VERSION ""

NS_ :

BS_:

BU_: HIB SaGE CBC DASM DIAGNOST EBCM ECM EPSB ESC ESL HALF HCP IC OCM ORC PTS RF_HUB SCCM

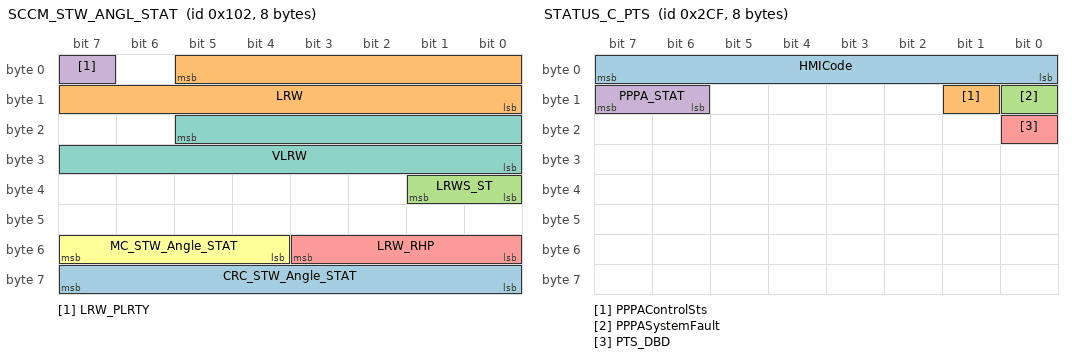
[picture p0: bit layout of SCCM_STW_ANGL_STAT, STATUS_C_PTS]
BO_ 258 SCCM_STW_ANGL_STAT: 8 SCCM
 SG_ CRC_STW_Angle_STAT : 56|8@1+ (1,0) [0|0] ""  DASM,ECM,ESC,ORC,PTS
 SG_ LRW : 5|14@0+ (0.5,-2048) [-2048|2047] "Degrees"  CBC,DASM,ECM,EPSB,ESC,HALF,ORC,PTS
 SG_ LRWS_ST : 32|2@1+ (1,0) [0|0] ""  CBC,DASM,ESC,HALF,ORC,PTS
 SG_ LRW_PLRTY : 7|1@1+ (1,0) [0|0] ""  DASM,ESC,HALF,ORC,PTS
 SG_ LRW_RHP : 48|4@1+ (0.1,-0.4) [-0.4|0.4] "Degrees"  EPSB,HALF,PTS
 SG_ MC_STW_Angle_STAT : 52|4@1+ (1,0) [0|15] ""  DASM,ECM,ESC,ORC,PTS
 SG_ VLRW : 21|14@0+ (0.5,-2048) [-2048|2047] "°/s"  DASM,ECM,EPSB,HALF

BO_ 1555 SD_RS_DASM: 8 DASM
 SG_ SD_RS_DASM : 7|64@0+ (1,0) [0|0] "" Vector__XXX

BO_ 1562 SD_RS_EPS: 8 EPSB
 SG_ SD_RS_EPS : 7|64@0+ (1,0) [0|0] "" Vector__XXX

BO_ 1572 SD_RS_HaLF: 8 HALF
 SG_ SD_RS_HaLF : 7|64@0+ (1,0) [0|0] "" Vector__XXX

BO_ 1570 SD_RS_PTS: 8 PTS
 SG_ SD_RS_PTS : 7|64@0+ (1,0) [0|0] "" Vector__XXX

BO_ 719 STATUS_C_PTS: 8 PTS
 SG_ HMICode : 0|8@1+ (1,0) [0|0] ""  IC
 SG_ PPPAControlSts : 9|1@1+ (1,0) [0|0] ""  ECM,IC
 SG_ PPPASystemFault : 8|1@1+ (1,0) [0|0] ""  IC
 SG_ PPPA_STAT : 14|2@1+ (1,0) [0|0] ""  CBC
 SG_ PTS_DBD : 16|1@1+ (1,0) [0|0] ""  IC

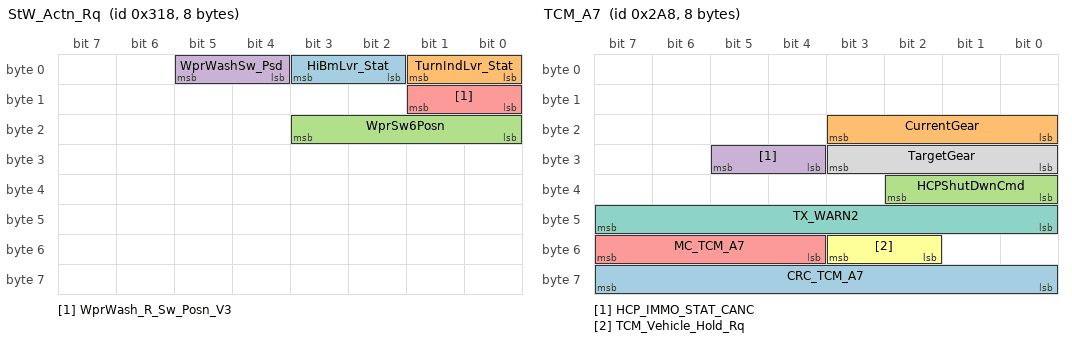
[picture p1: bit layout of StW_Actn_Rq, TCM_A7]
BO_ 792 StW_Actn_Rq: 8 SCCM
 SG_ HiBmLvr_Stat : 2|2@1+ (1,0) [0|0] ""  CBC
 SG_ TurnIndLvr_Stat : 0|2@1+ (1,0) [0|0] ""  CBC,DASM,HALF,PTS
 SG_ WprSw6Posn : 16|4@1+ (1,0) [0|0] ""  CBC,DASM
 SG_ WprWashSw_Psd : 4|2@1+ (1,0) [0|0] ""  CBC
 SG_ WprWash_R_Sw_Posn_V3 : 8|2@1+ (1,0) [0|0] ""  CBC

BO_ 680 TCM_A7: 8 HCP
 SG_ CRC_TCM_A7 : 56|8@1+ (1,0) [0|0] ""  DASM,ECM,ESC
 SG_ CurrentGear : 16|4@1+ (1,0) [0|0] "" Vector__XXX
 SG_ HCPShutDwnCmd : 32|3@1+ (1,0) [0|0] ""  CBC
 SG_ HCP_IMMO_STAT_CANC : 28|2@1+ (1,0) [0|0] ""  CBC,ECM
 SG_ MC_TCM_A7 : 52|4@1+ (1,0) [0|15] ""  DASM,ECM,ESC
 SG_ TCM_Vehicle_Hold_Rq : 50|2@1+ (1,0) [0|0] ""  ESC
 SG_ TX_WARN2 : 40|8@1+ (1,0) [0|0] ""  IC
 SG_ TargetGear : 24|4@1+ (1,0) [0|0] "" Vector__XXX

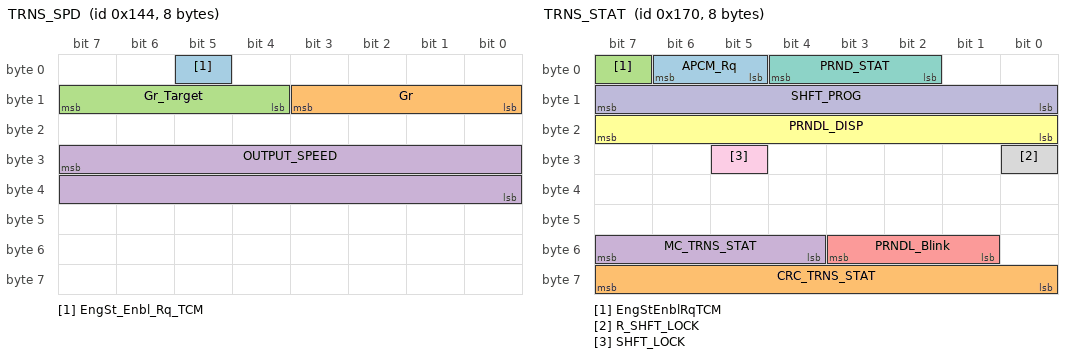
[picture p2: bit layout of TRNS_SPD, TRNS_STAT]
BO_ 324 TRNS_SPD: 8 HCP
 SG_ EngSt_Enbl_Rq_TCM : 5|1@1+ (1,0) [0|0] ""  ECM,RF_HUB
 SG_ Gr : 8|4@1+ (1,0) [0|0] ""  CBC,ECM,EPSB,ESC,HALF,IC,ORC,RF_HUB
 SG_ Gr_Target : 12|4@1+ (1,0) [0|0] ""  CBC,ECM,ESC
 SG_ OUTPUT_SPEED : 31|16@0+ (1,0) [0|65534] "rpm"  ECM

BO_ 368 TRNS_STAT: 8 HCP
 SG_ APCM_Rq : 5|2@1+ (1,0) [0|0] "" Vector__XXX
 SG_ CRC_TRNS_STAT : 56|8@1+ (1,0) [0|0] ""  DASM,ECM,ESC,PTS
 SG_ EngStEnblRqTCM : 7|1@1+ (1,0) [0|0] "" Vector__XXX
 SG_ MC_TRNS_STAT : 52|4@1+ (1,0) [0|15] ""  DASM,ECM,ESC,PTS
 SG_ PRNDL_Blink : 49|3@1+ (1,0) [0|0] ""  IC
 SG_ PRNDL_DISP : 16|8@1+ (1,0) [0|0] ""  CBC,ECM,ESC,IC,ORC
 SG_ PRND_STAT : 2|3@1+ (1,0) [0|0] ""  CBC,DASM,ECM,EPSB,ESC,IC,ORC,PTS
 SG_ R_SHFT_LOCK : 24|1@1+ (1,0) [0|0] "" Vector__XXX
 SG_ SHFT_LOCK : 29|1@1+ (1,0) [0|0] "" Vector__XXX
 SG_ SHFT_PROG : 8|8@1+ (1,0) [0|0] ""  ECM,ESC

BO_ 992 VIN: 8 ECM
 SG_ VIN_DATA : 15|56@0+ (1,0) [0|0] ""  CBC,DASM,EBCM,EPSB,ESC,ESL,HALF,HCP,IC,OCM,ORC,PTS,RF_HUB,SCCM
 SG_ VIN_MSG : 0|2@1+ (1,0) [0|0] ""  CBC,DASM,EBCM,EPSB,ESC,ESL,HALF,HCP,IC,OCM,ORC,PTS,RF_HUB,SCCM

BO_ 1000 VehCfg1: 8 CBC
 SG_ VC_AUTO_HB : 27|1@1+ (1,0) [0|0] ""  HALF,RF_HUB
 SG_ VC_BODY_STYLE : 28|4@1+ (1,0) [0|0] ""  DASM,EBCM,ECM,EPSB,ESC,ESL,HALF,HCP,IC,OCM,ORC,PTS,RF_HUB,SCCM
 SG_ VC_CHMCM_Prsnt : 61|1@1+ (1,0) [0|0] ""  RF_HUB
 SG_ VC_COUNTRY : 16|5@1+ (1,0) [0|0] ""  DASM,EBCM,ECM,EPSB,ESC,ESL,HALF,HCP,IC,OCM,ORC,PTS,RF_HUB,SCCM
 SG_ VC_EmodePrsnt : 26|1@1+ (1,0) [0|0] ""  RF_HUB
 SG_ VC_HDC_Prsnt : 62|1@1+ (1,0) [0|0] ""  RF_HUB
 SG_ VC_HdRstPrsnt : 56|1@1+ (1,0) [0|0] ""  RF_HUB
 SG_ VC_LHD_RHD : 21|2@1+ (1,0) [0|0] ""  ESC,HALF,IC,PTS,RF_HUB
 SG_ VC_MAX_VEH_SPD : 32|8@1+ (2,0) [0|506] "kph"  RF_HUB
 SG_ VC_MODEL_YEAR : 2|6@1+ (1,2000) [2000|2062] "model-year"  DASM,EBCM,ECM,EPSB,ESC,ESL,HALF,HCP,IC,OCM,ORC,PTS,RF_HUB,SCCM
 SG_ VC_PP_Prsnt : 47|1@1+ (1,0) [0|0] ""  RF_HUB
 SG_ VC_PTS_Config : 58|2@1+ (1,0) [0|0] ""  IC,RF_HUB
 SG_ VC_PTS_DispTyp : 44|3@1+ (1,0) [0|0] ""  RF_HUB
 SG_ VC_RVCM_Prsnt : 60|1@1+ (1,0) [0|0] ""  RF_HUB
 SG_ VC_RemStPrsnt : 23|1@1+ (1,0) [0|0] ""  HCP,IC,RF_HUB
 SG_ VC_SCR_Prsnt : 57|1@1+ (1,0) [0|0] ""  RF_HUB
 SG_ VC_SSC_Prsnt : 63|1@1+ (1,0) [0|0] ""  RF_HUB
 SG_ VC_ShftrTyp : 40|4@1+ (1,0) [0|0] ""  HCP,IC,RF_HUB
 SG_ VC_SpecialPKG : 48|8@1+ (1,0) [1|254] ""  RF_HUB
 SG_ VC_VEH_LINE : 8|8@1+ (1,0) [0|0] ""  DASM,EBCM,ECM,EPSB,ESC,ESL,HALF,HCP,IC,OCM,ORC,PTS,RF_HUB,SCCM
 SG_ VC_VehCfg1_Stat : 0|2@1+ (1,0) [0|0] ""  DASM,EBCM,ECM,EPSB,ESC,ESL,HALF,HCP,IC,OCM,ORC,PTS,RF_HUB,SCCM
 SG_ VC_XWD : 24|2@1+ (1,0) [0|0] ""  DASM,ESC,HALF,ORC,RF_HUB

BO_ 1001 VehCfg2: 8 CBC
 SG_ VC_AC_Prsnt : 11|1@1+ (1,0) [0|0] ""  RF_HUB
 SG_ VC_CRUISE_PRSNT : 12|1@1+ (1,0) [0|0] ""  DASM,HCP,ORC,RF_HUB,SCCM
 SG_ VC_DRVMD_Prsnt : 25|1@1+ (1,0) [0|0] ""  RF_HUB
 SG_ VC_ECO_Indicator : 24|1@1+ (1,0) [0|0] ""  RF_HUB
 SG_ VC_ESCDrvMd_Prsnt : 27|1@1+ (1,0) [0|0] ""  RF_HUB
 SG_ VC_EngPowerDrvMd_Prsnt : 28|1@1+ (1,0) [0|0] ""  RF_HUB
 SG_ VC_FG_PRSNT : 13|1@1+ (1,0) [0|0] ""  RF_HUB
 SG_ VC_FULL_SPARE : 14|1@1+ (1,0) [0|0] ""  RF_HUB
 SG_ VC_LgtLdPressFtTr : 56|8@1+ (1,0) [0|126] "psi"  RF_HUB
 SG_ VC_LgtLdPressRrTr : 48|8@1+ (1,0) [0|126] "psi"  RF_HUB
 SG_ VC_MaseratiMd : 6|2@1+ (1,0) [0|0] ""  RF_HUB
 SG_ VC_MaxLdPressFtTr : 40|8@1+ (1,0) [0|126] "psi"  IC,RF_HUB
 SG_ VC_MaxLdPressRrTr : 32|8@1+ (1,0) [0|126] "psi"  IC,RF_HUB
 SG_ VC_MemoryDRVMD_Prsnt : 26|1@1+ (1,0) [0|0] ""  RF_HUB
 SG_ VC_OffRoad : 15|1@1+ (1,0) [0|0] ""  RF_HUB
 SG_ VC_PADS_Prsnt : 8|1@1+ (1,0) [0|0] ""  ORC,RF_HUB
 SG_ VC_PwrIvtrTyp : 2|2@1+ (1,0) [0|0] ""  RF_HUB
 SG_ VC_RainSnsPrsnt : 9|1@1+ (1,0) [0|0] ""  RF_HUB
 SG_ VC_RunFlatTirePrsnt : 5|1@1+ (1,0) [0|0] ""  RF_HUB
 SG_ VC_SKIM_PRSNT : 10|1@1+ (1,0) [0|0] ""  RF_HUB
 SG_ VC_SecPrkPrsnt : 29|1@1+ (1,0) [0|0] ""  RF_HUB
 SG_ VC_ShftInd_Prsnt : 30|2@1+ (1,0) [0|0] ""  RF_HUB
 SG_ VC_SpecialPKG_IC : 16|8@1+ (1,0) [0|0] ""  ORC,RF_HUB
 SG_ VC_ThatchamPrsnt : 4|1@1+ (1,0) [0|0] ""  RF_HUB
 SG_ VC_VehCfg2_Stat : 0|2@1+ (1,0) [0|0] ""  DASM,ECM,EPSB,ESC,HCP,IC,ORC,RF_HUB,SCCM

BO_ 1002 VehCfg3: 8 CBC
 SG_ VC_ADJ_PDL_PRSNT : 26|1@1+ (1,0) [0|0] ""  RF_HUB
 SG_ VC_AUTO_HL : 27|1@1+ (1,0) [0|0] ""  RF_HUB
 SG_ VC_AutoParkPrsnt : 61|1@1+ (1,0) [0|0] ""  RF_HUB
 SG_ VC_Base_TPM : 57|1@1+ (1,0) [0|0] ""  IC,ORC,RF_HUB
 SG_ VC_CMP_DISP : 48|1@1+ (1,0) [0|0] ""  IC,RF_HUB
 SG_ VC_CMS : 55|1@1+ (1,0) [0|0] ""  DASM,ESC,HALF,ORC,RF_HUB
 SG_ VC_ChassisType : 32|7@1+ (1,0) [0|126] ""  ESC,HALF,RF_HUB
 SG_ VC_DSBL_CLK_DISP : 31|1@1+ (1,0) [0|0] ""  RF_HUB
 SG_ VC_DrAlrPrsnt : 28|1@1+ (1,0) [0|0] ""  RF_HUB
 SG_ VC_DualFuelSens : 29|1@1+ (1,0) [0|0] ""  IC,RF_HUB
 SG_ VC_ELV_Prsnt : 15|1@1+ (1,0) [0|0] ""  RF_HUB
 SG_ VC_ESCL_PRSNT : 50|1@1+ (1,0) [0|0] ""  RF_HUB
 SG_ VC_FCW : 56|1@1+ (1,0) [0|0] ""  DASM,ESC,HALF,ORC,RF_HUB
 SG_ VC_FOBIKsafeENBL : 14|1@1+ (1,0) [0|0] ""  RF_HUB
 SG_ VC_FUEL_CAP : 16|8@1+ (1,36) [36|290] "liters"  IC,RF_HUB
 SG_ VC_HID_HL : 51|1@1+ (1,0) [0|0] ""  RF_HUB
 SG_ VC_HVAC_Config : 40|4@1+ (1,0) [0|0] ""  RF_HUB
 SG_ VC_IntEC_MIRR : 49|1@1+ (1,0) [0|0] ""  RF_HUB
 SG_ VC_KG_Prsnt : 63|1@1+ (1,0) [0|0] ""  IC,RF_HUB
 SG_ VC_Liftgate_Trunk : 53|2@1+ (1,0) [0|0] ""  IC,RF_HUB
 SG_ VC_PDDL_PRSNT : 59|1@1+ (1,0) [0|0] ""  RF_HUB
 SG_ VC_PE_Prsnt : 62|1@1+ (1,0) [0|0] ""  RF_HUB
 SG_ VC_POLICE : 2|1@1+ (1,0) [0|0] ""  ORC,RF_HUB
 SG_ VC_PWR_LFT_GT : 3|1@1+ (1,0) [0|0] ""  RF_HUB
 SG_ VC_PWR_LT_SLDR : 5|1@1+ (1,0) [0|0] ""  RF_HUB
 SG_ VC_PWR_RT_SLDR : 4|1@1+ (1,0) [0|0] ""  RF_HUB
 SG_ VC_Prem_TPM : 58|1@1+ (1,0) [0|0] ""  IC,ORC,RF_HUB
 SG_ VC_RKE_PRSNT : 6|1@1+ (1,0) [0|0] ""  RF_HUB
 SG_ VC_SPORT_PRSNT : 60|1@1+ (1,0) [0|0] ""  RF_HUB
 SG_ VC_SRT_PRSNT : 30|1@1+ (1,0) [0|0] ""  ORC,RF_HUB
 SG_ VC_SecLkPrsnt : 52|1@1+ (1,0) [0|0] ""  RF_HUB
 SG_ VC_SunShade_Present : 7|1@1+ (1,0) [0|0] ""  RF_HUB
 SG_ VC_TEMP_DISP : 39|1@1+ (1,0) [0|0] ""  IC,RF_HUB
 SG_ VC_TcaseTyp : 8|4@1+ (1,0) [0|0] ""  ESC,RF_HUB
 SG_ VC_VEH_BRAND : 44|4@1+ (1,0) [0|0] ""  HALF,PTS,RF_HUB
 SG_ VC_VehCfg3_Stat : 0|2@1+ (1,0) [0|0] ""  DASM,ECM,EPSB,ESC,HALF,HCP,IC,ORC,PTS,RF_HUB,SCCM
 SG_ VC_WHL_BASE : 12|2@1+ (1,0) [0|0] ""  IC,RF_HUB
 SG_ VC_WIN_EXPR_FEAT : 24|2@1+ (1,0) [0|0] ""  RF_HUB

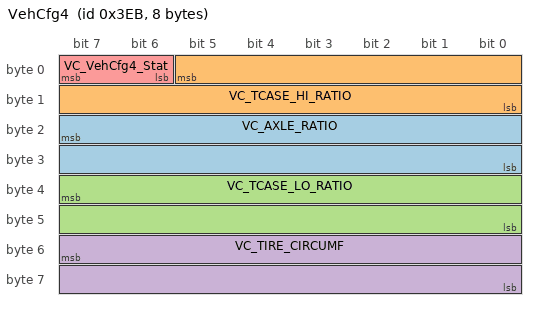
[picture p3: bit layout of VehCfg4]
BO_ 1003 VehCfg4: 8 CBC
 SG_ VC_AXLE_RATIO : 23|16@0+ (0.001,0) [0|65.534] ""  DASM,ESC,RF_HUB
 SG_ VC_TCASE_HI_RATIO : 5|14@0+ (0.001,0) [0|16.382] ""  ESC,RF_HUB
 SG_ VC_TCASE_LO_RATIO : 39|16@0+ (0.001,0) [0|65.534] ""  ESC,RF_HUB
 SG_ VC_TIRE_CIRCUMF : 55|16@0+ (1,0) [0|65534] "mm"  EPSB,ESC,HALF,ORC,PTS,RF_HUB
 SG_ VC_VehCfg4_Stat : 6|2@1+ (1,0) [0|0] ""  DASM,ECM,EPSB,ESC,HALF,HCP,ORC,PTS,RF_HUB

BO_ 1098 VehCfg5: 8 CBC
 SG_ VC_AmbLtgPrsnt : 61|1@1+ (1,0) [0|0] ""  RF_HUB
 SG_ VC_AmbTempLct : 6|2@1+ (1,0) [0|0] ""  RF_HUB
 SG_ VC_ChildDisp_Prsnt : 59|1@1+ (1,0) [0|0] ""  RF_HUB
 SG_ VC_LUCI_PRSNT : 2|1@1+ (1,0) [0|0] ""  RF_HUB
 SG_ VC_NonReg_TPIS : 4|1@1+ (1,0) [0|0] ""  RF_HUB
 SG_ VC_OffRoadPg : 60|1@1+ (1,0) [0|0] ""  RF_HUB
 SG_ VC_PPPA_Prsnt : 62|1@1+ (1,0) [0|0] ""  EPSB,IC,PTS,RF_HUB
 SG_ VC_ParkStopPrsnt : 63|1@1+ (1,0) [0|0] ""  ESC,IC,RF_HUB
 SG_ VC_RR_DuallyPrsnt : 3|1@1+ (1,0) [0|0] ""  RF_HUB
 SG_ VC_RearDoorLocks2DCM : 56|1@1+ (1,0) [0|0] ""  RF_HUB
 SG_ VC_SBR_Prsnt : 58|1@1+ (1,0) [0|0] ""  RF_HUB
 SG_ VC_SpdLmt_PRSNT : 57|1@1+ (1,0) [0|0] ""  DASM,RF_HUB,SCCM
 SG_ VC_Strng_Rt_0 : 8|8@1+ (0.1,0) [0|25.4] ""  ESC,RF_HUB
 SG_ VC_Strng_Rt_pls1 : 16|8@1+ (0.1,0) [0|25.4] ""  ESC,RF_HUB
 SG_ VC_Strng_Rt_pls2 : 24|8@1+ (0.1,0) [0|25.4] ""  ESC,RF_HUB
 SG_ VC_Strng_Rt_pls3 : 32|8@1+ (0.1,0) [0|25.4] ""  ESC,RF_HUB
 SG_ VC_Strng_Rt_pls4 : 40|8@1+ (0.1,0) [0|25.4] ""  ESC,RF_HUB
 SG_ VC_Strng_Rt_pls5 : 48|8@1+ (0.1,0) [0|25.4] ""  ESC,RF_HUB
 SG_ VC_VehCfg5_Stat : 0|2@1+ (1,0) [0|0] ""  DASM,ECM,EPSB,ESC,IC,ORC,PTS,RF_HUB,SCCM
 SG_ VC_WTS_Prsnt : 5|1@1+ (1,0) [0|0] ""  RF_HUB

BO_ 897 VehCfg7: 8 CBC
 SG_ VC_ABSM : 25|1@1+ (1,0) [0|0] ""  RF_HUB
 SG_ VC_ACC_Type : 19|2@1+ (1,0) [0|0] ""  DASM,ECM,ESC,HALF,IC,ORC,PTS,RF_HUB
 SG_ VC_AS_ERS : 14|2@1+ (1,0) [0|0] ""  RF_HUB
 SG_ VC_AxleLockerPrsnt : 26|2@1+ (1,0) [0|0] ""  RF_HUB
 SG_ VC_DST_Present : 5|1@1+ (1,0) [0|0] ""  RF_HUB
 SG_ VC_DampingPrsnt : 22|1@1+ (1,0) [0|0] ""  RF_HUB
 SG_ VC_FullSpeedRange_FCW : 18|1@1+ (1,0) [0|0] ""  DASM,ESC,HALF,RF_HUB
 SG_ VC_HybridType : 36|3@1+ (1,0) [0|0] ""  DASM,ECM,EPSB,ESC,HALF,IC,ORC,PTS,RF_HUB
 SG_ VC_LDW : 2|1@1+ (1,0) [0|0] ""  HALF,IC,ORC,RF_HUB
 SG_ VC_PBTyp : 29|3@1+ (1,0) [0|0] ""  ESC,ORC,PTS,RF_HUB
 SG_ VC_PdlsMdPrsnt : 4|1@1+ (1,0) [0|0] ""  RF_HUB
 SG_ VC_RedKey : 24|1@1+ (1,0) [0|0] ""  RF_HUB
 SG_ VC_STP_PRSNT : 6|1@1+ (1,0) [0|0] ""  RF_HUB
 SG_ VC_SUNR_Prsnt : 47|1@1+ (1,0) [0|0] ""  RF_HUB
 SG_ VC_SVC_Prsnt : 17|1@1+ (1,0) [0|0] ""  RF_HUB
 SG_ VC_SuspPrsnt : 21|1@1+ (1,0) [0|0] ""  RF_HUB
 SG_ VC_TPMS_Configuration : 32|3@1+ (1,0) [0|0] ""  IC,RF_HUB
 SG_ VC_TSBM_Prsnt : 39|1@1+ (1,0) [0|0] ""  RF_HUB
 SG_ VC_TeenKey : 16|1@1+ (1,0) [0|0] ""  DASM,ECM,IC,PTS,RF_HUB
 SG_ VC_Temp_Display_Resolution : 42|1@1+ (1,0) [0|0] ""  RF_HUB
 SG_ VC_TransType : 8|6@1+ (1,0) [0|0] ""  ESC,IC,RF_HUB
 SG_ VC_Trans_Equipped : 28|1@1+ (1,0) [0|0] ""  EPSB,ESC,HALF,IC,ORC,PTS,RF_HUB
 SG_ VC_Trans_N_Hold_Prsnt : 23|1@1+ (1,0) [0|0] ""  RF_HUB
 SG_ VC_TrnsDrvMdPrsnt : 3|1@1+ (1,0) [0|0] ""  RF_HUB
 SG_ VC_VehCfg7_Stat : 0|2@1+ (1,0) [0|0] ""  DASM,ECM,EPSB,HALF,IC,ORC,PTS,RF_HUB
 SG_ VC_eShifter_Prsnt : 7|1@1+ (1,0) [0|0] ""  ESC,RF_HUB

CM_ SG_ 258 CRC_STW_Angle_STAT "CRC-checksum byte 1 to 7 according to SAE J1850";
CM_ SG_ 258 LRW "Steering wheel angle";
CM_ SG_ 258 LRWS_ST "Steering wheel angle sensor status";
CM_ SG_ 258 LRW_PLRTY "Steering angle polarity (0=ISO 8855 Polarity and CCW = Positive)";
CM_ SG_ 258 LRW_RHP "Steering wheel angle remainder high precision";
CM_ SG_ 258 MC_STW_Angle_STAT "Message counter";
CM_ SG_ 258 VLRW "Delta steering wheel angle";
CM_ SG_ 1555 SD_RS_DASM "Response on Event - light";
CM_ SG_ 1562 SD_RS_EPS "Response on Event - light";
CM_ SG_ 1572 SD_RS_HaLF "Response on Event - light";
CM_ SG_ 1570 SD_RS_PTS "Response on Event - light";
CM_ SG_ 719 HMICode "HMI codes to be displayed";
CM_ SG_ 719 PPPAControlSts "Indicates the active state of PPPA; active = [1]";
CM_ SG_ 719 PPPASystemFault "Indicates the fail status of PPPA; true = [1]";
CM_ SG_ 719 PPPA_STAT "Parallel & perpendicular park assist switch status";
CM_ SG_ 719 PTS_DBD "Park assist system disabled; System_Disabled = [1]";
CM_ SG_ 792 HiBmLvr_Stat "High beam lever state";
CM_ SG_ 792 TurnIndLvr_Stat "Turn indicator lever state";
CM_ SG_ 792 WprSw6Posn "Wiper switch (6 stages) position";
CM_ SG_ 792 WprWashSw_Psd "Front wiper switch pressed";
CM_ SG_ 792 WprWash_R_Sw_Posn_V3 "Backlite wiper/washer switch position";
CM_ SG_ 680 CRC_TCM_A7 "CRC-checksum byte 1 to 7 according to SAE J1850";
CM_ SG_ 680 CurrentGear "Current Gear";
CM_ SG_ 680 HCPShutDwnCmd "HCP System Shutdown Command";
CM_ SG_ 680 HCP_IMMO_STAT_CANC "Communicates immobilizer handshake status to BCM";
CM_ SG_ 680 MC_TCM_A7 "Message counter";
CM_ SG_ 680 TCM_Vehicle_Hold_Rq "Transmission request to hold the vehicle/apply the park brake";
CM_ SG_ 680 TX_WARN2 "Transmission warning #2";
CM_ SG_ 680 TargetGear "Target Gear - protected";
CM_ SG_ 324 EngSt_Enbl_Rq_TCM "Enable engine start request";
CM_ SG_ 324 Gr "Current Gear";
CM_ SG_ 324 Gr_Target "Target Gear";
CM_ SG_ 324 OUTPUT_SPEED "Output Shaft Speed";
CM_ SG_ 368 APCM_Rq "Auto position correction mode request";
CM_ SG_ 368 CRC_TRNS_STAT "CRC-checksum byte 1 to 7 according to SAE J1850";
CM_ SG_ 368 EngStEnblRqTCM "Engine start enable request from the transmission";
CM_ SG_ 368 MC_TRNS_STAT "Message counter";
CM_ SG_ 368 PRNDL_Blink "Request gear shift display indicator blink";
CM_ SG_ 368 PRNDL_DISP "PRNDL display request";
CM_ SG_ 368 PRND_STAT "PRND Status";
CM_ SG_ 368 R_SHFT_LOCK "Shiftlock for reverse; locked = [1]";
CM_ SG_ 368 SHFT_LOCK "Shiftlock state locked; false = [1]";
CM_ SG_ 368 SHFT_PROG "Driving program display code";
CM_ SG_ 992 VIN_DATA "VIN Digits (8 bit ascii encoded) - see Signal Description Doc for details";
CM_ SG_ 992 VIN_MSG "VIN Message Information";
CM_ SG_ 1000 VC_AUTO_HB "Auto Highbeam feature present; present = [1]";
CM_ SG_ 1000 VC_BODY_STYLE "Body style";
CM_ SG_ 1000 VC_CHMCM_Prsnt "CHMSL camera (1=present)";
CM_ SG_ 1000 VC_COUNTRY "Country Code";
CM_ SG_ 1000 VC_EmodePrsnt "E-Mode feature present; True = [1]";
CM_ SG_ 1000 VC_HDC_Prsnt "Hill descent feature is present; present = [1]";
CM_ SG_ 1000 VC_HdRstPrsnt "Headrest present; present = [1]";
CM_ SG_ 1000 VC_LHD_RHD "Left/right hand drive";
CM_ SG_ 1000 VC_MAX_VEH_SPD "Maximum vehicle speed";
CM_ SG_ 1000 VC_MODEL_YEAR "Model year";
CM_ SG_ 1000 VC_PP_Prsnt "Performance Pages Present (1=present)";
CM_ SG_ 1000 VC_PTS_Config "Parktronics system configuration";
CM_ SG_ 1000 VC_PTS_DispTyp "PTS display type and location";
CM_ SG_ 1000 VC_RVCM_Prsnt "Rear view camera (1=present)";
CM_ SG_ 1000 VC_RemStPrsnt "Remote start present; present = [1]";
CM_ SG_ 1000 VC_SCR_Prsnt "Urea/SCR system present; present = [1]";
CM_ SG_ 1000 VC_SSC_Prsnt "Select speed control feature is present; present = [1]";
CM_ SG_ 1000 VC_ShftrTyp "Shifter type";
CM_ SG_ 1000 VC_SpecialPKG "Special sales code package";
CM_ SG_ 1000 VC_VEH_LINE "Vehicle line";
CM_ SG_ 1000 VC_VehCfg1_Stat "Configuration messages status 1";
CM_ SG_ 1000 VC_XWD "Drive configuration";
CM_ SG_ 1001 VC_AC_Prsnt "Vehicle is equipped with air conditioning; present = [1]";
CM_ SG_ 1001 VC_CRUISE_PRSNT "Cruise feature is present; present = [1]";
CM_ SG_ 1001 VC_DRVMD_Prsnt "Drive mode feature configuration (1 = Present)";
CM_ SG_ 1001 VC_ECO_Indicator "ECO Indicator present on vehicle; True = [1]";
CM_ SG_ 1001 VC_ESCDrvMd_Prsnt "ESC drive mode sub-feature configuration (1 = Present)";
CM_ SG_ 1001 VC_EngPowerDrvMd_Prsnt "ECM drive mode sub-feature configuration (1 = Present)";
CM_ SG_ 1001 VC_FG_PRSNT "Flipper glass present; present = [1]";
CM_ SG_ 1001 VC_FULL_SPARE "Full size spare; present = [1]";
CM_ SG_ 1001 VC_LgtLdPressFtTr "Light Load Inflation Pressure Front Tire";
CM_ SG_ 1001 VC_LgtLdPressRrTr "Light Load Inflation Pressure Rear Tire";
CM_ SG_ 1001 VC_MaseratiMd "Maserati vehicle mode";
CM_ SG_ 1001 VC_MaxLdPressFtTr "Max Load Inflation Pressure Front Tire";
CM_ SG_ 1001 VC_MaxLdPressRrTr "Max Load Inflation Pressure Rear Tire";
CM_ SG_ 1001 VC_MemoryDRVMD_Prsnt "Memory drive mode sub-feature configuration (1 = Present)";
CM_ SG_ 1001 VC_OffRoad "Off road capable; present = [1]";
CM_ SG_ 1001 VC_PADS_Prsnt "Pass. airbag disable switch present; present = [1]";
CM_ SG_ 1001 VC_PwrIvtrTyp "Power inverter type";
CM_ SG_ 1001 VC_RainSnsPrsnt "Rain sensor present; present = [1]";
CM_ SG_ 1001 VC_RunFlatTirePrsnt "Run flat tires present; present = [1]";
CM_ SG_ 1001 VC_SKIM_PRSNT "SKIM system present; present = [1]";
CM_ SG_ 1001 VC_SecPrkPrsnt "Secure park feature present; present = [1]";
CM_ SG_ 1001 VC_ShftInd_Prsnt "Configuration for performance & gear shift indication";
CM_ SG_ 1001 VC_SpecialPKG_IC "Special sales code package";
CM_ SG_ 1001 VC_ThatchamPrsnt "Thatcham present; present = [1]";
CM_ SG_ 1001 VC_VehCfg2_Stat "Configuration messages status 2";
CM_ SG_ 1002 VC_ADJ_PDL_PRSNT "Adjustable pedal system present (non-memory); present = [1]";
CM_ SG_ 1002 VC_AUTO_HL "Auto headlamp feature present; present = [1]";
CM_ SG_ 1002 VC_AutoParkPrsnt "Automatic transmission parking feature is present; present = [1]";
CM_ SG_ 1002 VC_Base_TPM "Base TPM system present; present = [1]";
CM_ SG_ 1002 VC_CMP_DISP "Display compass heading present; present = [1]";
CM_ SG_ 1002 VC_CMS "Collision Mitigation System present; present = [1]";
CM_ SG_ 1002 VC_ChassisType "Chassis type (including suspension, brakes, and tires)";
CM_ SG_ 1002 VC_DSBL_CLK_DISP "Disable display of radio clock; 1 = clock display disabled";
CM_ SG_ 1002 VC_DrAlrPrsnt "Door alert feature present; present = [1]";
CM_ SG_ 1002 VC_DualFuelSens "Vehicle equipped with two fuel sending units; present = [1]";
CM_ SG_ 1002 VC_ELV_Prsnt "ELV system present; enabled=[1], disabled=[0]";
CM_ SG_ 1002 VC_ESCL_PRSNT "ESCL system present; enabled=[1], disabled=[0]";
CM_ SG_ 1002 VC_FCW "Forward Collision Warning present; present = [1]";
CM_ SG_ 1002 VC_FOBIKsafeENBL "Feature FOBIK safe is enabled; present = [1]";
CM_ SG_ 1002 VC_FUEL_CAP "Fuel capacity";
CM_ SG_ 1002 VC_HID_HL "High intensity discharge head lamps; present = [1]";
CM_ SG_ 1002 VC_HVAC_Config "HVAC Configuration";
CM_ SG_ 1002 VC_IntEC_MIRR "Vehicle is equipped with an interior EC mirror; present = [1]";
CM_ SG_ 1002 VC_KG_Prsnt "Feature keyless go is present; present = [1]";
CM_ SG_ 1002 VC_Liftgate_Trunk "Liftgate or trunk";
CM_ SG_ 1002 VC_PDDL_PRSNT "Paddle shift feature is present; present = [1]";
CM_ SG_ 1002 VC_PE_Prsnt "Feature passive entry is present; present = [1]";
CM_ SG_ 1002 VC_POLICE "Police lighting feature; present = [1]";
CM_ SG_ 1002 VC_PWR_LFT_GT "Power lift gate present; present = [1]";
CM_ SG_ 1002 VC_PWR_LT_SLDR "Power left sliding door present; present = [1]";
CM_ SG_ 1002 VC_PWR_RT_SLDR "Power right sliding door present; present = [1]";
CM_ SG_ 1002 VC_Prem_TPM "Premium TPM system present; present = [1]";
CM_ SG_ 1002 VC_RKE_PRSNT "RKE system present; present = [1]";
CM_ SG_ 1002 VC_SPORT_PRSNT "Sport mode is present; present = [1]";
CM_ SG_ 1002 VC_SRT_PRSNT "Vehicle is an SRT; present = [1]";
CM_ SG_ 1002 VC_SecLkPrsnt "Secondary Lock Present; [1] = True";
CM_ SG_ 1002 VC_SunShade_Present "Vehicle equipped w/SunShade (1=present)";
CM_ SG_ 1002 VC_TEMP_DISP "Display outside temperature present; present = [1]";
CM_ SG_ 1002 VC_TcaseTyp "Tcase type";
CM_ SG_ 1002 VC_VEH_BRAND "Vehicle brand type";
CM_ SG_ 1002 VC_VehCfg3_Stat "Configuration messages status 3";
CM_ SG_ 1002 VC_WHL_BASE "Wheel base";
CM_ SG_ 1002 VC_WIN_EXPR_FEAT "Window express feature configuration";
CM_ SG_ 1003 VC_AXLE_RATIO "Axle ratio";
CM_ SG_ 1003 VC_TCASE_HI_RATIO "Transfer case high ratio";
CM_ SG_ 1003 VC_TCASE_LO_RATIO "Transfer case low range reduction ratio";
CM_ SG_ 1003 VC_TIRE_CIRCUMF "Dynamic tire circumference (all or rear)";
CM_ SG_ 1003 VC_VehCfg4_Stat "Configuration messages status 4";
CM_ SG_ 1098 VC_AmbLtgPrsnt "Ambient lighting feature is present; True = [1]";
CM_ SG_ 1098 VC_AmbTempLct "Ambient temperature sensor location";
CM_ SG_ 1098 VC_ChildDisp_Prsnt "Child display feature is present; True = 1";
CM_ SG_ 1098 VC_LUCI_PRSNT "Luci feature present; present = [1]";
CM_ SG_ 1098 VC_NonReg_TPIS "Non-regulated tire pressure indicator system; True = 1";
CM_ SG_ 1098 VC_OffRoadPg "Off road pages present; True = [1]";
CM_ SG_ 1098 VC_PPPA_Prsnt "Semi automatic parking system present; present = [1]";
CM_ SG_ 1098 VC_ParkStopPrsnt "Park with stop is present; True = 1";
CM_ SG_ 1098 VC_RR_DuallyPrsnt "Vehicle is equipped with rear duals; present = [1]";
CM_ SG_ 1098 VC_RearDoorLocks2DCM "Rear door lock switch present; present = [1]";
CM_ SG_ 1098 VC_SBR_Prsnt "Seat belt reminder module is present; True = 1";
CM_ SG_ 1098 VC_SpdLmt_PRSNT "Speed limiter is present; present = [1]";
CM_ SG_ 1098 VC_Strng_Rt_0 "Steering Ratio at zero";
CM_ SG_ 1098 VC_Strng_Rt_pls1 "Steering Ratio at positve angle 1";
CM_ SG_ 1098 VC_Strng_Rt_pls2 "Steering Ratio at positve angle 2";
CM_ SG_ 1098 VC_Strng_Rt_pls3 "Steering Ratio at positve angle 3";
CM_ SG_ 1098 VC_Strng_Rt_pls4 "Steering Ratio at positve angle 4";
CM_ SG_ 1098 VC_Strng_Rt_pls5 "Steering Ratio at positve angle 5";
CM_ SG_ 1098 VC_VehCfg5_Stat "Configuration messages status 5";
CM_ SG_ 1098 VC_WTS_Prsnt "Wait to start feature is present; present = [1]";
CM_ SG_ 897 VC_ABSM "Active Blind Spot present; present = [1]";
CM_ SG_ 897 VC_ACC_Type "Type of adaptive cruise control (ACC) system present";
CM_ SG_ 897 VC_AS_ERS "Shift feature autostick / electronic range select status";
CM_ SG_ 897 VC_AxleLockerPrsnt "Axle locker configuration";
CM_ SG_ 897 VC_DST_Present "Dynamic steering torque present; True = [1]";
CM_ SG_ 897 VC_DampingPrsnt "NetCfg_ASCM contains active damping; present = [1]";
CM_ SG_ 897 VC_FullSpeedRange_FCW "Full speed range forward collision warning plus system present; Present = 1";
CM_ SG_ 897 VC_HybridType "Identify the kind of hybrid vehicle";
CM_ SG_ 897 VC_LDW "Lane Departure Warning present; present = [1]";
CM_ SG_ 897 VC_PBTyp "Park brake type";
CM_ SG_ 897 VC_PdlsMdPrsnt "Paddles lock-out feature; present = [1]";
CM_ SG_ 897 VC_RedKey "RedKey feature is present; Present = [1]";
CM_ SG_ 897 VC_STP_PRSNT "Super trac pack present; True = [1]";
CM_ SG_ 897 VC_SUNR_Prsnt "Sunroof is present; True = 1";
CM_ SG_ 897 VC_SVC_Prsnt "Surround view camera; present = [1]";
CM_ SG_ 897 VC_SuspPrsnt "NetCfg_ASCM contains suspension; present = [1]";
CM_ SG_ 897 VC_TPMS_Configuration "TPMS configuration";
CM_ SG_ 897 VC_TSBM_Prsnt "TSBM LIN slave is present; True = [1]";
CM_ SG_ 897 VC_TeenKey "TeenKey feature is present; Present = [1]";
CM_ SG_ 897 VC_Temp_Display_Resolution "Toggle between 0.5degC and 1degC temperature display";
CM_ SG_ 897 VC_TransType "Automatic transmission type";
CM_ SG_ 897 VC_Trans_Equipped "Transmission equipped: 0 = Automatic & 1 = Manual";
CM_ SG_ 897 VC_Trans_N_Hold_Prsnt "Transmission neutral hold feature; present = [1]";
CM_ SG_ 897 VC_TrnsDrvMdPrsnt "Transmission drive mode feature; present = [1]";
CM_ SG_ 897 VC_VehCfg7_Stat "Configuration messages status 7";
CM_ SG_ 897 VC_eShifter_Prsnt "e-shifter present; present = [1]";
BA_DEF_ BO_  "App-Botschaft" ENUM  "nein","ja";
BA_DEF_ BO_  "CanMsgMinLen" INT 0 8;
BA_DEF_ BO_  "DiagRequest" ENUM  "nein","ja";
BA_DEF_ BO_  "DiagResponse" ENUM  "nein","ja";
BA_DEF_ BO_  "DiagState" ENUM  "nein","ja";
BA_DEF_ BO_  "GenMsgCycleTime" INT 0 65535;
BA_DEF_ BO_  "GenMsgCycleTimeActive" INT 0 65535;
BA_DEF_ BO_  "GenMsgDelayTime" INT 0 65535;
BA_DEF_ BO_  "GenMsgNrOfRepetitions" INT 0 65535;
BA_DEF_ BO_  "GenMsgSendType" ENUM  "cyclicX","spontanX","cyclicIfActiveX","spontanWithDelay","cyclicAndSpontanX","cyclicAndSpontanWithDelay","spontanWithRepitition","cyclicIfActiveAndSpontanWD","cyclicIfActiveFast","cyclicWithRepeatOnDemand","none";
BA_DEF_ BO_  "GenMsgStartDelayTime" INT 0 65535;
BA_DEF_ BO_  "GenMsgStartValue" STRING ;
BA_DEF_ BO_  "NWM-Botschaft" ENUM  "nein","ja";
BA_DEF_ BO_  "TpTxIndex" INT 0 99;
BA_DEF_ SG_  "FlexKomComment" STRING ;
BA_DEF_ SG_  "FlexKomIsMotorola" ENUM  "nein","ja";
BA_DEF_ SG_  "FlexKomSID" INT 0 2147483647;
BA_DEF_ SG_  "FlexKomSigLaenge" INT 0 64;
BA_DEF_ SG_  "FlexKomSigName" STRING ;
BA_DEF_ SG_  "FlexKomSigStartPos" INT 0 63;
BA_DEF_ SG_  "FlexKomSigStartValue" STRING ;
BA_DEF_ SG_  "GenSigCycleTime" INT 0 65535;
BA_DEF_ SG_  "GenSigCycleTimeActive" INT 0 65535;
BA_DEF_ SG_  "GenSigSendType" ENUM  "cyclicX","spontanX","cyclicIfActiveX","spontanWithDelay","cyclicAndSpontanX","cyclicAndSpontanWithDelay","spontanWithRepitition","cyclicIfActiveAndSpontanWD","cyclicIfActiveFast","cyclicWithRepeatOnDemand","none";
BA_DEF_ SG_  "GenSigSNA" STRING ;
BA_DEF_ SG_  "GenSigStartValue" HEX 0 2147483648;
BA_DEF_ SG_  "GenSigTimeout_CBC" INT 0 65535;
BA_DEF_ SG_  "GenSigTimeout_EPS" INT 0 65535;
BA_DEF_ SG_  "GenSigTimeout_ESC" INT 0 65535;
BA_DEF_ SG_  "GenSigTimeout_ESL" INT 0 65535;
BA_DEF_ SG_  "GenSigTimeout_RHSC2" INT 0 65535;
BA_DEF_ SG_  "GenSigTimeout_ETM" INT 0 65535;
BA_DEF_ SG_  "GenSigTimeout_HaLF" INT 0 65535;
BA_DEF_ SG_  "GenSigTimeout_IC" INT 0 65535;
BA_DEF_ SG_  "GenSigTimeout_OCM" INT 0 65535;
BA_DEF_ SG_  "GenSigTimeout_ORC" INT 0 65535;
BA_DEF_ SG_  "GenSigTimeout_PTS" INT 0 65535;
BA_DEF_ SG_  "GenSigTimeout_RF_HUB" INT 0 65535;
BA_DEF_ SG_  "GenSigTimeout_SCCM" INT 0 65535;
BA_DEF_ SG_  "RID" STRING ;
BA_DEF_DEF_  "App-Botschaft" "nein";
BA_DEF_DEF_  "CanMsgMinLen" 0;
BA_DEF_DEF_  "DiagRequest" "nein";
BA_DEF_DEF_  "DiagResponse" "nein";
BA_DEF_DEF_  "DiagState" "nein";
BA_DEF_DEF_  "GenMsgCycleTime" 0;
BA_DEF_DEF_  "GenMsgCycleTimeActive" 0;
BA_DEF_DEF_  "GenMsgDelayTime" 0;
BA_DEF_DEF_  "GenMsgNrOfRepetitions" 0;
BA_DEF_DEF_  "GenMsgSendType" "cyclicX";
BA_DEF_DEF_  "GenMsgStartDelayTime" 0;
BA_DEF_DEF_  "GenMsgStartValue" "";
BA_DEF_DEF_  "NWM-Botschaft" "nein";
BA_DEF_DEF_  "TpTxIndex" 0;
BA_DEF_DEF_  "FlexKomComment" "";
BA_DEF_DEF_  "FlexKomIsMotorola" "nein";
BA_DEF_DEF_  "FlexKomSID" 0;
BA_DEF_DEF_  "FlexKomSigLaenge" 0;
BA_DEF_DEF_  "FlexKomSigName" "";
BA_DEF_DEF_  "FlexKomSigStartPos" 0;
BA_DEF_DEF_  "FlexKomSigStartValue" "";
BA_DEF_DEF_  "GenSigCycleTime" 0;
BA_DEF_DEF_  "GenSigCycleTimeActive" 0;
BA_DEF_DEF_  "GenSigSendType" "cyclicX";
BA_DEF_DEF_  "GenSigSNA" "";
BA_DEF_DEF_  "GenSigStartValue" 0;
BA_DEF_DEF_  "GenSigTimeout_CBC" 0;
BA_DEF_DEF_  "GenSigTimeout_EPS" 0;
BA_DEF_DEF_  "GenSigTimeout_ESC" 0;
BA_DEF_DEF_  "GenSigTimeout_ESL" 0;
BA_DEF_DEF_  "GenSigTimeout_RHSC2" 0;
BA_DEF_DEF_  "GenSigTimeout_ETM" 0;
BA_DEF_DEF_  "GenSigTimeout_HaLF" 0;
BA_DEF_DEF_  "GenSigTimeout_IC" 0;
BA_DEF_DEF_  "GenSigTimeout_OCM" 0;
BA_DEF_DEF_  "GenSigTimeout_ORC" 0;
BA_DEF_DEF_  "GenSigTimeout_PTS" 0;
BA_DEF_DEF_  "GenSigTimeout_RF_HUB" 0;
BA_DEF_DEF_  "GenSigTimeout_SCCM" 0;
BA_DEF_DEF_  "RID" "";
BA_ "GenMsgCycleTime" BO_ 258 10;
BA_ "GenMsgDelayTime" BO_ 258 20;
BA_ "GenMsgNrOfRepetitions" BO_ 258 2;
BA_ "GenMsgStartValue" BO_ 258 "3FFF3FFF030000FFh";
BA_ "GenMsgCycleTime" BO_ 1555 200;
BA_ "GenMsgDelayTime" BO_ 1555 200;
BA_ "GenMsgSendType" BO_ 1555 9;
BA_ "GenMsgStartDelayTime" BO_ 1555 800;
BA_ "GenMsgStartValue" BO_ 1555 "0000000000000000h";
BA_ "GenMsgCycleTime" BO_ 1562 200;
BA_ "GenMsgDelayTime" BO_ 1562 200;
BA_ "GenMsgSendType" BO_ 1562 9;
BA_ "GenMsgStartDelayTime" BO_ 1562 860;
BA_ "GenMsgStartValue" BO_ 1562 "0000000000000000h";
BA_ "GenMsgCycleTime" BO_ 1572 200;
BA_ "GenMsgDelayTime" BO_ 1572 200;
BA_ "GenMsgSendType" BO_ 1572 9;
BA_ "GenMsgStartDelayTime" BO_ 1572 800;
BA_ "GenMsgStartValue" BO_ 1572 "0000000000000000h";
BA_ "GenMsgCycleTime" BO_ 1570 200;
BA_ "GenMsgDelayTime" BO_ 1570 200;
BA_ "GenMsgSendType" BO_ 1570 9;
BA_ "GenMsgStartDelayTime" BO_ 1570 800;
BA_ "GenMsgStartValue" BO_ 1570 "0000000000000000h";
BA_ "GenMsgCycleTime" BO_ 719 500;
BA_ "GenMsgDelayTime" BO_ 719 20;
BA_ "GenMsgNrOfRepetitions" BO_ 719 2;
BA_ "GenMsgSendType" BO_ 719 5;
BA_ "GenMsgStartValue" BO_ 719 "0000000000000000h";
BA_ "GenMsgCycleTime" BO_ 792 100;
BA_ "GenMsgDelayTime" BO_ 792 20;
BA_ "GenMsgNrOfRepetitions" BO_ 792 2;
BA_ "GenMsgSendType" BO_ 792 5;
BA_ "GenMsgStartValue" BO_ 792 "000000000000FF00h";
BA_ "GenMsgCycleTime" BO_ 680 20;
BA_ "GenMsgDelayTime" BO_ 680 20;
BA_ "GenMsgNrOfRepetitions" BO_ 680 2;
BA_ "GenMsgStartValue" BO_ 680 "0FFF0F0F000000FFh";
BA_ "GenMsgCycleTime" BO_ 324 20;
BA_ "GenMsgDelayTime" BO_ 324 20;
BA_ "GenMsgNrOfRepetitions" BO_ 324 2;
BA_ "GenMsgStartValue" BO_ 324 "00FF00FFFFFFFF00h";
BA_ "GenMsgCycleTime" BO_ 368 20;
BA_ "GenMsgDelayTime" BO_ 368 20;
BA_ "GenMsgNrOfRepetitions" BO_ 368 2;
BA_ "GenMsgStartValue" BO_ 368 "1CFFFF00000000FFh";
BA_ "GenMsgCycleTime" BO_ 992 100;
BA_ "GenMsgDelayTime" BO_ 992 20;
BA_ "GenMsgNrOfRepetitions" BO_ 992 2;
BA_ "GenMsgStartValue" BO_ 992 "0300000000000000h";
BA_ "GenMsgCycleTime" BO_ 1000 500;
BA_ "GenMsgDelayTime" BO_ 1000 20;
BA_ "GenMsgNrOfRepetitions" BO_ 1000 2;
BA_ "GenMsgSendType" BO_ 1000 5;
BA_ "GenMsgStartDelayTime" BO_ 1000 50;
BA_ "GenMsgStartValue" BO_ 1000 "FFFF7FF0FF0FFF00h";
BA_ "GenMsgCycleTime" BO_ 1001 2000;
BA_ "GenMsgDelayTime" BO_ 1001 20;
BA_ "GenMsgNrOfRepetitions" BO_ 1001 2;
BA_ "GenMsgSendType" BO_ 1001 5;
BA_ "GenMsgStartDelayTime" BO_ 1001 40;
BA_ "GenMsgStartValue" BO_ 1001 "0300FF00FFFFFFFFh";
BA_ "GenMsgCycleTime" BO_ 1002 2000;
BA_ "GenMsgDelayTime" BO_ 1002 20;
BA_ "GenMsgNrOfRepetitions" BO_ 1002 2;
BA_ "GenMsgSendType" BO_ 1002 5;
BA_ "GenMsgStartDelayTime" BO_ 1002 50;
BA_ "GenMsgStartValue" BO_ 1002 "0370FF037FFF0000h";
BA_ "GenMsgCycleTime" BO_ 1003 1000;
BA_ "GenMsgDelayTime" BO_ 1003 20;
BA_ "GenMsgNrOfRepetitions" BO_ 1003 2;
BA_ "GenMsgSendType" BO_ 1003 5;
BA_ "GenMsgStartDelayTime" BO_ 1003 120;
BA_ "GenMsgStartValue" BO_ 1003 "FFFFFFFFFFFFFFFFh";
BA_ "GenMsgCycleTime" BO_ 1098 2000;
BA_ "GenMsgDelayTime" BO_ 1098 20;
BA_ "GenMsgNrOfRepetitions" BO_ 1098 2;
BA_ "GenMsgSendType" BO_ 1098 5;
BA_ "GenMsgStartDelayTime" BO_ 1098 60;
BA_ "GenMsgStartValue" BO_ 1098 "C3FFFFFFFFFFFF00h";
BA_ "GenMsgCycleTime" BO_ 897 2000;
BA_ "GenMsgDelayTime" BO_ 897 20;
BA_ "GenMsgNrOfRepetitions" BO_ 897 2;
BA_ "GenMsgSendType" BO_ 897 5;
BA_ "GenMsgStartValue" BO_ 897 "033F000000000000h";
BA_ "FlexKomComment" SG_ 258 CRC_STW_Angle_STAT "Steering wheel angle state";
BA_ "FlexKomIsMotorola" SG_ 258 CRC_STW_Angle_STAT 1;
BA_ "FlexKomSID" SG_ 258 CRC_STW_Angle_STAT 418;
BA_ "FlexKomSigLaenge" SG_ 258 CRC_STW_Angle_STAT 64;
BA_ "FlexKomSigName" SG_ 258 CRC_STW_Angle_STAT "LRW_ST";
BA_ "FlexKomSigStartPos" SG_ 258 CRC_STW_Angle_STAT 7;
BA_ "FlexKomSigStartValue" SG_ 258 CRC_STW_Angle_STAT "3FFF3FFF030000FFh";
BA_ "GenSigCycleTime" SG_ 258 CRC_STW_Angle_STAT 10;
BA_ "GenSigSNA" SG_ 258 CRC_STW_Angle_STAT "FFh";
BA_ "GenSigStartValue" SG_ 258 CRC_STW_Angle_STAT 255;
BA_ "GenSigTimeout_ETM" SG_ 258 CRC_STW_Angle_STAT 105;
BA_ "GenSigTimeout_ORC" SG_ 258 CRC_STW_Angle_STAT 35;
BA_ "FlexKomComment" SG_ 258 LRW "Steering wheel angle state";
BA_ "FlexKomIsMotorola" SG_ 258 LRW 1;
BA_ "FlexKomSID" SG_ 258 LRW 418;
BA_ "FlexKomSigLaenge" SG_ 258 LRW 64;
BA_ "FlexKomSigName" SG_ 258 LRW "LRW_ST";
BA_ "FlexKomSigStartPos" SG_ 258 LRW 7;
BA_ "FlexKomSigStartValue" SG_ 258 LRW "3FFF3FFF030000FFh";
BA_ "GenSigCycleTime" SG_ 258 LRW 10;
BA_ "GenSigSNA" SG_ 258 LRW "3FFFh";
BA_ "GenSigStartValue" SG_ 258 LRW 16383;
BA_ "GenSigTimeout_CBC" SG_ 258 LRW 105;
BA_ "GenSigTimeout_EPS" SG_ 258 LRW 105;
BA_ "GenSigTimeout_IC" SG_ 258 LRW 105;
BA_ "GenSigTimeout_ORC" SG_ 258 LRW 35;
BA_ "RID" SG_ 258 LRW "1020 1197";
BA_ "FlexKomComment" SG_ 258 LRWS_ST "Steering wheel angle state";
BA_ "FlexKomIsMotorola" SG_ 258 LRWS_ST 1;
BA_ "FlexKomSID" SG_ 258 LRWS_ST 418;
BA_ "FlexKomSigLaenge" SG_ 258 LRWS_ST 64;
BA_ "FlexKomSigName" SG_ 258 LRWS_ST "LRW_ST";
BA_ "FlexKomSigStartPos" SG_ 258 LRWS_ST 7;
BA_ "FlexKomSigStartValue" SG_ 258 LRWS_ST "3FFF3FFF030000FFh";
BA_ "GenSigCycleTime" SG_ 258 LRWS_ST 10;
BA_ "GenSigSNA" SG_ 258 LRWS_ST "3h";
BA_ "GenSigStartValue" SG_ 258 LRWS_ST 3;
BA_ "GenSigTimeout_ETM" SG_ 258 LRWS_ST 105;
BA_ "GenSigTimeout_ORC" SG_ 258 LRWS_ST 35;
BA_ "RID" SG_ 258 LRWS_ST "1206";
BA_ "FlexKomComment" SG_ 258 LRW_PLRTY "Steering wheel angle state";
BA_ "FlexKomIsMotorola" SG_ 258 LRW_PLRTY 1;
BA_ "FlexKomSID" SG_ 258 LRW_PLRTY 418;
BA_ "FlexKomSigLaenge" SG_ 258 LRW_PLRTY 64;
BA_ "FlexKomSigName" SG_ 258 LRW_PLRTY "LRW_ST";
BA_ "FlexKomSigStartPos" SG_ 258 LRW_PLRTY 7;
BA_ "FlexKomSigStartValue" SG_ 258 LRW_PLRTY "3FFF3FFF030000FFh";
BA_ "GenSigCycleTime" SG_ 258 LRW_PLRTY 10;
BA_ "GenSigSNA" SG_ 258 LRW_PLRTY "0h";
BA_ "GenSigTimeout_ETM" SG_ 258 LRW_PLRTY 105;
BA_ "GenSigTimeout_ORC" SG_ 258 LRW_PLRTY 35;
BA_ "RID" SG_ 258 LRW_PLRTY "5030";
BA_ "FlexKomComment" SG_ 258 LRW_RHP "Steering wheel angle state";
BA_ "FlexKomIsMotorola" SG_ 258 LRW_RHP 1;
BA_ "FlexKomSID" SG_ 258 LRW_RHP 418;
BA_ "FlexKomSigLaenge" SG_ 258 LRW_RHP 64;
BA_ "FlexKomSigName" SG_ 258 LRW_RHP "LRW_ST";
BA_ "FlexKomSigStartPos" SG_ 258 LRW_RHP 7;
BA_ "FlexKomSigStartValue" SG_ 258 LRW_RHP "3FFF3FFF030000FFh";
BA_ "GenSigCycleTime" SG_ 258 LRW_RHP 10;
BA_ "GenSigSNA" SG_ 258 LRW_RHP "0h";
BA_ "GenSigTimeout_EPS" SG_ 258 LRW_RHP 105;
BA_ "GenSigTimeout_ETM" SG_ 258 LRW_RHP 105;
BA_ "RID" SG_ 258 LRW_RHP "9787";
BA_ "FlexKomComment" SG_ 258 MC_STW_Angle_STAT "Steering wheel angle state";
BA_ "FlexKomIsMotorola" SG_ 258 MC_STW_Angle_STAT 1;
BA_ "FlexKomSID" SG_ 258 MC_STW_Angle_STAT 418;
BA_ "FlexKomSigLaenge" SG_ 258 MC_STW_Angle_STAT 64;
BA_ "FlexKomSigName" SG_ 258 MC_STW_Angle_STAT "LRW_ST";
BA_ "FlexKomSigStartPos" SG_ 258 MC_STW_Angle_STAT 7;
BA_ "FlexKomSigStartValue" SG_ 258 MC_STW_Angle_STAT "3FFF3FFF030000FFh";
BA_ "GenSigCycleTime" SG_ 258 MC_STW_Angle_STAT 10;
BA_ "GenSigSNA" SG_ 258 MC_STW_Angle_STAT "0h";
BA_ "GenSigTimeout_ETM" SG_ 258 MC_STW_Angle_STAT 105;
BA_ "GenSigTimeout_ORC" SG_ 258 MC_STW_Angle_STAT 35;
BA_ "FlexKomComment" SG_ 258 VLRW "Steering wheel angle state";
BA_ "FlexKomIsMotorola" SG_ 258 VLRW 1;
BA_ "FlexKomSID" SG_ 258 VLRW 418;
BA_ "FlexKomSigLaenge" SG_ 258 VLRW 64;
BA_ "FlexKomSigName" SG_ 258 VLRW "LRW_ST";
BA_ "FlexKomSigStartPos" SG_ 258 VLRW 7;
BA_ "FlexKomSigStartValue" SG_ 258 VLRW "3FFF3FFF030000FFh";
BA_ "GenSigCycleTime" SG_ 258 VLRW 10;
BA_ "GenSigSNA" SG_ 258 VLRW "3FFFh";
BA_ "GenSigStartValue" SG_ 258 VLRW 16383;
BA_ "GenSigTimeout_EPS" SG_ 258 VLRW 105;
BA_ "GenSigTimeout_ETM" SG_ 258 VLRW 105;
BA_ "GenSigTimeout_ORC" SG_ 258 VLRW 35;
BA_ "RID" SG_ 258 VLRW "9788";
BA_ "FlexKomComment" SG_ 1555 SD_RS_DASM "Response on Event - light";
BA_ "FlexKomIsMotorola" SG_ 1555 SD_RS_DASM 1;
BA_ "FlexKomSID" SG_ 1555 SD_RS_DASM 203;
BA_ "FlexKomSigLaenge" SG_ 1555 SD_RS_DASM 64;
BA_ "FlexKomSigName" SG_ 1555 SD_RS_DASM "SD_RS_DASM";
BA_ "FlexKomSigStartPos" SG_ 1555 SD_RS_DASM 7;
BA_ "FlexKomSigStartValue" SG_ 1555 SD_RS_DASM "0000000000000000h";
BA_ "GenSigCycleTime" SG_ 1555 SD_RS_DASM 200;
BA_ "GenSigSendType" SG_ 1555 SD_RS_DASM 9;
BA_ "GenSigSNA" SG_ 1555 SD_RS_DASM "0h";
BA_ "FlexKomComment" SG_ 1562 SD_RS_EPS "Response on Event - light";
BA_ "FlexKomIsMotorola" SG_ 1562 SD_RS_EPS 1;
BA_ "FlexKomSID" SG_ 1562 SD_RS_EPS 194;
BA_ "FlexKomSigLaenge" SG_ 1562 SD_RS_EPS 64;
BA_ "FlexKomSigName" SG_ 1562 SD_RS_EPS "SD_RS_EPS";
BA_ "FlexKomSigStartPos" SG_ 1562 SD_RS_EPS 7;
BA_ "FlexKomSigStartValue" SG_ 1562 SD_RS_EPS "0000000000000000h";
BA_ "GenSigCycleTime" SG_ 1562 SD_RS_EPS 200;
BA_ "GenSigSendType" SG_ 1562 SD_RS_EPS 9;
BA_ "GenSigSNA" SG_ 1562 SD_RS_EPS "0h";
BA_ "FlexKomComment" SG_ 1572 SD_RS_HaLF "Response on Event - light";
BA_ "FlexKomIsMotorola" SG_ 1572 SD_RS_HaLF 1;
BA_ "FlexKomSID" SG_ 1572 SD_RS_HaLF 1635;
BA_ "FlexKomSigLaenge" SG_ 1572 SD_RS_HaLF 64;
BA_ "FlexKomSigName" SG_ 1572 SD_RS_HaLF "SD_RS_HaLF";
BA_ "FlexKomSigStartPos" SG_ 1572 SD_RS_HaLF 7;
BA_ "FlexKomSigStartValue" SG_ 1572 SD_RS_HaLF "0000000000000000h";
BA_ "GenSigCycleTime" SG_ 1572 SD_RS_HaLF 200;
BA_ "GenSigSendType" SG_ 1572 SD_RS_HaLF 9;
BA_ "GenSigSNA" SG_ 1572 SD_RS_HaLF "0h";
BA_ "FlexKomComment" SG_ 1570 SD_RS_PTS "Response on Event - light";
BA_ "FlexKomIsMotorola" SG_ 1570 SD_RS_PTS 1;
BA_ "FlexKomSID" SG_ 1570 SD_RS_PTS 215;
BA_ "FlexKomSigLaenge" SG_ 1570 SD_RS_PTS 64;
BA_ "FlexKomSigName" SG_ 1570 SD_RS_PTS "SD_RS_PTS";
BA_ "FlexKomSigStartPos" SG_ 1570 SD_RS_PTS 7;
BA_ "FlexKomSigStartValue" SG_ 1570 SD_RS_PTS "0000000000000000h";
BA_ "GenSigCycleTime" SG_ 1570 SD_RS_PTS 200;
BA_ "GenSigSendType" SG_ 1570 SD_RS_PTS 9;
BA_ "GenSigSNA" SG_ 1570 SD_RS_PTS "0h";
BA_ "FlexKomComment" SG_ 719 HMICode "HMI codes to be displayed";
BA_ "FlexKomIsMotorola" SG_ 719 HMICode 1;
BA_ "FlexKomSID" SG_ 719 HMICode 1919;
BA_ "FlexKomSigLaenge" SG_ 719 HMICode 8;
BA_ "FlexKomSigName" SG_ 719 HMICode "HMICode";
BA_ "FlexKomSigStartPos" SG_ 719 HMICode 7;
BA_ "FlexKomSigStartValue" SG_ 719 HMICode "00h";
BA_ "GenSigCycleTime" SG_ 719 HMICode 500;
BA_ "GenSigSendType" SG_ 719 HMICode 5;
BA_ "GenSigSNA" SG_ 719 HMICode "0h";
BA_ "GenSigTimeout_IC" SG_ 719 HMICode 5250;
BA_ "FlexKomComment" SG_ 719 PPPAControlSts "Indicates the active state of PPPA; active = [1]";
BA_ "FlexKomIsMotorola" SG_ 719 PPPAControlSts 1;
BA_ "FlexKomSID" SG_ 719 PPPAControlSts 1918;
BA_ "FlexKomSigLaenge" SG_ 719 PPPAControlSts 1;
BA_ "FlexKomSigName" SG_ 719 PPPAControlSts "PPPAControlSts";
BA_ "FlexKomSigStartPos" SG_ 719 PPPAControlSts 9;
BA_ "FlexKomSigStartValue" SG_ 719 PPPAControlSts "00h";
BA_ "GenSigCycleTime" SG_ 719 PPPAControlSts 500;
BA_ "GenSigSendType" SG_ 719 PPPAControlSts 5;
BA_ "GenSigSNA" SG_ 719 PPPAControlSts "0h";
BA_ "GenSigTimeout_IC" SG_ 719 PPPAControlSts 5250;
BA_ "FlexKomComment" SG_ 719 PPPASystemFault "Indicates the fail status of PPPA; true = [1]";
BA_ "FlexKomIsMotorola" SG_ 719 PPPASystemFault 1;
BA_ "FlexKomSID" SG_ 719 PPPASystemFault 1917;
BA_ "FlexKomSigLaenge" SG_ 719 PPPASystemFault 1;
BA_ "FlexKomSigName" SG_ 719 PPPASystemFault "PPPASystemFault";
BA_ "FlexKomSigStartPos" SG_ 719 PPPASystemFault 8;
BA_ "FlexKomSigStartValue" SG_ 719 PPPASystemFault "00h";
BA_ "GenSigCycleTime" SG_ 719 PPPASystemFault 500;
BA_ "GenSigSendType" SG_ 719 PPPASystemFault 5;
BA_ "GenSigSNA" SG_ 719 PPPASystemFault "0h";
BA_ "GenSigTimeout_IC" SG_ 719 PPPASystemFault 5250;
BA_ "FlexKomComment" SG_ 719 PPPA_STAT "Parallel & perpendicular park assist switch status";
BA_ "FlexKomIsMotorola" SG_ 719 PPPA_STAT 1;
BA_ "FlexKomSID" SG_ 719 PPPA_STAT 1922;
BA_ "FlexKomSigLaenge" SG_ 719 PPPA_STAT 2;
BA_ "FlexKomSigName" SG_ 719 PPPA_STAT "PPPA_STAT";
BA_ "FlexKomSigStartPos" SG_ 719 PPPA_STAT 15;
BA_ "FlexKomSigStartValue" SG_ 719 PPPA_STAT "00h";
BA_ "GenSigCycleTime" SG_ 719 PPPA_STAT 500;
BA_ "GenSigSendType" SG_ 719 PPPA_STAT 5;
BA_ "GenSigSNA" SG_ 719 PPPA_STAT "3h";
BA_ "GenSigTimeout_CBC" SG_ 719 PPPA_STAT 5250;
BA_ "RID" SG_ 719 PPPA_STAT "1902";
BA_ "FlexKomComment" SG_ 719 PTS_DBD "Park assist system disabled; System_Disabled = [1]";
BA_ "FlexKomIsMotorola" SG_ 719 PTS_DBD 1;
BA_ "FlexKomSID" SG_ 719 PTS_DBD 1949;
BA_ "FlexKomSigLaenge" SG_ 719 PTS_DBD 1;
BA_ "FlexKomSigName" SG_ 719 PTS_DBD "PTS_DBD";
BA_ "FlexKomSigStartPos" SG_ 719 PTS_DBD 16;
BA_ "FlexKomSigStartValue" SG_ 719 PTS_DBD "00h";
BA_ "GenSigCycleTime" SG_ 719 PTS_DBD 500;
BA_ "GenSigSendType" SG_ 719 PTS_DBD 5;
BA_ "GenSigSNA" SG_ 719 PTS_DBD "0h";
BA_ "GenSigTimeout_IC" SG_ 719 PTS_DBD 5250;
BA_ "FlexKomComment" SG_ 792 HiBmLvr_Stat "Steering wheel actuation request";
BA_ "FlexKomIsMotorola" SG_ 792 HiBmLvr_Stat 1;
BA_ "FlexKomSID" SG_ 792 HiBmLvr_Stat 420;
BA_ "FlexKomSigLaenge" SG_ 792 HiBmLvr_Stat 64;
BA_ "FlexKomSigName" SG_ 792 HiBmLvr_Stat "StW_Actn_Rq";
BA_ "FlexKomSigStartPos" SG_ 792 HiBmLvr_Stat 7;
BA_ "FlexKomSigStartValue" SG_ 792 HiBmLvr_Stat "000000000000FF00h";
BA_ "GenSigCycleTime" SG_ 792 HiBmLvr_Stat 100;
BA_ "GenSigSendType" SG_ 792 HiBmLvr_Stat 5;
BA_ "GenSigSNA" SG_ 792 HiBmLvr_Stat "0h";
BA_ "RID" SG_ 792 HiBmLvr_Stat "1219 1294 1709";
BA_ "FlexKomComment" SG_ 792 TurnIndLvr_Stat "Steering wheel actuation request";
BA_ "FlexKomIsMotorola" SG_ 792 TurnIndLvr_Stat 1;
BA_ "FlexKomSID" SG_ 792 TurnIndLvr_Stat 420;
BA_ "FlexKomSigLaenge" SG_ 792 TurnIndLvr_Stat 64;
BA_ "FlexKomSigName" SG_ 792 TurnIndLvr_Stat "StW_Actn_Rq";
BA_ "FlexKomSigStartPos" SG_ 792 TurnIndLvr_Stat 7;
BA_ "FlexKomSigStartValue" SG_ 792 TurnIndLvr_Stat "000000000000FF00h";
BA_ "GenSigCycleTime" SG_ 792 TurnIndLvr_Stat 100;
BA_ "GenSigSendType" SG_ 792 TurnIndLvr_Stat 5;
BA_ "GenSigSNA" SG_ 792 TurnIndLvr_Stat "0h";
BA_ "GenSigTimeout_PTS" SG_ 792 TurnIndLvr_Stat 1050;
BA_ "RID" SG_ 792 TurnIndLvr_Stat "1220";
BA_ "FlexKomComment" SG_ 792 WprSw6Posn "Steering wheel actuation request";
BA_ "FlexKomIsMotorola" SG_ 792 WprSw6Posn 1;
BA_ "FlexKomSID" SG_ 792 WprSw6Posn 420;
BA_ "FlexKomSigLaenge" SG_ 792 WprSw6Posn 64;
BA_ "FlexKomSigName" SG_ 792 WprSw6Posn "StW_Actn_Rq";
BA_ "FlexKomSigStartPos" SG_ 792 WprSw6Posn 7;
BA_ "FlexKomSigStartValue" SG_ 792 WprSw6Posn "000000000000FF00h";
BA_ "GenSigCycleTime" SG_ 792 WprSw6Posn 100;
BA_ "GenSigSendType" SG_ 792 WprSw6Posn 5;
BA_ "GenSigSNA" SG_ 792 WprSw6Posn "Fh";
BA_ "GenSigTimeout_CBC" SG_ 792 WprSw6Posn 1050;
BA_ "RID" SG_ 792 WprSw6Posn "1214 1297";
BA_ "FlexKomComment" SG_ 792 WprWashSw_Psd "Steering wheel actuation request";
BA_ "FlexKomIsMotorola" SG_ 792 WprWashSw_Psd 1;
BA_ "FlexKomSID" SG_ 792 WprWashSw_Psd 420;
BA_ "FlexKomSigLaenge" SG_ 792 WprWashSw_Psd 64;
BA_ "FlexKomSigName" SG_ 792 WprWashSw_Psd "StW_Actn_Rq";
BA_ "FlexKomSigStartPos" SG_ 792 WprWashSw_Psd 7;
BA_ "FlexKomSigStartValue" SG_ 792 WprWashSw_Psd "000000000000FF00h";
BA_ "GenSigCycleTime" SG_ 792 WprWashSw_Psd 100;
BA_ "GenSigSendType" SG_ 792 WprWashSw_Psd 5;
BA_ "GenSigSNA" SG_ 792 WprWashSw_Psd "0h";
BA_ "RID" SG_ 792 WprWashSw_Psd "1234";
BA_ "FlexKomComment" SG_ 792 WprWash_R_Sw_Posn_V3 "Steering wheel actuation request";
BA_ "FlexKomIsMotorola" SG_ 792 WprWash_R_Sw_Posn_V3 1;
BA_ "FlexKomSID" SG_ 792 WprWash_R_Sw_Posn_V3 420;
BA_ "FlexKomSigLaenge" SG_ 792 WprWash_R_Sw_Posn_V3 64;
BA_ "FlexKomSigName" SG_ 792 WprWash_R_Sw_Posn_V3 "StW_Actn_Rq";
BA_ "FlexKomSigStartPos" SG_ 792 WprWash_R_Sw_Posn_V3 7;
BA_ "FlexKomSigStartValue" SG_ 792 WprWash_R_Sw_Posn_V3 "000000000000FF00h";
BA_ "GenSigCycleTime" SG_ 792 WprWash_R_Sw_Posn_V3 100;
BA_ "GenSigSendType" SG_ 792 WprWash_R_Sw_Posn_V3 5;
BA_ "GenSigSNA" SG_ 792 WprWash_R_Sw_Posn_V3 "0h";
BA_ "RID" SG_ 792 WprWash_R_Sw_Posn_V3 "1224";
BA_ "FlexKomComment" SG_ 680 CRC_TCM_A7 "Transmission message A7 packet";
BA_ "FlexKomIsMotorola" SG_ 680 CRC_TCM_A7 1;
BA_ "FlexKomSID" SG_ 680 CRC_TCM_A7 1613;
BA_ "FlexKomSigLaenge" SG_ 680 CRC_TCM_A7 64;
BA_ "FlexKomSigName" SG_ 680 CRC_TCM_A7 "TCM_A7_PKT";
BA_ "FlexKomSigStartPos" SG_ 680 CRC_TCM_A7 7;
BA_ "FlexKomSigStartValue" SG_ 680 CRC_TCM_A7 "0FFF0F0F000000FFh";
BA_ "GenSigCycleTime" SG_ 680 CRC_TCM_A7 20;
BA_ "GenSigSNA" SG_ 680 CRC_TCM_A7 "FFh";
BA_ "GenSigStartValue" SG_ 680 CRC_TCM_A7 255;
BA_ "FlexKomComment" SG_ 680 CurrentGear "Transmission message A7 packet";
BA_ "FlexKomIsMotorola" SG_ 680 CurrentGear 1;
BA_ "FlexKomSID" SG_ 680 CurrentGear 1613;
BA_ "FlexKomSigLaenge" SG_ 680 CurrentGear 64;
BA_ "FlexKomSigName" SG_ 680 CurrentGear "TCM_A7_PKT";
BA_ "FlexKomSigStartPos" SG_ 680 CurrentGear 7;
BA_ "FlexKomSigStartValue" SG_ 680 CurrentGear "0FFF0F0F000000FFh";
BA_ "GenSigCycleTime" SG_ 680 CurrentGear 20;
BA_ "GenSigSNA" SG_ 680 CurrentGear "Fh";
BA_ "GenSigStartValue" SG_ 680 CurrentGear 15;
BA_ "FlexKomComment" SG_ 680 HCPShutDwnCmd "Transmission message A7 packet";
BA_ "FlexKomIsMotorola" SG_ 680 HCPShutDwnCmd 1;
BA_ "FlexKomSID" SG_ 680 HCPShutDwnCmd 1613;
BA_ "FlexKomSigLaenge" SG_ 680 HCPShutDwnCmd 64;
BA_ "FlexKomSigName" SG_ 680 HCPShutDwnCmd "TCM_A7_PKT";
BA_ "FlexKomSigStartPos" SG_ 680 HCPShutDwnCmd 7;
BA_ "FlexKomSigStartValue" SG_ 680 HCPShutDwnCmd "0FFF0F0F000000FFh";
BA_ "GenSigCycleTime" SG_ 680 HCPShutDwnCmd 20;
BA_ "GenSigSNA" SG_ 680 HCPShutDwnCmd "7h";
BA_ "GenSigTimeout_CBC" SG_ 680 HCPShutDwnCmd 210;
BA_ "FlexKomComment" SG_ 680 HCP_IMMO_STAT_CANC "Transmission message A7 packet";
BA_ "FlexKomIsMotorola" SG_ 680 HCP_IMMO_STAT_CANC 1;
BA_ "FlexKomSID" SG_ 680 HCP_IMMO_STAT_CANC 1613;
BA_ "FlexKomSigLaenge" SG_ 680 HCP_IMMO_STAT_CANC 64;
BA_ "FlexKomSigName" SG_ 680 HCP_IMMO_STAT_CANC "TCM_A7_PKT";
BA_ "FlexKomSigStartPos" SG_ 680 HCP_IMMO_STAT_CANC 7;
BA_ "FlexKomSigStartValue" SG_ 680 HCP_IMMO_STAT_CANC "0FFF0F0F000000FFh";
BA_ "GenSigCycleTime" SG_ 680 HCP_IMMO_STAT_CANC 20;
BA_ "GenSigSNA" SG_ 680 HCP_IMMO_STAT_CANC "3h";
BA_ "GenSigTimeout_CBC" SG_ 680 HCP_IMMO_STAT_CANC 210;
BA_ "FlexKomComment" SG_ 680 MC_TCM_A7 "Transmission message A7 packet";
BA_ "FlexKomIsMotorola" SG_ 680 MC_TCM_A7 1;
BA_ "FlexKomSID" SG_ 680 MC_TCM_A7 1613;
BA_ "FlexKomSigLaenge" SG_ 680 MC_TCM_A7 64;
BA_ "FlexKomSigName" SG_ 680 MC_TCM_A7 "TCM_A7_PKT";
BA_ "FlexKomSigStartPos" SG_ 680 MC_TCM_A7 7;
BA_ "FlexKomSigStartValue" SG_ 680 MC_TCM_A7 "0FFF0F0F000000FFh";
BA_ "GenSigCycleTime" SG_ 680 MC_TCM_A7 20;
BA_ "GenSigSNA" SG_ 680 MC_TCM_A7 "0h";
BA_ "FlexKomComment" SG_ 680 TCM_Vehicle_Hold_Rq "Transmission message A7 packet";
BA_ "FlexKomIsMotorola" SG_ 680 TCM_Vehicle_Hold_Rq 1;
BA_ "FlexKomSID" SG_ 680 TCM_Vehicle_Hold_Rq 1613;
BA_ "FlexKomSigLaenge" SG_ 680 TCM_Vehicle_Hold_Rq 64;
BA_ "FlexKomSigName" SG_ 680 TCM_Vehicle_Hold_Rq "TCM_A7_PKT";
BA_ "FlexKomSigStartPos" SG_ 680 TCM_Vehicle_Hold_Rq 7;
BA_ "FlexKomSigStartValue" SG_ 680 TCM_Vehicle_Hold_Rq "0FFF0F0F000000FFh";
BA_ "GenSigCycleTime" SG_ 680 TCM_Vehicle_Hold_Rq 20;
BA_ "GenSigSNA" SG_ 680 TCM_Vehicle_Hold_Rq "3h";
BA_ "FlexKomComment" SG_ 680 TX_WARN2 "Transmission message A7 packet";
BA_ "FlexKomIsMotorola" SG_ 680 TX_WARN2 1;
BA_ "FlexKomSID" SG_ 680 TX_WARN2 1613;
BA_ "FlexKomSigLaenge" SG_ 680 TX_WARN2 64;
BA_ "FlexKomSigName" SG_ 680 TX_WARN2 "TCM_A7_PKT";
BA_ "FlexKomSigStartPos" SG_ 680 TX_WARN2 7;
BA_ "FlexKomSigStartValue" SG_ 680 TX_WARN2 "0FFF0F0F000000FFh";
BA_ "GenSigCycleTime" SG_ 680 TX_WARN2 20;
BA_ "GenSigSNA" SG_ 680 TX_WARN2 "FFh";
BA_ "GenSigTimeout_CBC" SG_ 680 TX_WARN2 210;
BA_ "GenSigTimeout_IC" SG_ 680 TX_WARN2 210;
BA_ "RID" SG_ 680 TX_WARN2 "2157";
BA_ "FlexKomComment" SG_ 680 TargetGear "Transmission message A7 packet";
BA_ "FlexKomIsMotorola" SG_ 680 TargetGear 1;
BA_ "FlexKomSID" SG_ 680 TargetGear 1613;
BA_ "FlexKomSigLaenge" SG_ 680 TargetGear 64;
BA_ "FlexKomSigName" SG_ 680 TargetGear "TCM_A7_PKT";
BA_ "FlexKomSigStartPos" SG_ 680 TargetGear 7;
BA_ "FlexKomSigStartValue" SG_ 680 TargetGear "0FFF0F0F000000FFh";
BA_ "GenSigCycleTime" SG_ 680 TargetGear 20;
BA_ "GenSigSNA" SG_ 680 TargetGear "Fh";
BA_ "GenSigStartValue" SG_ 680 TargetGear 15;
BA_ "FlexKomComment" SG_ 324 EngSt_Enbl_Rq_TCM "Enable engine start request";
BA_ "FlexKomIsMotorola" SG_ 324 EngSt_Enbl_Rq_TCM 1;
BA_ "FlexKomSID" SG_ 324 EngSt_Enbl_Rq_TCM 1125;
BA_ "FlexKomSigLaenge" SG_ 324 EngSt_Enbl_Rq_TCM 1;
BA_ "FlexKomSigName" SG_ 324 EngSt_Enbl_Rq_TCM "EngSt_Enbl_Rq_TCM";
BA_ "FlexKomSigStartPos" SG_ 324 EngSt_Enbl_Rq_TCM 5;
BA_ "FlexKomSigStartValue" SG_ 324 EngSt_Enbl_Rq_TCM "00h";
BA_ "GenSigCycleTime" SG_ 324 EngSt_Enbl_Rq_TCM 20;
BA_ "GenSigSNA" SG_ 324 EngSt_Enbl_Rq_TCM "0h";
BA_ "FlexKomComment" SG_ 324 Gr "Current Gear/Target Gear";
BA_ "FlexKomIsMotorola" SG_ 324 Gr 1;
BA_ "FlexKomSID" SG_ 324 Gr 1128;
BA_ "FlexKomSigLaenge" SG_ 324 Gr 16;
BA_ "FlexKomSigName" SG_ 324 Gr "Gear_Pkt";
BA_ "FlexKomSigStartPos" SG_ 324 Gr 15;
BA_ "FlexKomSigStartValue" SG_ 324 Gr "FF00h";
BA_ "GenSigCycleTime" SG_ 324 Gr 20;
BA_ "GenSigSNA" SG_ 324 Gr "Fh";
BA_ "GenSigStartValue" SG_ 324 Gr 15;
BA_ "GenSigTimeout_CBC" SG_ 324 Gr 210;
BA_ "GenSigTimeout_RHSC2" SG_ 324 Gr 210;
BA_ "GenSigTimeout_IC" SG_ 324 Gr 210;
BA_ "GenSigTimeout_ORC" SG_ 324 Gr 70;
BA_ "GenSigTimeout_RF_HUB" SG_ 324 Gr 210;
BA_ "RID" SG_ 324 Gr "1069";
BA_ "FlexKomComment" SG_ 324 Gr_Target "Current Gear/Target Gear";
BA_ "FlexKomIsMotorola" SG_ 324 Gr_Target 1;
BA_ "FlexKomSID" SG_ 324 Gr_Target 1128;
BA_ "FlexKomSigLaenge" SG_ 324 Gr_Target 16;
BA_ "FlexKomSigName" SG_ 324 Gr_Target "Gear_Pkt";
BA_ "FlexKomSigStartPos" SG_ 324 Gr_Target 15;
BA_ "FlexKomSigStartValue" SG_ 324 Gr_Target "FF00h";
BA_ "GenSigCycleTime" SG_ 324 Gr_Target 20;
BA_ "GenSigSNA" SG_ 324 Gr_Target "Fh";
BA_ "GenSigStartValue" SG_ 324 Gr_Target 15;
BA_ "GenSigTimeout_CBC" SG_ 324 Gr_Target 210;
BA_ "RID" SG_ 324 Gr_Target "1814";
BA_ "FlexKomComment" SG_ 324 OUTPUT_SPEED "Output shaft speed packet";
BA_ "FlexKomIsMotorola" SG_ 324 OUTPUT_SPEED 1;
BA_ "FlexKomSID" SG_ 324 OUTPUT_SPEED 1605;
BA_ "FlexKomSigLaenge" SG_ 324 OUTPUT_SPEED 40;
BA_ "FlexKomSigName" SG_ 324 OUTPUT_SPEED "OutputSpdPkt";
BA_ "FlexKomSigStartPos" SG_ 324 OUTPUT_SPEED 31;
BA_ "FlexKomSigStartValue" SG_ 324 OUTPUT_SPEED "FFFF000000h";
BA_ "GenSigCycleTime" SG_ 324 OUTPUT_SPEED 20;
BA_ "GenSigSNA" SG_ 324 OUTPUT_SPEED "FFFFh";
BA_ "GenSigStartValue" SG_ 324 OUTPUT_SPEED 65535;
BA_ "FlexKomComment" SG_ 368 APCM_Rq "TRNS_STAT message packet";
BA_ "FlexKomIsMotorola" SG_ 368 APCM_Rq 1;
BA_ "FlexKomSID" SG_ 368 APCM_Rq 1366;
BA_ "FlexKomSigLaenge" SG_ 368 APCM_Rq 64;
BA_ "FlexKomSigName" SG_ 368 APCM_Rq "TRNS_STAT_PKT";
BA_ "FlexKomSigStartPos" SG_ 368 APCM_Rq 7;
BA_ "FlexKomSigStartValue" SG_ 368 APCM_Rq "1CFFFF00000000FFh";
BA_ "GenSigCycleTime" SG_ 368 APCM_Rq 20;
BA_ "GenSigSNA" SG_ 368 APCM_Rq "3h";
BA_ "GenSigTimeout_RHSC2" SG_ 368 APCM_Rq 210;
BA_ "GenSigTimeout_IC" SG_ 368 APCM_Rq 210;
BA_ "RID" SG_ 368 APCM_Rq "9750";
BA_ "FlexKomComment" SG_ 368 CRC_TRNS_STAT "TRNS_STAT message packet";
BA_ "FlexKomIsMotorola" SG_ 368 CRC_TRNS_STAT 1;
BA_ "FlexKomSID" SG_ 368 CRC_TRNS_STAT 1366;
BA_ "FlexKomSigLaenge" SG_ 368 CRC_TRNS_STAT 64;
BA_ "FlexKomSigName" SG_ 368 CRC_TRNS_STAT "TRNS_STAT_PKT";
BA_ "FlexKomSigStartPos" SG_ 368 CRC_TRNS_STAT 7;
BA_ "FlexKomSigStartValue" SG_ 368 CRC_TRNS_STAT "1CFFFF00000000FFh";
BA_ "GenSigCycleTime" SG_ 368 CRC_TRNS_STAT 20;
BA_ "GenSigSNA" SG_ 368 CRC_TRNS_STAT "FFh";
BA_ "GenSigStartValue" SG_ 368 CRC_TRNS_STAT 255;
BA_ "GenSigTimeout_RHSC2" SG_ 368 CRC_TRNS_STAT 410;
BA_ "GenSigTimeout_ORC" SG_ 368 CRC_TRNS_STAT 70;
BA_ "FlexKomComment" SG_ 368 EngStEnblRqTCM "TRNS_STAT message packet";
BA_ "FlexKomIsMotorola" SG_ 368 EngStEnblRqTCM 1;
BA_ "FlexKomSID" SG_ 368 EngStEnblRqTCM 1366;
BA_ "FlexKomSigLaenge" SG_ 368 EngStEnblRqTCM 64;
BA_ "FlexKomSigName" SG_ 368 EngStEnblRqTCM "TRNS_STAT_PKT";
BA_ "FlexKomSigStartPos" SG_ 368 EngStEnblRqTCM 7;
BA_ "FlexKomSigStartValue" SG_ 368 EngStEnblRqTCM "1CFFFF00000000FFh";
BA_ "GenSigCycleTime" SG_ 368 EngStEnblRqTCM 20;
BA_ "GenSigSNA" SG_ 368 EngStEnblRqTCM "0h";
BA_ "FlexKomComment" SG_ 368 MC_TRNS_STAT "TRNS_STAT message packet";
BA_ "FlexKomIsMotorola" SG_ 368 MC_TRNS_STAT 1;
BA_ "FlexKomSID" SG_ 368 MC_TRNS_STAT 1366;
BA_ "FlexKomSigLaenge" SG_ 368 MC_TRNS_STAT 64;
BA_ "FlexKomSigName" SG_ 368 MC_TRNS_STAT "TRNS_STAT_PKT";
BA_ "FlexKomSigStartPos" SG_ 368 MC_TRNS_STAT 7;
BA_ "FlexKomSigStartValue" SG_ 368 MC_TRNS_STAT "1CFFFF00000000FFh";
BA_ "GenSigCycleTime" SG_ 368 MC_TRNS_STAT 20;
BA_ "GenSigSNA" SG_ 368 MC_TRNS_STAT "0h";
BA_ "GenSigTimeout_RHSC2" SG_ 368 MC_TRNS_STAT 410;
BA_ "GenSigTimeout_ORC" SG_ 368 MC_TRNS_STAT 70;
BA_ "RID" SG_ 368 MC_TRNS_STAT "9752";
BA_ "FlexKomComment" SG_ 368 PRNDL_Blink "TRNS_STAT message packet";
BA_ "FlexKomIsMotorola" SG_ 368 PRNDL_Blink 1;
BA_ "FlexKomSID" SG_ 368 PRNDL_Blink 1366;
BA_ "FlexKomSigLaenge" SG_ 368 PRNDL_Blink 64;
BA_ "FlexKomSigName" SG_ 368 PRNDL_Blink "TRNS_STAT_PKT";
BA_ "FlexKomSigStartPos" SG_ 368 PRNDL_Blink 7;
BA_ "FlexKomSigStartValue" SG_ 368 PRNDL_Blink "1CFFFF00000000FFh";
BA_ "GenSigCycleTime" SG_ 368 PRNDL_Blink 20;
BA_ "GenSigSNA" SG_ 368 PRNDL_Blink "0h";
BA_ "GenSigTimeout_RHSC2" SG_ 368 PRNDL_Blink 210;
BA_ "GenSigTimeout_IC" SG_ 368 PRNDL_Blink 210;
BA_ "RID" SG_ 368 PRNDL_Blink "9752";
BA_ "FlexKomComment" SG_ 368 PRNDL_DISP "TRNS_STAT message packet";
BA_ "FlexKomIsMotorola" SG_ 368 PRNDL_DISP 1;
BA_ "FlexKomSID" SG_ 368 PRNDL_DISP 1366;
BA_ "FlexKomSigLaenge" SG_ 368 PRNDL_DISP 64;
BA_ "FlexKomSigName" SG_ 368 PRNDL_DISP "TRNS_STAT_PKT";
BA_ "FlexKomSigStartPos" SG_ 368 PRNDL_DISP 7;
BA_ "FlexKomSigStartValue" SG_ 368 PRNDL_DISP "1CFFFF00000000FFh";
BA_ "GenSigCycleTime" SG_ 368 PRNDL_DISP 20;
BA_ "GenSigSNA" SG_ 368 PRNDL_DISP "FFh";
BA_ "GenSigStartValue" SG_ 368 PRNDL_DISP 255;
BA_ "GenSigTimeout_CBC" SG_ 368 PRNDL_DISP 210;
BA_ "GenSigTimeout_RHSC2" SG_ 368 PRNDL_DISP 410;
BA_ "GenSigTimeout_IC" SG_ 368 PRNDL_DISP 210;
BA_ "RID" SG_ 368 PRNDL_DISP "1110";
BA_ "FlexKomComment" SG_ 368 PRND_STAT "TRNS_STAT message packet";
BA_ "FlexKomIsMotorola" SG_ 368 PRND_STAT 1;
BA_ "FlexKomSID" SG_ 368 PRND_STAT 1366;
BA_ "FlexKomSigLaenge" SG_ 368 PRND_STAT 64;
BA_ "FlexKomSigName" SG_ 368 PRND_STAT "TRNS_STAT_PKT";
BA_ "FlexKomSigStartPos" SG_ 368 PRND_STAT 7;
BA_ "FlexKomSigStartValue" SG_ 368 PRND_STAT "1CFFFF00000000FFh";
BA_ "GenSigCycleTime" SG_ 368 PRND_STAT 20;
BA_ "GenSigSNA" SG_ 368 PRND_STAT "7h";
BA_ "GenSigStartValue" SG_ 368 PRND_STAT 7;
BA_ "GenSigTimeout_CBC" SG_ 368 PRND_STAT 510;
BA_ "GenSigTimeout_RHSC2" SG_ 368 PRND_STAT 410;
BA_ "GenSigTimeout_IC" SG_ 368 PRND_STAT 210;
BA_ "GenSigTimeout_ORC" SG_ 368 PRND_STAT 70;
BA_ "GenSigTimeout_PTS" SG_ 368 PRND_STAT 210;
BA_ "GenSigTimeout_RF_HUB" SG_ 368 PRND_STAT 210;
BA_ "RID" SG_ 368 PRND_STAT "1003 1270 1290 1708 6372 6373 6374";
BA_ "FlexKomComment" SG_ 368 R_SHFT_LOCK "TRNS_STAT message packet";
BA_ "FlexKomIsMotorola" SG_ 368 R_SHFT_LOCK 1;
BA_ "FlexKomSID" SG_ 368 R_SHFT_LOCK 1366;
BA_ "FlexKomSigLaenge" SG_ 368 R_SHFT_LOCK 64;
BA_ "FlexKomSigName" SG_ 368 R_SHFT_LOCK "TRNS_STAT_PKT";
BA_ "FlexKomSigStartPos" SG_ 368 R_SHFT_LOCK 7;
BA_ "FlexKomSigStartValue" SG_ 368 R_SHFT_LOCK "1CFFFF00000000FFh";
BA_ "GenSigCycleTime" SG_ 368 R_SHFT_LOCK 20;
BA_ "GenSigSNA" SG_ 368 R_SHFT_LOCK "0h";
BA_ "RID" SG_ 368 R_SHFT_LOCK "9753";
BA_ "FlexKomComment" SG_ 368 SHFT_LOCK "TRNS_STAT message packet";
BA_ "FlexKomIsMotorola" SG_ 368 SHFT_LOCK 1;
BA_ "FlexKomSID" SG_ 368 SHFT_LOCK 1366;
BA_ "FlexKomSigLaenge" SG_ 368 SHFT_LOCK 64;
BA_ "FlexKomSigName" SG_ 368 SHFT_LOCK "TRNS_STAT_PKT";
BA_ "FlexKomSigStartPos" SG_ 368 SHFT_LOCK 7;
BA_ "FlexKomSigStartValue" SG_ 368 SHFT_LOCK "1CFFFF00000000FFh";
BA_ "GenSigCycleTime" SG_ 368 SHFT_LOCK 20;
BA_ "GenSigSNA" SG_ 368 SHFT_LOCK "0h";
BA_ "GenSigTimeout_RHSC2" SG_ 368 SHFT_LOCK 210;
BA_ "RID" SG_ 368 SHFT_LOCK "9754";
BA_ "FlexKomComment" SG_ 368 SHFT_PROG "TRNS_STAT message packet";
BA_ "FlexKomIsMotorola" SG_ 368 SHFT_PROG 1;
BA_ "FlexKomSID" SG_ 368 SHFT_PROG 1366;
BA_ "FlexKomSigLaenge" SG_ 368 SHFT_PROG 64;
BA_ "FlexKomSigName" SG_ 368 SHFT_PROG "TRNS_STAT_PKT";
BA_ "FlexKomSigStartPos" SG_ 368 SHFT_PROG 7;
BA_ "FlexKomSigStartValue" SG_ 368 SHFT_PROG "1CFFFF00000000FFh";
BA_ "GenSigCycleTime" SG_ 368 SHFT_PROG 20;
BA_ "GenSigSNA" SG_ 368 SHFT_PROG "FFh";
BA_ "GenSigStartValue" SG_ 368 SHFT_PROG 255;
BA_ "GenSigTimeout_CBC" SG_ 368 SHFT_PROG 210;
BA_ "GenSigTimeout_RHSC2" SG_ 368 SHFT_PROG 410;
BA_ "GenSigTimeout_IC" SG_ 368 SHFT_PROG 210;
BA_ "RID" SG_ 368 SHFT_PROG "1118";
BA_ "FlexKomComment" SG_ 992 VIN_DATA "Vin Information";
BA_ "FlexKomIsMotorola" SG_ 992 VIN_DATA 1;
BA_ "FlexKomSID" SG_ 992 VIN_DATA 430;
BA_ "FlexKomSigLaenge" SG_ 992 VIN_DATA 64;
BA_ "FlexKomSigName" SG_ 992 VIN_DATA "VIN_INFO";
BA_ "FlexKomSigStartPos" SG_ 992 VIN_DATA 7;
BA_ "FlexKomSigStartValue" SG_ 992 VIN_DATA "0300000000000000h";
BA_ "GenSigCycleTime" SG_ 992 VIN_DATA 100;
BA_ "GenSigSNA" SG_ 992 VIN_DATA "0h";
BA_ "GenSigTimeout_EPS" SG_ 992 VIN_DATA 1050;
BA_ "GenSigTimeout_RHSC2" SG_ 992 VIN_DATA 1050;
BA_ "GenSigTimeout_IC" SG_ 992 VIN_DATA 1050;
BA_ "GenSigTimeout_OCM" SG_ 992 VIN_DATA 5050;
BA_ "GenSigTimeout_ORC" SG_ 992 VIN_DATA 350;
BA_ "GenSigTimeout_SCCM" SG_ 992 VIN_DATA 1050;
BA_ "RID" SG_ 992 VIN_DATA "1239";
BA_ "FlexKomComment" SG_ 992 VIN_MSG "Vin Information";
BA_ "FlexKomIsMotorola" SG_ 992 VIN_MSG 1;
BA_ "FlexKomSID" SG_ 992 VIN_MSG 430;
BA_ "FlexKomSigLaenge" SG_ 992 VIN_MSG 64;
BA_ "FlexKomSigName" SG_ 992 VIN_MSG "VIN_INFO";
BA_ "FlexKomSigStartPos" SG_ 992 VIN_MSG 7;
BA_ "FlexKomSigStartValue" SG_ 992 VIN_MSG "0300000000000000h";
BA_ "GenSigCycleTime" SG_ 992 VIN_MSG 100;
BA_ "GenSigSNA" SG_ 992 VIN_MSG "3h";
BA_ "GenSigStartValue" SG_ 992 VIN_MSG 3;
BA_ "GenSigTimeout_EPS" SG_ 992 VIN_MSG 1050;
BA_ "GenSigTimeout_RHSC2" SG_ 992 VIN_MSG 1050;
BA_ "GenSigTimeout_IC" SG_ 992 VIN_MSG 1050;
BA_ "GenSigTimeout_OCM" SG_ 992 VIN_MSG 5050;
BA_ "GenSigTimeout_ORC" SG_ 992 VIN_MSG 350;
BA_ "GenSigTimeout_RF_HUB" SG_ 992 VIN_MSG 1050;
BA_ "GenSigTimeout_SCCM" SG_ 992 VIN_MSG 1050;
BA_ "RID" SG_ 992 VIN_MSG "1275";
BA_ "FlexKomComment" SG_ 1000 VC_AUTO_HB "Vehicle Configuration 1 Packet";
BA_ "FlexKomIsMotorola" SG_ 1000 VC_AUTO_HB 1;
BA_ "FlexKomSID" SG_ 1000 VC_AUTO_HB 886;
BA_ "FlexKomSigLaenge" SG_ 1000 VC_AUTO_HB 64;
BA_ "FlexKomSigName" SG_ 1000 VC_AUTO_HB "VehCfg1_Pkt";
BA_ "FlexKomSigStartPos" SG_ 1000 VC_AUTO_HB 7;
BA_ "FlexKomSigStartValue" SG_ 1000 VC_AUTO_HB "FFFF7FF0FF0FFF00h";
BA_ "GenSigCycleTime" SG_ 1000 VC_AUTO_HB 500;
BA_ "GenSigSendType" SG_ 1000 VC_AUTO_HB 5;
BA_ "GenSigSNA" SG_ 1000 VC_AUTO_HB "0h";
BA_ "GenSigTimeout_IC" SG_ 1000 VC_AUTO_HB 5250;
BA_ "FlexKomComment" SG_ 1000 VC_BODY_STYLE "Vehicle Configuration 1 Packet";
BA_ "FlexKomIsMotorola" SG_ 1000 VC_BODY_STYLE 1;
BA_ "FlexKomSID" SG_ 1000 VC_BODY_STYLE 886;
BA_ "FlexKomSigLaenge" SG_ 1000 VC_BODY_STYLE 64;
BA_ "FlexKomSigName" SG_ 1000 VC_BODY_STYLE "VehCfg1_Pkt";
BA_ "FlexKomSigStartPos" SG_ 1000 VC_BODY_STYLE 7;
BA_ "FlexKomSigStartValue" SG_ 1000 VC_BODY_STYLE "FFFF7FF0FF0FFF00h";
BA_ "GenSigCycleTime" SG_ 1000 VC_BODY_STYLE 500;
BA_ "GenSigSendType" SG_ 1000 VC_BODY_STYLE 5;
BA_ "GenSigSNA" SG_ 1000 VC_BODY_STYLE "Fh";
BA_ "GenSigStartValue" SG_ 1000 VC_BODY_STYLE 15;
BA_ "GenSigTimeout_EPS" SG_ 1000 VC_BODY_STYLE 5250;
BA_ "GenSigTimeout_RHSC2" SG_ 1000 VC_BODY_STYLE 5250;
BA_ "GenSigTimeout_IC" SG_ 1000 VC_BODY_STYLE 5250;
BA_ "GenSigTimeout_ORC" SG_ 1000 VC_BODY_STYLE 1750;
BA_ "GenSigTimeout_SCCM" SG_ 1000 VC_BODY_STYLE 5250;
BA_ "RID" SG_ 1000 VC_BODY_STYLE "9602";
BA_ "FlexKomComment" SG_ 1000 VC_CHMCM_Prsnt "Vehicle Configuration 1 Packet";
BA_ "FlexKomIsMotorola" SG_ 1000 VC_CHMCM_Prsnt 1;
BA_ "FlexKomSID" SG_ 1000 VC_CHMCM_Prsnt 886;
BA_ "FlexKomSigLaenge" SG_ 1000 VC_CHMCM_Prsnt 64;
BA_ "FlexKomSigName" SG_ 1000 VC_CHMCM_Prsnt "VehCfg1_Pkt";
BA_ "FlexKomSigStartPos" SG_ 1000 VC_CHMCM_Prsnt 7;
BA_ "FlexKomSigStartValue" SG_ 1000 VC_CHMCM_Prsnt "FFFF7FF0FF0FFF00h";
BA_ "GenSigCycleTime" SG_ 1000 VC_CHMCM_Prsnt 500;
BA_ "GenSigSendType" SG_ 1000 VC_CHMCM_Prsnt 5;
BA_ "GenSigSNA" SG_ 1000 VC_CHMCM_Prsnt "0h";
BA_ "FlexKomComment" SG_ 1000 VC_COUNTRY "Vehicle Configuration 1 Packet";
BA_ "FlexKomIsMotorola" SG_ 1000 VC_COUNTRY 1;
BA_ "FlexKomSID" SG_ 1000 VC_COUNTRY 886;
BA_ "FlexKomSigLaenge" SG_ 1000 VC_COUNTRY 64;
BA_ "FlexKomSigName" SG_ 1000 VC_COUNTRY "VehCfg1_Pkt";
BA_ "FlexKomSigStartPos" SG_ 1000 VC_COUNTRY 7;
BA_ "FlexKomSigStartValue" SG_ 1000 VC_COUNTRY "FFFF7FF0FF0FFF00h";
BA_ "GenSigCycleTime" SG_ 1000 VC_COUNTRY 500;
BA_ "GenSigSendType" SG_ 1000 VC_COUNTRY 5;
BA_ "GenSigSNA" SG_ 1000 VC_COUNTRY "1Fh";
BA_ "GenSigStartValue" SG_ 1000 VC_COUNTRY 31;
BA_ "GenSigTimeout_EPS" SG_ 1000 VC_COUNTRY 5250;
BA_ "GenSigTimeout_RHSC2" SG_ 1000 VC_COUNTRY 5250;
BA_ "GenSigTimeout_IC" SG_ 1000 VC_COUNTRY 5250;
BA_ "GenSigTimeout_ORC" SG_ 1000 VC_COUNTRY 1750;
BA_ "GenSigTimeout_SCCM" SG_ 1000 VC_COUNTRY 5250;
BA_ "RID" SG_ 1000 VC_COUNTRY "9603";
BA_ "FlexKomComment" SG_ 1000 VC_EmodePrsnt "Vehicle Configuration 1 Packet";
BA_ "FlexKomIsMotorola" SG_ 1000 VC_EmodePrsnt 1;
BA_ "FlexKomSID" SG_ 1000 VC_EmodePrsnt 886;
BA_ "FlexKomSigLaenge" SG_ 1000 VC_EmodePrsnt 64;
BA_ "FlexKomSigName" SG_ 1000 VC_EmodePrsnt "VehCfg1_Pkt";
BA_ "FlexKomSigStartPos" SG_ 1000 VC_EmodePrsnt 7;
BA_ "FlexKomSigStartValue" SG_ 1000 VC_EmodePrsnt "FFFF7FF0FF0FFF00h";
BA_ "GenSigCycleTime" SG_ 1000 VC_EmodePrsnt 500;
BA_ "GenSigSendType" SG_ 1000 VC_EmodePrsnt 5;
BA_ "GenSigSNA" SG_ 1000 VC_EmodePrsnt "0h";
BA_ "FlexKomComment" SG_ 1000 VC_HDC_Prsnt "Vehicle Configuration 1 Packet";
BA_ "FlexKomIsMotorola" SG_ 1000 VC_HDC_Prsnt 1;
BA_ "FlexKomSID" SG_ 1000 VC_HDC_Prsnt 886;
BA_ "FlexKomSigLaenge" SG_ 1000 VC_HDC_Prsnt 64;
BA_ "FlexKomSigName" SG_ 1000 VC_HDC_Prsnt "VehCfg1_Pkt";
BA_ "FlexKomSigStartPos" SG_ 1000 VC_HDC_Prsnt 7;
BA_ "FlexKomSigStartValue" SG_ 1000 VC_HDC_Prsnt "FFFF7FF0FF0FFF00h";
BA_ "GenSigCycleTime" SG_ 1000 VC_HDC_Prsnt 500;
BA_ "GenSigSendType" SG_ 1000 VC_HDC_Prsnt 5;
BA_ "GenSigSNA" SG_ 1000 VC_HDC_Prsnt "0h";
BA_ "GenSigTimeout_IC" SG_ 1000 VC_HDC_Prsnt 5250;
BA_ "FlexKomComment" SG_ 1000 VC_HdRstPrsnt "Vehicle Configuration 1 Packet";
BA_ "FlexKomIsMotorola" SG_ 1000 VC_HdRstPrsnt 1;
BA_ "FlexKomSID" SG_ 1000 VC_HdRstPrsnt 886;
BA_ "FlexKomSigLaenge" SG_ 1000 VC_HdRstPrsnt 64;
BA_ "FlexKomSigName" SG_ 1000 VC_HdRstPrsnt "VehCfg1_Pkt";
BA_ "FlexKomSigStartPos" SG_ 1000 VC_HdRstPrsnt 7;
BA_ "FlexKomSigStartValue" SG_ 1000 VC_HdRstPrsnt "FFFF7FF0FF0FFF00h";
BA_ "GenSigCycleTime" SG_ 1000 VC_HdRstPrsnt 500;
BA_ "GenSigSendType" SG_ 1000 VC_HdRstPrsnt 5;
BA_ "GenSigSNA" SG_ 1000 VC_HdRstPrsnt "0h";
BA_ "FlexKomComment" SG_ 1000 VC_LHD_RHD "Vehicle Configuration 1 Packet";
BA_ "FlexKomIsMotorola" SG_ 1000 VC_LHD_RHD 1;
BA_ "FlexKomSID" SG_ 1000 VC_LHD_RHD 886;
BA_ "FlexKomSigLaenge" SG_ 1000 VC_LHD_RHD 64;
BA_ "FlexKomSigName" SG_ 1000 VC_LHD_RHD "VehCfg1_Pkt";
BA_ "FlexKomSigStartPos" SG_ 1000 VC_LHD_RHD 7;
BA_ "FlexKomSigStartValue" SG_ 1000 VC_LHD_RHD "FFFF7FF0FF0FFF00h";
BA_ "GenSigCycleTime" SG_ 1000 VC_LHD_RHD 500;
BA_ "GenSigSendType" SG_ 1000 VC_LHD_RHD 5;
BA_ "GenSigSNA" SG_ 1000 VC_LHD_RHD "3h";
BA_ "GenSigStartValue" SG_ 1000 VC_LHD_RHD 3;
BA_ "GenSigTimeout_RHSC2" SG_ 1000 VC_LHD_RHD 5250;
BA_ "GenSigTimeout_IC" SG_ 1000 VC_LHD_RHD 5250;
BA_ "GenSigTimeout_ORC" SG_ 1000 VC_LHD_RHD 1750;
BA_ "RID" SG_ 1000 VC_LHD_RHD "9755";
BA_ "FlexKomComment" SG_ 1000 VC_MAX_VEH_SPD "Vehicle Configuration 1 Packet";
BA_ "FlexKomIsMotorola" SG_ 1000 VC_MAX_VEH_SPD 1;
BA_ "FlexKomSID" SG_ 1000 VC_MAX_VEH_SPD 886;
BA_ "FlexKomSigLaenge" SG_ 1000 VC_MAX_VEH_SPD 64;
BA_ "FlexKomSigName" SG_ 1000 VC_MAX_VEH_SPD "VehCfg1_Pkt";
BA_ "FlexKomSigStartPos" SG_ 1000 VC_MAX_VEH_SPD 7;
BA_ "FlexKomSigStartValue" SG_ 1000 VC_MAX_VEH_SPD "FFFF7FF0FF0FFF00h";
BA_ "GenSigCycleTime" SG_ 1000 VC_MAX_VEH_SPD 500;
BA_ "GenSigSendType" SG_ 1000 VC_MAX_VEH_SPD 5;
BA_ "GenSigSNA" SG_ 1000 VC_MAX_VEH_SPD "FFh";
BA_ "GenSigStartValue" SG_ 1000 VC_MAX_VEH_SPD 255;
BA_ "FlexKomComment" SG_ 1000 VC_MODEL_YEAR "Vehicle Configuration 1 Packet";
BA_ "FlexKomIsMotorola" SG_ 1000 VC_MODEL_YEAR 1;
BA_ "FlexKomSID" SG_ 1000 VC_MODEL_YEAR 886;
BA_ "FlexKomSigLaenge" SG_ 1000 VC_MODEL_YEAR 64;
BA_ "FlexKomSigName" SG_ 1000 VC_MODEL_YEAR "VehCfg1_Pkt";
BA_ "FlexKomSigStartPos" SG_ 1000 VC_MODEL_YEAR 7;
BA_ "FlexKomSigStartValue" SG_ 1000 VC_MODEL_YEAR "FFFF7FF0FF0FFF00h";
BA_ "GenSigCycleTime" SG_ 1000 VC_MODEL_YEAR 500;
BA_ "GenSigSendType" SG_ 1000 VC_MODEL_YEAR 5;
BA_ "GenSigSNA" SG_ 1000 VC_MODEL_YEAR "3Fh";
BA_ "GenSigStartValue" SG_ 1000 VC_MODEL_YEAR 63;
BA_ "GenSigTimeout_EPS" SG_ 1000 VC_MODEL_YEAR 5250;
BA_ "GenSigTimeout_RHSC2" SG_ 1000 VC_MODEL_YEAR 5250;
BA_ "GenSigTimeout_IC" SG_ 1000 VC_MODEL_YEAR 5250;
BA_ "GenSigTimeout_ORC" SG_ 1000 VC_MODEL_YEAR 1750;
BA_ "GenSigTimeout_SCCM" SG_ 1000 VC_MODEL_YEAR 5250;
BA_ "RID" SG_ 1000 VC_MODEL_YEAR "9604";
BA_ "FlexKomComment" SG_ 1000 VC_PP_Prsnt "Vehicle Configuration 1 Packet";
BA_ "FlexKomIsMotorola" SG_ 1000 VC_PP_Prsnt 1;
BA_ "FlexKomSID" SG_ 1000 VC_PP_Prsnt 886;
BA_ "FlexKomSigLaenge" SG_ 1000 VC_PP_Prsnt 64;
BA_ "FlexKomSigName" SG_ 1000 VC_PP_Prsnt "VehCfg1_Pkt";
BA_ "FlexKomSigStartPos" SG_ 1000 VC_PP_Prsnt 7;
BA_ "FlexKomSigStartValue" SG_ 1000 VC_PP_Prsnt "FFFF7FF0FF0FFF00h";
BA_ "GenSigCycleTime" SG_ 1000 VC_PP_Prsnt 500;
BA_ "GenSigSendType" SG_ 1000 VC_PP_Prsnt 5;
BA_ "GenSigSNA" SG_ 1000 VC_PP_Prsnt "0h";
BA_ "GenSigTimeout_IC" SG_ 1000 VC_PP_Prsnt 5250;
BA_ "FlexKomComment" SG_ 1000 VC_PTS_Config "Vehicle Configuration 1 Packet";
BA_ "FlexKomIsMotorola" SG_ 1000 VC_PTS_Config 1;
BA_ "FlexKomSID" SG_ 1000 VC_PTS_Config 886;
BA_ "FlexKomSigLaenge" SG_ 1000 VC_PTS_Config 64;
BA_ "FlexKomSigName" SG_ 1000 VC_PTS_Config "VehCfg1_Pkt";
BA_ "FlexKomSigStartPos" SG_ 1000 VC_PTS_Config 7;
BA_ "FlexKomSigStartValue" SG_ 1000 VC_PTS_Config "FFFF7FF0FF0FFF00h";
BA_ "GenSigCycleTime" SG_ 1000 VC_PTS_Config 500;
BA_ "GenSigSendType" SG_ 1000 VC_PTS_Config 5;
BA_ "GenSigSNA" SG_ 1000 VC_PTS_Config "0h";
BA_ "GenSigTimeout_IC" SG_ 1000 VC_PTS_Config 5250;
BA_ "GenSigTimeout_PTS" SG_ 1000 VC_PTS_Config 2750;
BA_ "FlexKomComment" SG_ 1000 VC_PTS_DispTyp "Vehicle Configuration 1 Packet";
BA_ "FlexKomIsMotorola" SG_ 1000 VC_PTS_DispTyp 1;
BA_ "FlexKomSID" SG_ 1000 VC_PTS_DispTyp 886;
BA_ "FlexKomSigLaenge" SG_ 1000 VC_PTS_DispTyp 64;
BA_ "FlexKomSigName" SG_ 1000 VC_PTS_DispTyp "VehCfg1_Pkt";
BA_ "FlexKomSigStartPos" SG_ 1000 VC_PTS_DispTyp 7;
BA_ "FlexKomSigStartValue" SG_ 1000 VC_PTS_DispTyp "FFFF7FF0FF0FFF00h";
BA_ "GenSigCycleTime" SG_ 1000 VC_PTS_DispTyp 500;
BA_ "GenSigSendType" SG_ 1000 VC_PTS_DispTyp 5;
BA_ "GenSigSNA" SG_ 1000 VC_PTS_DispTyp "7h";
BA_ "GenSigTimeout_PTS" SG_ 1000 VC_PTS_DispTyp 2750;
BA_ "FlexKomComment" SG_ 1000 VC_RVCM_Prsnt "Vehicle Configuration 1 Packet";
BA_ "FlexKomIsMotorola" SG_ 1000 VC_RVCM_Prsnt 1;
BA_ "FlexKomSID" SG_ 1000 VC_RVCM_Prsnt 886;
BA_ "FlexKomSigLaenge" SG_ 1000 VC_RVCM_Prsnt 64;
BA_ "FlexKomSigName" SG_ 1000 VC_RVCM_Prsnt "VehCfg1_Pkt";
BA_ "FlexKomSigStartPos" SG_ 1000 VC_RVCM_Prsnt 7;
BA_ "FlexKomSigStartValue" SG_ 1000 VC_RVCM_Prsnt "FFFF7FF0FF0FFF00h";
BA_ "GenSigCycleTime" SG_ 1000 VC_RVCM_Prsnt 500;
BA_ "GenSigSendType" SG_ 1000 VC_RVCM_Prsnt 5;
BA_ "GenSigSNA" SG_ 1000 VC_RVCM_Prsnt "0h";
BA_ "FlexKomComment" SG_ 1000 VC_RemStPrsnt "Vehicle Configuration 1 Packet";
BA_ "FlexKomIsMotorola" SG_ 1000 VC_RemStPrsnt 1;
BA_ "FlexKomSID" SG_ 1000 VC_RemStPrsnt 886;
BA_ "FlexKomSigLaenge" SG_ 1000 VC_RemStPrsnt 64;
BA_ "FlexKomSigName" SG_ 1000 VC_RemStPrsnt "VehCfg1_Pkt";
BA_ "FlexKomSigStartPos" SG_ 1000 VC_RemStPrsnt 7;
BA_ "FlexKomSigStartValue" SG_ 1000 VC_RemStPrsnt "FFFF7FF0FF0FFF00h";
BA_ "GenSigCycleTime" SG_ 1000 VC_RemStPrsnt 500;
BA_ "GenSigSendType" SG_ 1000 VC_RemStPrsnt 5;
BA_ "GenSigSNA" SG_ 1000 VC_RemStPrsnt "0h";
BA_ "GenSigTimeout_IC" SG_ 1000 VC_RemStPrsnt 5250;
BA_ "FlexKomComment" SG_ 1000 VC_SCR_Prsnt "Vehicle Configuration 1 Packet";
BA_ "FlexKomIsMotorola" SG_ 1000 VC_SCR_Prsnt 1;
BA_ "FlexKomSID" SG_ 1000 VC_SCR_Prsnt 886;
BA_ "FlexKomSigLaenge" SG_ 1000 VC_SCR_Prsnt 64;
BA_ "FlexKomSigName" SG_ 1000 VC_SCR_Prsnt "VehCfg1_Pkt";
BA_ "FlexKomSigStartPos" SG_ 1000 VC_SCR_Prsnt 7;
BA_ "FlexKomSigStartValue" SG_ 1000 VC_SCR_Prsnt "FFFF7FF0FF0FFF00h";
BA_ "GenSigCycleTime" SG_ 1000 VC_SCR_Prsnt 500;
BA_ "GenSigSendType" SG_ 1000 VC_SCR_Prsnt 5;
BA_ "GenSigSNA" SG_ 1000 VC_SCR_Prsnt "0h";
BA_ "GenSigTimeout_IC" SG_ 1000 VC_SCR_Prsnt 5250;
BA_ "FlexKomComment" SG_ 1000 VC_SSC_Prsnt "Vehicle Configuration 1 Packet";
BA_ "FlexKomIsMotorola" SG_ 1000 VC_SSC_Prsnt 1;
BA_ "FlexKomSID" SG_ 1000 VC_SSC_Prsnt 886;
BA_ "FlexKomSigLaenge" SG_ 1000 VC_SSC_Prsnt 64;
BA_ "FlexKomSigName" SG_ 1000 VC_SSC_Prsnt "VehCfg1_Pkt";
BA_ "FlexKomSigStartPos" SG_ 1000 VC_SSC_Prsnt 7;
BA_ "FlexKomSigStartValue" SG_ 1000 VC_SSC_Prsnt "FFFF7FF0FF0FFF00h";
BA_ "GenSigCycleTime" SG_ 1000 VC_SSC_Prsnt 500;
BA_ "GenSigSendType" SG_ 1000 VC_SSC_Prsnt 5;
BA_ "GenSigSNA" SG_ 1000 VC_SSC_Prsnt "0h";
BA_ "GenSigTimeout_IC" SG_ 1000 VC_SSC_Prsnt 5250;
BA_ "FlexKomComment" SG_ 1000 VC_ShftrTyp "Vehicle Configuration 1 Packet";
BA_ "FlexKomIsMotorola" SG_ 1000 VC_ShftrTyp 1;
BA_ "FlexKomSID" SG_ 1000 VC_ShftrTyp 886;
BA_ "FlexKomSigLaenge" SG_ 1000 VC_ShftrTyp 64;
BA_ "FlexKomSigName" SG_ 1000 VC_ShftrTyp "VehCfg1_Pkt";
BA_ "FlexKomSigStartPos" SG_ 1000 VC_ShftrTyp 7;
BA_ "FlexKomSigStartValue" SG_ 1000 VC_ShftrTyp "FFFF7FF0FF0FFF00h";
BA_ "GenSigCycleTime" SG_ 1000 VC_ShftrTyp 500;
BA_ "GenSigSendType" SG_ 1000 VC_ShftrTyp 5;
BA_ "GenSigSNA" SG_ 1000 VC_ShftrTyp "Fh";
BA_ "GenSigStartValue" SG_ 1000 VC_ShftrTyp 15;
BA_ "GenSigTimeout_RHSC2" SG_ 1000 VC_ShftrTyp 5250;
BA_ "GenSigTimeout_IC" SG_ 1000 VC_ShftrTyp 5250;
BA_ "RID" SG_ 1000 VC_ShftrTyp "9756";
BA_ "FlexKomComment" SG_ 1000 VC_SpecialPKG "Vehicle Configuration 1 Packet";
BA_ "FlexKomIsMotorola" SG_ 1000 VC_SpecialPKG 1;
BA_ "FlexKomSID" SG_ 1000 VC_SpecialPKG 886;
BA_ "FlexKomSigLaenge" SG_ 1000 VC_SpecialPKG 64;
BA_ "FlexKomSigName" SG_ 1000 VC_SpecialPKG "VehCfg1_Pkt";
BA_ "FlexKomSigStartPos" SG_ 1000 VC_SpecialPKG 7;
BA_ "FlexKomSigStartValue" SG_ 1000 VC_SpecialPKG "FFFF7FF0FF0FFF00h";
BA_ "GenSigCycleTime" SG_ 1000 VC_SpecialPKG 500;
BA_ "GenSigSendType" SG_ 1000 VC_SpecialPKG 5;
BA_ "GenSigSNA" SG_ 1000 VC_SpecialPKG "FFh";
BA_ "GenSigStartValue" SG_ 1000 VC_SpecialPKG 255;
BA_ "GenSigTimeout_IC" SG_ 1000 VC_SpecialPKG 5250;
BA_ "GenSigTimeout_ORC" SG_ 1000 VC_SpecialPKG 1750;
BA_ "FlexKomComment" SG_ 1000 VC_VEH_LINE "Vehicle Configuration 1 Packet";
BA_ "FlexKomIsMotorola" SG_ 1000 VC_VEH_LINE 1;
BA_ "FlexKomSID" SG_ 1000 VC_VEH_LINE 886;
BA_ "FlexKomSigLaenge" SG_ 1000 VC_VEH_LINE 64;
BA_ "FlexKomSigName" SG_ 1000 VC_VEH_LINE "VehCfg1_Pkt";
BA_ "FlexKomSigStartPos" SG_ 1000 VC_VEH_LINE 7;
BA_ "FlexKomSigStartValue" SG_ 1000 VC_VEH_LINE "FFFF7FF0FF0FFF00h";
BA_ "GenSigCycleTime" SG_ 1000 VC_VEH_LINE 500;
BA_ "GenSigSendType" SG_ 1000 VC_VEH_LINE 5;
BA_ "GenSigSNA" SG_ 1000 VC_VEH_LINE "FFh";
BA_ "GenSigStartValue" SG_ 1000 VC_VEH_LINE 255;
BA_ "GenSigTimeout_EPS" SG_ 1000 VC_VEH_LINE 5250;
BA_ "GenSigTimeout_RHSC2" SG_ 1000 VC_VEH_LINE 5250;
BA_ "GenSigTimeout_IC" SG_ 1000 VC_VEH_LINE 5250;
BA_ "GenSigTimeout_OCM" SG_ 1000 VC_VEH_LINE 2750;
BA_ "GenSigTimeout_ORC" SG_ 1000 VC_VEH_LINE 1750;
BA_ "GenSigTimeout_SCCM" SG_ 1000 VC_VEH_LINE 5250;
BA_ "RID" SG_ 1000 VC_VEH_LINE "9605";
BA_ "FlexKomComment" SG_ 1000 VC_VehCfg1_Stat "Vehicle Configuration 1 Packet";
BA_ "FlexKomIsMotorola" SG_ 1000 VC_VehCfg1_Stat 1;
BA_ "FlexKomSID" SG_ 1000 VC_VehCfg1_Stat 886;
BA_ "FlexKomSigLaenge" SG_ 1000 VC_VehCfg1_Stat 64;
BA_ "FlexKomSigName" SG_ 1000 VC_VehCfg1_Stat "VehCfg1_Pkt";
BA_ "FlexKomSigStartPos" SG_ 1000 VC_VehCfg1_Stat 7;
BA_ "FlexKomSigStartValue" SG_ 1000 VC_VehCfg1_Stat "FFFF7FF0FF0FFF00h";
BA_ "GenSigCycleTime" SG_ 1000 VC_VehCfg1_Stat 500;
BA_ "GenSigSendType" SG_ 1000 VC_VehCfg1_Stat 5;
BA_ "GenSigSNA" SG_ 1000 VC_VehCfg1_Stat "3h";
BA_ "GenSigStartValue" SG_ 1000 VC_VehCfg1_Stat 3;
BA_ "GenSigTimeout_EPS" SG_ 1000 VC_VehCfg1_Stat 5250;
BA_ "GenSigTimeout_RHSC2" SG_ 1000 VC_VehCfg1_Stat 5250;
BA_ "GenSigTimeout_IC" SG_ 1000 VC_VehCfg1_Stat 5250;
BA_ "GenSigTimeout_OCM" SG_ 1000 VC_VehCfg1_Stat 5250;
BA_ "GenSigTimeout_ORC" SG_ 1000 VC_VehCfg1_Stat 1750;
BA_ "GenSigTimeout_SCCM" SG_ 1000 VC_VehCfg1_Stat 5250;
BA_ "RID" SG_ 1000 VC_VehCfg1_Stat "9606";
BA_ "FlexKomComment" SG_ 1000 VC_XWD "Vehicle Configuration 1 Packet";
BA_ "FlexKomIsMotorola" SG_ 1000 VC_XWD 1;
BA_ "FlexKomSID" SG_ 1000 VC_XWD 886;
BA_ "FlexKomSigLaenge" SG_ 1000 VC_XWD 64;
BA_ "FlexKomSigName" SG_ 1000 VC_XWD "VehCfg1_Pkt";
BA_ "FlexKomSigStartPos" SG_ 1000 VC_XWD 7;
BA_ "FlexKomSigStartValue" SG_ 1000 VC_XWD "FFFF7FF0FF0FFF00h";
BA_ "GenSigCycleTime" SG_ 1000 VC_XWD 500;
BA_ "GenSigSendType" SG_ 1000 VC_XWD 5;
BA_ "GenSigSNA" SG_ 1000 VC_XWD "0h";
BA_ "GenSigTimeout_RHSC2" SG_ 1000 VC_XWD 5250;
BA_ "GenSigTimeout_IC" SG_ 1000 VC_XWD 5250;
BA_ "GenSigTimeout_ORC" SG_ 1000 VC_XWD 1750;
BA_ "RID" SG_ 1000 VC_XWD "9757";
BA_ "FlexKomComment" SG_ 1001 VC_AC_Prsnt "Vehicle Configuration 2 Packet";
BA_ "FlexKomIsMotorola" SG_ 1001 VC_AC_Prsnt 1;
BA_ "FlexKomSID" SG_ 1001 VC_AC_Prsnt 887;
BA_ "FlexKomSigLaenge" SG_ 1001 VC_AC_Prsnt 64;
BA_ "FlexKomSigName" SG_ 1001 VC_AC_Prsnt "VehCfg2_Pkt";
BA_ "FlexKomSigStartPos" SG_ 1001 VC_AC_Prsnt 7;
BA_ "FlexKomSigStartValue" SG_ 1001 VC_AC_Prsnt "0300FF00FFFFFFFFh";
BA_ "GenSigCycleTime" SG_ 1001 VC_AC_Prsnt 2000;
BA_ "GenSigSendType" SG_ 1001 VC_AC_Prsnt 5;
BA_ "GenSigSNA" SG_ 1001 VC_AC_Prsnt "0h";
BA_ "FlexKomComment" SG_ 1001 VC_CRUISE_PRSNT "Vehicle Configuration 2 Packet";
BA_ "FlexKomIsMotorola" SG_ 1001 VC_CRUISE_PRSNT 1;
BA_ "FlexKomSID" SG_ 1001 VC_CRUISE_PRSNT 887;
BA_ "FlexKomSigLaenge" SG_ 1001 VC_CRUISE_PRSNT 64;
BA_ "FlexKomSigName" SG_ 1001 VC_CRUISE_PRSNT "VehCfg2_Pkt";
BA_ "FlexKomSigStartPos" SG_ 1001 VC_CRUISE_PRSNT 7;
BA_ "FlexKomSigStartValue" SG_ 1001 VC_CRUISE_PRSNT "0300FF00FFFFFFFFh";
BA_ "GenSigCycleTime" SG_ 1001 VC_CRUISE_PRSNT 2000;
BA_ "GenSigSendType" SG_ 1001 VC_CRUISE_PRSNT 5;
BA_ "GenSigSNA" SG_ 1001 VC_CRUISE_PRSNT "0h";
BA_ "GenSigTimeout_IC" SG_ 1001 VC_CRUISE_PRSNT 21000;
BA_ "GenSigTimeout_ORC" SG_ 1001 VC_CRUISE_PRSNT 7000;
BA_ "FlexKomComment" SG_ 1001 VC_DRVMD_Prsnt "Vehicle Configuration 2 Packet";
BA_ "FlexKomIsMotorola" SG_ 1001 VC_DRVMD_Prsnt 1;
BA_ "FlexKomSID" SG_ 1001 VC_DRVMD_Prsnt 887;
BA_ "FlexKomSigLaenge" SG_ 1001 VC_DRVMD_Prsnt 64;
BA_ "FlexKomSigName" SG_ 1001 VC_DRVMD_Prsnt "VehCfg2_Pkt";
BA_ "FlexKomSigStartPos" SG_ 1001 VC_DRVMD_Prsnt 7;
BA_ "FlexKomSigStartValue" SG_ 1001 VC_DRVMD_Prsnt "0300FF00FFFFFFFFh";
BA_ "GenSigCycleTime" SG_ 1001 VC_DRVMD_Prsnt 2000;
BA_ "GenSigSendType" SG_ 1001 VC_DRVMD_Prsnt 5;
BA_ "GenSigSNA" SG_ 1001 VC_DRVMD_Prsnt "0h";
BA_ "GenSigTimeout_EPS" SG_ 1001 VC_DRVMD_Prsnt 21000;
BA_ "FlexKomComment" SG_ 1001 VC_ECO_Indicator "Vehicle Configuration 2 Packet";
BA_ "FlexKomIsMotorola" SG_ 1001 VC_ECO_Indicator 1;
BA_ "FlexKomSID" SG_ 1001 VC_ECO_Indicator 887;
BA_ "FlexKomSigLaenge" SG_ 1001 VC_ECO_Indicator 64;
BA_ "FlexKomSigName" SG_ 1001 VC_ECO_Indicator "VehCfg2_Pkt";
BA_ "FlexKomSigStartPos" SG_ 1001 VC_ECO_Indicator 7;
BA_ "FlexKomSigStartValue" SG_ 1001 VC_ECO_Indicator "0300FF00FFFFFFFFh";
BA_ "GenSigCycleTime" SG_ 1001 VC_ECO_Indicator 2000;
BA_ "GenSigSendType" SG_ 1001 VC_ECO_Indicator 5;
BA_ "GenSigSNA" SG_ 1001 VC_ECO_Indicator "0h";
BA_ "GenSigTimeout_IC" SG_ 1001 VC_ECO_Indicator 21000;
BA_ "FlexKomComment" SG_ 1001 VC_ESCDrvMd_Prsnt "Vehicle Configuration 2 Packet";
BA_ "FlexKomIsMotorola" SG_ 1001 VC_ESCDrvMd_Prsnt 1;
BA_ "FlexKomSID" SG_ 1001 VC_ESCDrvMd_Prsnt 887;
BA_ "FlexKomSigLaenge" SG_ 1001 VC_ESCDrvMd_Prsnt 64;
BA_ "FlexKomSigName" SG_ 1001 VC_ESCDrvMd_Prsnt "VehCfg2_Pkt";
BA_ "FlexKomSigStartPos" SG_ 1001 VC_ESCDrvMd_Prsnt 7;
BA_ "FlexKomSigStartValue" SG_ 1001 VC_ESCDrvMd_Prsnt "0300FF00FFFFFFFFh";
BA_ "GenSigCycleTime" SG_ 1001 VC_ESCDrvMd_Prsnt 2000;
BA_ "GenSigSendType" SG_ 1001 VC_ESCDrvMd_Prsnt 5;
BA_ "GenSigSNA" SG_ 1001 VC_ESCDrvMd_Prsnt "0h";
BA_ "GenSigTimeout_IC" SG_ 1001 VC_ESCDrvMd_Prsnt 21000;
BA_ "FlexKomComment" SG_ 1001 VC_EngPowerDrvMd_Prsnt "Vehicle Configuration 2 Packet";
BA_ "FlexKomIsMotorola" SG_ 1001 VC_EngPowerDrvMd_Prsnt 1;
BA_ "FlexKomSID" SG_ 1001 VC_EngPowerDrvMd_Prsnt 887;
BA_ "FlexKomSigLaenge" SG_ 1001 VC_EngPowerDrvMd_Prsnt 64;
BA_ "FlexKomSigName" SG_ 1001 VC_EngPowerDrvMd_Prsnt "VehCfg2_Pkt";
BA_ "FlexKomSigStartPos" SG_ 1001 VC_EngPowerDrvMd_Prsnt 7;
BA_ "FlexKomSigStartValue" SG_ 1001 VC_EngPowerDrvMd_Prsnt "0300FF00FFFFFFFFh";
BA_ "GenSigCycleTime" SG_ 1001 VC_EngPowerDrvMd_Prsnt 2000;
BA_ "GenSigSendType" SG_ 1001 VC_EngPowerDrvMd_Prsnt 5;
BA_ "GenSigSNA" SG_ 1001 VC_EngPowerDrvMd_Prsnt "0h";
BA_ "GenSigTimeout_IC" SG_ 1001 VC_EngPowerDrvMd_Prsnt 21000;
BA_ "FlexKomComment" SG_ 1001 VC_FG_PRSNT "Vehicle Configuration 2 Packet";
BA_ "FlexKomIsMotorola" SG_ 1001 VC_FG_PRSNT 1;
BA_ "FlexKomSID" SG_ 1001 VC_FG_PRSNT 887;
BA_ "FlexKomSigLaenge" SG_ 1001 VC_FG_PRSNT 64;
BA_ "FlexKomSigName" SG_ 1001 VC_FG_PRSNT "VehCfg2_Pkt";
BA_ "FlexKomSigStartPos" SG_ 1001 VC_FG_PRSNT 7;
BA_ "FlexKomSigStartValue" SG_ 1001 VC_FG_PRSNT "0300FF00FFFFFFFFh";
BA_ "GenSigCycleTime" SG_ 1001 VC_FG_PRSNT 2000;
BA_ "GenSigSendType" SG_ 1001 VC_FG_PRSNT 5;
BA_ "GenSigSNA" SG_ 1001 VC_FG_PRSNT "0h";
BA_ "GenSigTimeout_IC" SG_ 1001 VC_FG_PRSNT 21000;
BA_ "FlexKomComment" SG_ 1001 VC_FULL_SPARE "Vehicle Configuration 2 Packet";
BA_ "FlexKomIsMotorola" SG_ 1001 VC_FULL_SPARE 1;
BA_ "FlexKomSID" SG_ 1001 VC_FULL_SPARE 887;
BA_ "FlexKomSigLaenge" SG_ 1001 VC_FULL_SPARE 64;
BA_ "FlexKomSigName" SG_ 1001 VC_FULL_SPARE "VehCfg2_Pkt";
BA_ "FlexKomSigStartPos" SG_ 1001 VC_FULL_SPARE 7;
BA_ "FlexKomSigStartValue" SG_ 1001 VC_FULL_SPARE "0300FF00FFFFFFFFh";
BA_ "GenSigCycleTime" SG_ 1001 VC_FULL_SPARE 2000;
BA_ "GenSigSendType" SG_ 1001 VC_FULL_SPARE 5;
BA_ "GenSigSNA" SG_ 1001 VC_FULL_SPARE "0h";
BA_ "FlexKomComment" SG_ 1001 VC_LgtLdPressFtTr "Vehicle Configuration 2 Packet";
BA_ "FlexKomIsMotorola" SG_ 1001 VC_LgtLdPressFtTr 1;
BA_ "FlexKomSID" SG_ 1001 VC_LgtLdPressFtTr 887;
BA_ "FlexKomSigLaenge" SG_ 1001 VC_LgtLdPressFtTr 64;
BA_ "FlexKomSigName" SG_ 1001 VC_LgtLdPressFtTr "VehCfg2_Pkt";
BA_ "FlexKomSigStartPos" SG_ 1001 VC_LgtLdPressFtTr 7;
BA_ "FlexKomSigStartValue" SG_ 1001 VC_LgtLdPressFtTr "0300FF00FFFFFFFFh";
BA_ "GenSigCycleTime" SG_ 1001 VC_LgtLdPressFtTr 2000;
BA_ "GenSigSendType" SG_ 1001 VC_LgtLdPressFtTr 5;
BA_ "GenSigSNA" SG_ 1001 VC_LgtLdPressFtTr "FFh";
BA_ "GenSigStartValue" SG_ 1001 VC_LgtLdPressFtTr 255;
BA_ "GenSigTimeout_IC" SG_ 1001 VC_LgtLdPressFtTr 21000;
BA_ "FlexKomComment" SG_ 1001 VC_LgtLdPressRrTr "Vehicle Configuration 2 Packet";
BA_ "FlexKomIsMotorola" SG_ 1001 VC_LgtLdPressRrTr 1;
BA_ "FlexKomSID" SG_ 1001 VC_LgtLdPressRrTr 887;
BA_ "FlexKomSigLaenge" SG_ 1001 VC_LgtLdPressRrTr 64;
BA_ "FlexKomSigName" SG_ 1001 VC_LgtLdPressRrTr "VehCfg2_Pkt";
BA_ "FlexKomSigStartPos" SG_ 1001 VC_LgtLdPressRrTr 7;
BA_ "FlexKomSigStartValue" SG_ 1001 VC_LgtLdPressRrTr "0300FF00FFFFFFFFh";
BA_ "GenSigCycleTime" SG_ 1001 VC_LgtLdPressRrTr 2000;
BA_ "GenSigSendType" SG_ 1001 VC_LgtLdPressRrTr 5;
BA_ "GenSigSNA" SG_ 1001 VC_LgtLdPressRrTr "FFh";
BA_ "GenSigStartValue" SG_ 1001 VC_LgtLdPressRrTr 255;
BA_ "GenSigTimeout_IC" SG_ 1001 VC_LgtLdPressRrTr 21000;
BA_ "FlexKomComment" SG_ 1001 VC_MaseratiMd "Vehicle Configuration 2 Packet";
BA_ "FlexKomIsMotorola" SG_ 1001 VC_MaseratiMd 1;
BA_ "FlexKomSID" SG_ 1001 VC_MaseratiMd 887;
BA_ "FlexKomSigLaenge" SG_ 1001 VC_MaseratiMd 64;
BA_ "FlexKomSigName" SG_ 1001 VC_MaseratiMd "VehCfg2_Pkt";
BA_ "FlexKomSigStartPos" SG_ 1001 VC_MaseratiMd 7;
BA_ "FlexKomSigStartValue" SG_ 1001 VC_MaseratiMd "0300FF00FFFFFFFFh";
BA_ "GenSigCycleTime" SG_ 1001 VC_MaseratiMd 2000;
BA_ "GenSigSendType" SG_ 1001 VC_MaseratiMd 5;
BA_ "GenSigSNA" SG_ 1001 VC_MaseratiMd "3h";
BA_ "GenSigTimeout_IC" SG_ 1001 VC_MaseratiMd 21000;
BA_ "FlexKomComment" SG_ 1001 VC_MaxLdPressFtTr "Vehicle Configuration 2 Packet";
BA_ "FlexKomIsMotorola" SG_ 1001 VC_MaxLdPressFtTr 1;
BA_ "FlexKomSID" SG_ 1001 VC_MaxLdPressFtTr 887;
BA_ "FlexKomSigLaenge" SG_ 1001 VC_MaxLdPressFtTr 64;
BA_ "FlexKomSigName" SG_ 1001 VC_MaxLdPressFtTr "VehCfg2_Pkt";
BA_ "FlexKomSigStartPos" SG_ 1001 VC_MaxLdPressFtTr 7;
BA_ "FlexKomSigStartValue" SG_ 1001 VC_MaxLdPressFtTr "0300FF00FFFFFFFFh";
BA_ "GenSigCycleTime" SG_ 1001 VC_MaxLdPressFtTr 2000;
BA_ "GenSigSendType" SG_ 1001 VC_MaxLdPressFtTr 5;
BA_ "GenSigSNA" SG_ 1001 VC_MaxLdPressFtTr "FFh";
BA_ "GenSigStartValue" SG_ 1001 VC_MaxLdPressFtTr 255;
BA_ "GenSigTimeout_IC" SG_ 1001 VC_MaxLdPressFtTr 21000;
BA_ "FlexKomComment" SG_ 1001 VC_MaxLdPressRrTr "Vehicle Configuration 2 Packet";
BA_ "FlexKomIsMotorola" SG_ 1001 VC_MaxLdPressRrTr 1;
BA_ "FlexKomSID" SG_ 1001 VC_MaxLdPressRrTr 887;
BA_ "FlexKomSigLaenge" SG_ 1001 VC_MaxLdPressRrTr 64;
BA_ "FlexKomSigName" SG_ 1001 VC_MaxLdPressRrTr "VehCfg2_Pkt";
BA_ "FlexKomSigStartPos" SG_ 1001 VC_MaxLdPressRrTr 7;
BA_ "FlexKomSigStartValue" SG_ 1001 VC_MaxLdPressRrTr "0300FF00FFFFFFFFh";
BA_ "GenSigCycleTime" SG_ 1001 VC_MaxLdPressRrTr 2000;
BA_ "GenSigSendType" SG_ 1001 VC_MaxLdPressRrTr 5;
BA_ "GenSigSNA" SG_ 1001 VC_MaxLdPressRrTr "FFh";
BA_ "GenSigStartValue" SG_ 1001 VC_MaxLdPressRrTr 255;
BA_ "GenSigTimeout_IC" SG_ 1001 VC_MaxLdPressRrTr 21000;
BA_ "FlexKomComment" SG_ 1001 VC_MemoryDRVMD_Prsnt "Vehicle Configuration 2 Packet";
BA_ "FlexKomIsMotorola" SG_ 1001 VC_MemoryDRVMD_Prsnt 1;
BA_ "FlexKomSID" SG_ 1001 VC_MemoryDRVMD_Prsnt 887;
BA_ "FlexKomSigLaenge" SG_ 1001 VC_MemoryDRVMD_Prsnt 64;
BA_ "FlexKomSigName" SG_ 1001 VC_MemoryDRVMD_Prsnt "VehCfg2_Pkt";
BA_ "FlexKomSigStartPos" SG_ 1001 VC_MemoryDRVMD_Prsnt 7;
BA_ "FlexKomSigStartValue" SG_ 1001 VC_MemoryDRVMD_Prsnt "0300FF00FFFFFFFFh";
BA_ "GenSigCycleTime" SG_ 1001 VC_MemoryDRVMD_Prsnt 2000;
BA_ "GenSigSendType" SG_ 1001 VC_MemoryDRVMD_Prsnt 5;
BA_ "GenSigSNA" SG_ 1001 VC_MemoryDRVMD_Prsnt "0h";
BA_ "GenSigTimeout_EPS" SG_ 1001 VC_MemoryDRVMD_Prsnt 21000;
BA_ "FlexKomComment" SG_ 1001 VC_OffRoad "Vehicle Configuration 2 Packet";
BA_ "FlexKomIsMotorola" SG_ 1001 VC_OffRoad 1;
BA_ "FlexKomSID" SG_ 1001 VC_OffRoad 887;
BA_ "FlexKomSigLaenge" SG_ 1001 VC_OffRoad 64;
BA_ "FlexKomSigName" SG_ 1001 VC_OffRoad "VehCfg2_Pkt";
BA_ "FlexKomSigStartPos" SG_ 1001 VC_OffRoad 7;
BA_ "FlexKomSigStartValue" SG_ 1001 VC_OffRoad "0300FF00FFFFFFFFh";
BA_ "GenSigCycleTime" SG_ 1001 VC_OffRoad 2000;
BA_ "GenSigSendType" SG_ 1001 VC_OffRoad 5;
BA_ "GenSigSNA" SG_ 1001 VC_OffRoad "0h";
BA_ "GenSigTimeout_IC" SG_ 1001 VC_OffRoad 21000;
BA_ "GenSigTimeout_ORC" SG_ 1001 VC_OffRoad 7000;
BA_ "FlexKomComment" SG_ 1001 VC_PADS_Prsnt "Vehicle Configuration 2 Packet";
BA_ "FlexKomIsMotorola" SG_ 1001 VC_PADS_Prsnt 1;
BA_ "FlexKomSID" SG_ 1001 VC_PADS_Prsnt 887;
BA_ "FlexKomSigLaenge" SG_ 1001 VC_PADS_Prsnt 64;
BA_ "FlexKomSigName" SG_ 1001 VC_PADS_Prsnt "VehCfg2_Pkt";
BA_ "FlexKomSigStartPos" SG_ 1001 VC_PADS_Prsnt 7;
BA_ "FlexKomSigStartValue" SG_ 1001 VC_PADS_Prsnt "0300FF00FFFFFFFFh";
BA_ "GenSigCycleTime" SG_ 1001 VC_PADS_Prsnt 2000;
BA_ "GenSigSendType" SG_ 1001 VC_PADS_Prsnt 5;
BA_ "GenSigSNA" SG_ 1001 VC_PADS_Prsnt "0h";
BA_ "GenSigTimeout_IC" SG_ 1001 VC_PADS_Prsnt 21000;
BA_ "GenSigTimeout_ORC" SG_ 1001 VC_PADS_Prsnt 7000;
BA_ "FlexKomComment" SG_ 1001 VC_PwrIvtrTyp "Vehicle Configuration 2 Packet";
BA_ "FlexKomIsMotorola" SG_ 1001 VC_PwrIvtrTyp 1;
BA_ "FlexKomSID" SG_ 1001 VC_PwrIvtrTyp 887;
BA_ "FlexKomSigLaenge" SG_ 1001 VC_PwrIvtrTyp 64;
BA_ "FlexKomSigName" SG_ 1001 VC_PwrIvtrTyp "VehCfg2_Pkt";
BA_ "FlexKomSigStartPos" SG_ 1001 VC_PwrIvtrTyp 7;
BA_ "FlexKomSigStartValue" SG_ 1001 VC_PwrIvtrTyp "0300FF00FFFFFFFFh";
BA_ "GenSigCycleTime" SG_ 1001 VC_PwrIvtrTyp 2000;
BA_ "GenSigSendType" SG_ 1001 VC_PwrIvtrTyp 5;
BA_ "GenSigSNA" SG_ 1001 VC_PwrIvtrTyp "0h";
BA_ "FlexKomComment" SG_ 1001 VC_RainSnsPrsnt "Vehicle Configuration 2 Packet";
BA_ "FlexKomIsMotorola" SG_ 1001 VC_RainSnsPrsnt 1;
BA_ "FlexKomSID" SG_ 1001 VC_RainSnsPrsnt 887;
BA_ "FlexKomSigLaenge" SG_ 1001 VC_RainSnsPrsnt 64;
BA_ "FlexKomSigName" SG_ 1001 VC_RainSnsPrsnt "VehCfg2_Pkt";
BA_ "FlexKomSigStartPos" SG_ 1001 VC_RainSnsPrsnt 7;
BA_ "FlexKomSigStartValue" SG_ 1001 VC_RainSnsPrsnt "0300FF00FFFFFFFFh";
BA_ "GenSigCycleTime" SG_ 1001 VC_RainSnsPrsnt 2000;
BA_ "GenSigSendType" SG_ 1001 VC_RainSnsPrsnt 5;
BA_ "GenSigSNA" SG_ 1001 VC_RainSnsPrsnt "0h";
BA_ "GenSigTimeout_IC" SG_ 1001 VC_RainSnsPrsnt 21000;
BA_ "FlexKomComment" SG_ 1001 VC_RunFlatTirePrsnt "Vehicle Configuration 2 Packet";
BA_ "FlexKomIsMotorola" SG_ 1001 VC_RunFlatTirePrsnt 1;
BA_ "FlexKomSID" SG_ 1001 VC_RunFlatTirePrsnt 887;
BA_ "FlexKomSigLaenge" SG_ 1001 VC_RunFlatTirePrsnt 64;
BA_ "FlexKomSigName" SG_ 1001 VC_RunFlatTirePrsnt "VehCfg2_Pkt";
BA_ "FlexKomSigStartPos" SG_ 1001 VC_RunFlatTirePrsnt 7;
BA_ "FlexKomSigStartValue" SG_ 1001 VC_RunFlatTirePrsnt "0300FF00FFFFFFFFh";
BA_ "GenSigCycleTime" SG_ 1001 VC_RunFlatTirePrsnt 2000;
BA_ "GenSigSendType" SG_ 1001 VC_RunFlatTirePrsnt 5;
BA_ "GenSigSNA" SG_ 1001 VC_RunFlatTirePrsnt "0h";
BA_ "GenSigTimeout_IC" SG_ 1001 VC_RunFlatTirePrsnt 21000;
BA_ "FlexKomComment" SG_ 1001 VC_SKIM_PRSNT "Vehicle Configuration 2 Packet";
BA_ "FlexKomIsMotorola" SG_ 1001 VC_SKIM_PRSNT 1;
BA_ "FlexKomSID" SG_ 1001 VC_SKIM_PRSNT 887;
BA_ "FlexKomSigLaenge" SG_ 1001 VC_SKIM_PRSNT 64;
BA_ "FlexKomSigName" SG_ 1001 VC_SKIM_PRSNT "VehCfg2_Pkt";
BA_ "FlexKomSigStartPos" SG_ 1001 VC_SKIM_PRSNT 7;
BA_ "FlexKomSigStartValue" SG_ 1001 VC_SKIM_PRSNT "0300FF00FFFFFFFFh";
BA_ "GenSigCycleTime" SG_ 1001 VC_SKIM_PRSNT 2000;
BA_ "GenSigSendType" SG_ 1001 VC_SKIM_PRSNT 5;
BA_ "GenSigSNA" SG_ 1001 VC_SKIM_PRSNT "0h";
BA_ "FlexKomComment" SG_ 1001 VC_SecPrkPrsnt "Vehicle Configuration 2 Packet";
BA_ "FlexKomIsMotorola" SG_ 1001 VC_SecPrkPrsnt 1;
BA_ "FlexKomSID" SG_ 1001 VC_SecPrkPrsnt 887;
BA_ "FlexKomSigLaenge" SG_ 1001 VC_SecPrkPrsnt 64;
BA_ "FlexKomSigName" SG_ 1001 VC_SecPrkPrsnt "VehCfg2_Pkt";
BA_ "FlexKomSigStartPos" SG_ 1001 VC_SecPrkPrsnt 7;
BA_ "FlexKomSigStartValue" SG_ 1001 VC_SecPrkPrsnt "0300FF00FFFFFFFFh";
BA_ "GenSigCycleTime" SG_ 1001 VC_SecPrkPrsnt 2000;
BA_ "GenSigSendType" SG_ 1001 VC_SecPrkPrsnt 5;
BA_ "GenSigSNA" SG_ 1001 VC_SecPrkPrsnt "0h";
BA_ "GenSigTimeout_IC" SG_ 1001 VC_SecPrkPrsnt 21000;
BA_ "FlexKomComment" SG_ 1001 VC_ShftInd_Prsnt "Vehicle Configuration 2 Packet";
BA_ "FlexKomIsMotorola" SG_ 1001 VC_ShftInd_Prsnt 1;
BA_ "FlexKomSID" SG_ 1001 VC_ShftInd_Prsnt 887;
BA_ "FlexKomSigLaenge" SG_ 1001 VC_ShftInd_Prsnt 64;
BA_ "FlexKomSigName" SG_ 1001 VC_ShftInd_Prsnt "VehCfg2_Pkt";
BA_ "FlexKomSigStartPos" SG_ 1001 VC_ShftInd_Prsnt 7;
BA_ "FlexKomSigStartValue" SG_ 1001 VC_ShftInd_Prsnt "0300FF00FFFFFFFFh";
BA_ "GenSigCycleTime" SG_ 1001 VC_ShftInd_Prsnt 2000;
BA_ "GenSigSendType" SG_ 1001 VC_ShftInd_Prsnt 5;
BA_ "GenSigSNA" SG_ 1001 VC_ShftInd_Prsnt "0h";
BA_ "GenSigTimeout_IC" SG_ 1001 VC_ShftInd_Prsnt 21000;
BA_ "FlexKomComment" SG_ 1001 VC_SpecialPKG_IC "Vehicle Configuration 2 Packet";
BA_ "FlexKomIsMotorola" SG_ 1001 VC_SpecialPKG_IC 1;
BA_ "FlexKomSID" SG_ 1001 VC_SpecialPKG_IC 887;
BA_ "FlexKomSigLaenge" SG_ 1001 VC_SpecialPKG_IC 64;
BA_ "FlexKomSigName" SG_ 1001 VC_SpecialPKG_IC "VehCfg2_Pkt";
BA_ "FlexKomSigStartPos" SG_ 1001 VC_SpecialPKG_IC 7;
BA_ "FlexKomSigStartValue" SG_ 1001 VC_SpecialPKG_IC "0300FF00FFFFFFFFh";
BA_ "GenSigCycleTime" SG_ 1001 VC_SpecialPKG_IC 2000;
BA_ "GenSigSendType" SG_ 1001 VC_SpecialPKG_IC 5;
BA_ "GenSigSNA" SG_ 1001 VC_SpecialPKG_IC "FFh";
BA_ "GenSigStartValue" SG_ 1001 VC_SpecialPKG_IC 255;
BA_ "GenSigTimeout_IC" SG_ 1001 VC_SpecialPKG_IC 21000;
BA_ "GenSigTimeout_ORC" SG_ 1001 VC_SpecialPKG_IC 7000;
BA_ "FlexKomComment" SG_ 1001 VC_ThatchamPrsnt "Vehicle Configuration 2 Packet";
BA_ "FlexKomIsMotorola" SG_ 1001 VC_ThatchamPrsnt 1;
BA_ "FlexKomSID" SG_ 1001 VC_ThatchamPrsnt 887;
BA_ "FlexKomSigLaenge" SG_ 1001 VC_ThatchamPrsnt 64;
BA_ "FlexKomSigName" SG_ 1001 VC_ThatchamPrsnt "VehCfg2_Pkt";
BA_ "FlexKomSigStartPos" SG_ 1001 VC_ThatchamPrsnt 7;
BA_ "FlexKomSigStartValue" SG_ 1001 VC_ThatchamPrsnt "0300FF00FFFFFFFFh";
BA_ "GenSigCycleTime" SG_ 1001 VC_ThatchamPrsnt 2000;
BA_ "GenSigSendType" SG_ 1001 VC_ThatchamPrsnt 5;
BA_ "GenSigSNA" SG_ 1001 VC_ThatchamPrsnt "0h";
BA_ "GenSigTimeout_IC" SG_ 1001 VC_ThatchamPrsnt 21000;
BA_ "FlexKomComment" SG_ 1001 VC_VehCfg2_Stat "Vehicle Configuration 2 Packet";
BA_ "FlexKomIsMotorola" SG_ 1001 VC_VehCfg2_Stat 1;
BA_ "FlexKomSID" SG_ 1001 VC_VehCfg2_Stat 887;
BA_ "FlexKomSigLaenge" SG_ 1001 VC_VehCfg2_Stat 64;
BA_ "FlexKomSigName" SG_ 1001 VC_VehCfg2_Stat "VehCfg2_Pkt";
BA_ "FlexKomSigStartPos" SG_ 1001 VC_VehCfg2_Stat 7;
BA_ "FlexKomSigStartValue" SG_ 1001 VC_VehCfg2_Stat "0300FF00FFFFFFFFh";
BA_ "GenSigCycleTime" SG_ 1001 VC_VehCfg2_Stat 2000;
BA_ "GenSigSendType" SG_ 1001 VC_VehCfg2_Stat 5;
BA_ "GenSigSNA" SG_ 1001 VC_VehCfg2_Stat "3h";
BA_ "GenSigStartValue" SG_ 1001 VC_VehCfg2_Stat 3;
BA_ "GenSigTimeout_EPS" SG_ 1001 VC_VehCfg2_Stat 21000;
BA_ "GenSigTimeout_IC" SG_ 1001 VC_VehCfg2_Stat 21000;
BA_ "GenSigTimeout_ORC" SG_ 1001 VC_VehCfg2_Stat 7000;
BA_ "FlexKomComment" SG_ 1002 VC_ADJ_PDL_PRSNT "Vehicle Configuration 3 Packet";
BA_ "FlexKomIsMotorola" SG_ 1002 VC_ADJ_PDL_PRSNT 1;
BA_ "FlexKomSID" SG_ 1002 VC_ADJ_PDL_PRSNT 888;
BA_ "FlexKomSigLaenge" SG_ 1002 VC_ADJ_PDL_PRSNT 64;
BA_ "FlexKomSigName" SG_ 1002 VC_ADJ_PDL_PRSNT "VehCfg3_Pkt";
BA_ "FlexKomSigStartPos" SG_ 1002 VC_ADJ_PDL_PRSNT 7;
BA_ "FlexKomSigStartValue" SG_ 1002 VC_ADJ_PDL_PRSNT "0370FF037FFF0000h";
BA_ "GenSigCycleTime" SG_ 1002 VC_ADJ_PDL_PRSNT 2000;
BA_ "GenSigSendType" SG_ 1002 VC_ADJ_PDL_PRSNT 5;
BA_ "GenSigSNA" SG_ 1002 VC_ADJ_PDL_PRSNT "0h";
BA_ "FlexKomComment" SG_ 1002 VC_AUTO_HL "Vehicle Configuration 3 Packet";
BA_ "FlexKomIsMotorola" SG_ 1002 VC_AUTO_HL 1;
BA_ "FlexKomSID" SG_ 1002 VC_AUTO_HL 888;
BA_ "FlexKomSigLaenge" SG_ 1002 VC_AUTO_HL 64;
BA_ "FlexKomSigName" SG_ 1002 VC_AUTO_HL "VehCfg3_Pkt";
BA_ "FlexKomSigStartPos" SG_ 1002 VC_AUTO_HL 7;
BA_ "FlexKomSigStartValue" SG_ 1002 VC_AUTO_HL "0370FF037FFF0000h";
BA_ "GenSigCycleTime" SG_ 1002 VC_AUTO_HL 2000;
BA_ "GenSigSendType" SG_ 1002 VC_AUTO_HL 5;
BA_ "GenSigSNA" SG_ 1002 VC_AUTO_HL "0h";
BA_ "GenSigTimeout_IC" SG_ 1002 VC_AUTO_HL 21000;
BA_ "FlexKomComment" SG_ 1002 VC_AutoParkPrsnt "Vehicle Configuration 3 Packet";
BA_ "FlexKomIsMotorola" SG_ 1002 VC_AutoParkPrsnt 1;
BA_ "FlexKomSID" SG_ 1002 VC_AutoParkPrsnt 888;
BA_ "FlexKomSigLaenge" SG_ 1002 VC_AutoParkPrsnt 64;
BA_ "FlexKomSigName" SG_ 1002 VC_AutoParkPrsnt "VehCfg3_Pkt";
BA_ "FlexKomSigStartPos" SG_ 1002 VC_AutoParkPrsnt 7;
BA_ "FlexKomSigStartValue" SG_ 1002 VC_AutoParkPrsnt "0370FF037FFF0000h";
BA_ "GenSigCycleTime" SG_ 1002 VC_AutoParkPrsnt 2000;
BA_ "GenSigSendType" SG_ 1002 VC_AutoParkPrsnt 5;
BA_ "GenSigSNA" SG_ 1002 VC_AutoParkPrsnt "0h";
BA_ "GenSigTimeout_IC" SG_ 1002 VC_AutoParkPrsnt 21000;
BA_ "FlexKomComment" SG_ 1002 VC_Base_TPM "Vehicle Configuration 3 Packet";
BA_ "FlexKomIsMotorola" SG_ 1002 VC_Base_TPM 1;
BA_ "FlexKomSID" SG_ 1002 VC_Base_TPM 888;
BA_ "FlexKomSigLaenge" SG_ 1002 VC_Base_TPM 64;
BA_ "FlexKomSigName" SG_ 1002 VC_Base_TPM "VehCfg3_Pkt";
BA_ "FlexKomSigStartPos" SG_ 1002 VC_Base_TPM 7;
BA_ "FlexKomSigStartValue" SG_ 1002 VC_Base_TPM "0370FF037FFF0000h";
BA_ "GenSigCycleTime" SG_ 1002 VC_Base_TPM 2000;
BA_ "GenSigSendType" SG_ 1002 VC_Base_TPM 5;
BA_ "GenSigSNA" SG_ 1002 VC_Base_TPM "0h";
BA_ "GenSigTimeout_IC" SG_ 1002 VC_Base_TPM 21000;
BA_ "GenSigTimeout_ORC" SG_ 1002 VC_Base_TPM 7000;
BA_ "FlexKomComment" SG_ 1002 VC_CMP_DISP "Vehicle Configuration 3 Packet";
BA_ "FlexKomIsMotorola" SG_ 1002 VC_CMP_DISP 1;
BA_ "FlexKomSID" SG_ 1002 VC_CMP_DISP 888;
BA_ "FlexKomSigLaenge" SG_ 1002 VC_CMP_DISP 64;
BA_ "FlexKomSigName" SG_ 1002 VC_CMP_DISP "VehCfg3_Pkt";
BA_ "FlexKomSigStartPos" SG_ 1002 VC_CMP_DISP 7;
BA_ "FlexKomSigStartValue" SG_ 1002 VC_CMP_DISP "0370FF037FFF0000h";
BA_ "GenSigCycleTime" SG_ 1002 VC_CMP_DISP 2000;
BA_ "GenSigSendType" SG_ 1002 VC_CMP_DISP 5;
BA_ "GenSigSNA" SG_ 1002 VC_CMP_DISP "0h";
BA_ "GenSigTimeout_IC" SG_ 1002 VC_CMP_DISP 21000;
BA_ "FlexKomComment" SG_ 1002 VC_CMS "Vehicle Configuration 3 Packet";
BA_ "FlexKomIsMotorola" SG_ 1002 VC_CMS 1;
BA_ "FlexKomSID" SG_ 1002 VC_CMS 888;
BA_ "FlexKomSigLaenge" SG_ 1002 VC_CMS 64;
BA_ "FlexKomSigName" SG_ 1002 VC_CMS "VehCfg3_Pkt";
BA_ "FlexKomSigStartPos" SG_ 1002 VC_CMS 7;
BA_ "FlexKomSigStartValue" SG_ 1002 VC_CMS "0370FF037FFF0000h";
BA_ "GenSigCycleTime" SG_ 1002 VC_CMS 2000;
BA_ "GenSigSendType" SG_ 1002 VC_CMS 5;
BA_ "GenSigSNA" SG_ 1002 VC_CMS "0h";
BA_ "GenSigTimeout_ORC" SG_ 1002 VC_CMS 7000;
BA_ "FlexKomComment" SG_ 1002 VC_ChassisType "Vehicle Configuration 3 Packet";
BA_ "FlexKomIsMotorola" SG_ 1002 VC_ChassisType 1;
BA_ "FlexKomSID" SG_ 1002 VC_ChassisType 888;
BA_ "FlexKomSigLaenge" SG_ 1002 VC_ChassisType 64;
BA_ "FlexKomSigName" SG_ 1002 VC_ChassisType "VehCfg3_Pkt";
BA_ "FlexKomSigStartPos" SG_ 1002 VC_ChassisType 7;
BA_ "FlexKomSigStartValue" SG_ 1002 VC_ChassisType "0370FF037FFF0000h";
BA_ "GenSigCycleTime" SG_ 1002 VC_ChassisType 2000;
BA_ "GenSigSendType" SG_ 1002 VC_ChassisType 5;
BA_ "GenSigSNA" SG_ 1002 VC_ChassisType "7Fh";
BA_ "GenSigStartValue" SG_ 1002 VC_ChassisType 127;
BA_ "GenSigTimeout_EPS" SG_ 1002 VC_ChassisType 21000;
BA_ "GenSigTimeout_ORC" SG_ 1002 VC_ChassisType 7000;
BA_ "GenSigTimeout_PTS" SG_ 1002 VC_ChassisType 21000;
BA_ "FlexKomComment" SG_ 1002 VC_DSBL_CLK_DISP "Vehicle Configuration 3 Packet";
BA_ "FlexKomIsMotorola" SG_ 1002 VC_DSBL_CLK_DISP 1;
BA_ "FlexKomSID" SG_ 1002 VC_DSBL_CLK_DISP 888;
BA_ "FlexKomSigLaenge" SG_ 1002 VC_DSBL_CLK_DISP 64;
BA_ "FlexKomSigName" SG_ 1002 VC_DSBL_CLK_DISP "VehCfg3_Pkt";
BA_ "FlexKomSigStartPos" SG_ 1002 VC_DSBL_CLK_DISP 7;
BA_ "FlexKomSigStartValue" SG_ 1002 VC_DSBL_CLK_DISP "0370FF037FFF0000h";
BA_ "GenSigCycleTime" SG_ 1002 VC_DSBL_CLK_DISP 2000;
BA_ "GenSigSendType" SG_ 1002 VC_DSBL_CLK_DISP 5;
BA_ "GenSigSNA" SG_ 1002 VC_DSBL_CLK_DISP "0h";
BA_ "GenSigTimeout_IC" SG_ 1002 VC_DSBL_CLK_DISP 21000;
BA_ "FlexKomComment" SG_ 1002 VC_DrAlrPrsnt "Vehicle Configuration 3 Packet";
BA_ "FlexKomIsMotorola" SG_ 1002 VC_DrAlrPrsnt 1;
BA_ "FlexKomSID" SG_ 1002 VC_DrAlrPrsnt 888;
BA_ "FlexKomSigLaenge" SG_ 1002 VC_DrAlrPrsnt 64;
BA_ "FlexKomSigName" SG_ 1002 VC_DrAlrPrsnt "VehCfg3_Pkt";
BA_ "FlexKomSigStartPos" SG_ 1002 VC_DrAlrPrsnt 7;
BA_ "FlexKomSigStartValue" SG_ 1002 VC_DrAlrPrsnt "0370FF037FFF0000h";
BA_ "GenSigCycleTime" SG_ 1002 VC_DrAlrPrsnt 2000;
BA_ "GenSigSendType" SG_ 1002 VC_DrAlrPrsnt 5;
BA_ "GenSigSNA" SG_ 1002 VC_DrAlrPrsnt "0h";
BA_ "GenSigTimeout_IC" SG_ 1002 VC_DrAlrPrsnt 21000;
BA_ "FlexKomComment" SG_ 1002 VC_DualFuelSens "Vehicle Configuration 3 Packet";
BA_ "FlexKomIsMotorola" SG_ 1002 VC_DualFuelSens 1;
BA_ "FlexKomSID" SG_ 1002 VC_DualFuelSens 888;
BA_ "FlexKomSigLaenge" SG_ 1002 VC_DualFuelSens 64;
BA_ "FlexKomSigName" SG_ 1002 VC_DualFuelSens "VehCfg3_Pkt";
BA_ "FlexKomSigStartPos" SG_ 1002 VC_DualFuelSens 7;
BA_ "FlexKomSigStartValue" SG_ 1002 VC_DualFuelSens "0370FF037FFF0000h";
BA_ "GenSigCycleTime" SG_ 1002 VC_DualFuelSens 2000;
BA_ "GenSigSendType" SG_ 1002 VC_DualFuelSens 5;
BA_ "GenSigSNA" SG_ 1002 VC_DualFuelSens "0h";
BA_ "GenSigTimeout_IC" SG_ 1002 VC_DualFuelSens 21000;
BA_ "FlexKomComment" SG_ 1002 VC_ELV_Prsnt "Vehicle Configuration 3 Packet";
BA_ "FlexKomIsMotorola" SG_ 1002 VC_ELV_Prsnt 1;
BA_ "FlexKomSID" SG_ 1002 VC_ELV_Prsnt 888;
BA_ "FlexKomSigLaenge" SG_ 1002 VC_ELV_Prsnt 64;
BA_ "FlexKomSigName" SG_ 1002 VC_ELV_Prsnt "VehCfg3_Pkt";
BA_ "FlexKomSigStartPos" SG_ 1002 VC_ELV_Prsnt 7;
BA_ "FlexKomSigStartValue" SG_ 1002 VC_ELV_Prsnt "0370FF037FFF0000h";
BA_ "GenSigCycleTime" SG_ 1002 VC_ELV_Prsnt 2000;
BA_ "GenSigSendType" SG_ 1002 VC_ELV_Prsnt 5;
BA_ "GenSigSNA" SG_ 1002 VC_ELV_Prsnt "0h";
BA_ "FlexKomComment" SG_ 1002 VC_ESCL_PRSNT "Vehicle Configuration 3 Packet";
BA_ "FlexKomIsMotorola" SG_ 1002 VC_ESCL_PRSNT 1;
BA_ "FlexKomSID" SG_ 1002 VC_ESCL_PRSNT 888;
BA_ "FlexKomSigLaenge" SG_ 1002 VC_ESCL_PRSNT 64;
BA_ "FlexKomSigName" SG_ 1002 VC_ESCL_PRSNT "VehCfg3_Pkt";
BA_ "FlexKomSigStartPos" SG_ 1002 VC_ESCL_PRSNT 7;
BA_ "FlexKomSigStartValue" SG_ 1002 VC_ESCL_PRSNT "0370FF037FFF0000h";
BA_ "GenSigCycleTime" SG_ 1002 VC_ESCL_PRSNT 2000;
BA_ "GenSigSendType" SG_ 1002 VC_ESCL_PRSNT 5;
BA_ "GenSigSNA" SG_ 1002 VC_ESCL_PRSNT "0h";
BA_ "FlexKomComment" SG_ 1002 VC_FCW "Vehicle Configuration 3 Packet";
BA_ "FlexKomIsMotorola" SG_ 1002 VC_FCW 1;
BA_ "FlexKomSID" SG_ 1002 VC_FCW 888;
BA_ "FlexKomSigLaenge" SG_ 1002 VC_FCW 64;
BA_ "FlexKomSigName" SG_ 1002 VC_FCW "VehCfg3_Pkt";
BA_ "FlexKomSigStartPos" SG_ 1002 VC_FCW 7;
BA_ "FlexKomSigStartValue" SG_ 1002 VC_FCW "0370FF037FFF0000h";
BA_ "GenSigCycleTime" SG_ 1002 VC_FCW 2000;
BA_ "GenSigSendType" SG_ 1002 VC_FCW 5;
BA_ "GenSigSNA" SG_ 1002 VC_FCW "0h";
BA_ "GenSigTimeout_ORC" SG_ 1002 VC_FCW 7000;
BA_ "FlexKomComment" SG_ 1002 VC_FOBIKsafeENBL "Vehicle Configuration 3 Packet";
BA_ "FlexKomIsMotorola" SG_ 1002 VC_FOBIKsafeENBL 1;
BA_ "FlexKomSID" SG_ 1002 VC_FOBIKsafeENBL 888;
BA_ "FlexKomSigLaenge" SG_ 1002 VC_FOBIKsafeENBL 64;
BA_ "FlexKomSigName" SG_ 1002 VC_FOBIKsafeENBL "VehCfg3_Pkt";
BA_ "FlexKomSigStartPos" SG_ 1002 VC_FOBIKsafeENBL 7;
BA_ "FlexKomSigStartValue" SG_ 1002 VC_FOBIKsafeENBL "0370FF037FFF0000h";
BA_ "GenSigCycleTime" SG_ 1002 VC_FOBIKsafeENBL 2000;
BA_ "GenSigSendType" SG_ 1002 VC_FOBIKsafeENBL 5;
BA_ "GenSigSNA" SG_ 1002 VC_FOBIKsafeENBL "1h";
BA_ "GenSigStartValue" SG_ 1002 VC_FOBIKsafeENBL 1;
BA_ "FlexKomComment" SG_ 1002 VC_FUEL_CAP "Vehicle Configuration 3 Packet";
BA_ "FlexKomIsMotorola" SG_ 1002 VC_FUEL_CAP 1;
BA_ "FlexKomSID" SG_ 1002 VC_FUEL_CAP 888;
BA_ "FlexKomSigLaenge" SG_ 1002 VC_FUEL_CAP 64;
BA_ "FlexKomSigName" SG_ 1002 VC_FUEL_CAP "VehCfg3_Pkt";
BA_ "FlexKomSigStartPos" SG_ 1002 VC_FUEL_CAP 7;
BA_ "FlexKomSigStartValue" SG_ 1002 VC_FUEL_CAP "0370FF037FFF0000h";
BA_ "GenSigCycleTime" SG_ 1002 VC_FUEL_CAP 2000;
BA_ "GenSigSendType" SG_ 1002 VC_FUEL_CAP 5;
BA_ "GenSigSNA" SG_ 1002 VC_FUEL_CAP "FFh";
BA_ "GenSigStartValue" SG_ 1002 VC_FUEL_CAP 255;
BA_ "GenSigTimeout_IC" SG_ 1002 VC_FUEL_CAP 21000;
BA_ "FlexKomComment" SG_ 1002 VC_HID_HL "Vehicle Configuration 3 Packet";
BA_ "FlexKomIsMotorola" SG_ 1002 VC_HID_HL 1;
BA_ "FlexKomSID" SG_ 1002 VC_HID_HL 888;
BA_ "FlexKomSigLaenge" SG_ 1002 VC_HID_HL 64;
BA_ "FlexKomSigName" SG_ 1002 VC_HID_HL "VehCfg3_Pkt";
BA_ "FlexKomSigStartPos" SG_ 1002 VC_HID_HL 7;
BA_ "FlexKomSigStartValue" SG_ 1002 VC_HID_HL "0370FF037FFF0000h";
BA_ "GenSigCycleTime" SG_ 1002 VC_HID_HL 2000;
BA_ "GenSigSendType" SG_ 1002 VC_HID_HL 5;
BA_ "GenSigSNA" SG_ 1002 VC_HID_HL "0h";
BA_ "FlexKomComment" SG_ 1002 VC_HVAC_Config "Vehicle Configuration 3 Packet";
BA_ "FlexKomIsMotorola" SG_ 1002 VC_HVAC_Config 1;
BA_ "FlexKomSID" SG_ 1002 VC_HVAC_Config 888;
BA_ "FlexKomSigLaenge" SG_ 1002 VC_HVAC_Config 64;
BA_ "FlexKomSigName" SG_ 1002 VC_HVAC_Config "VehCfg3_Pkt";
BA_ "FlexKomSigStartPos" SG_ 1002 VC_HVAC_Config 7;
BA_ "FlexKomSigStartValue" SG_ 1002 VC_HVAC_Config "0370FF037FFF0000h";
BA_ "GenSigCycleTime" SG_ 1002 VC_HVAC_Config 2000;
BA_ "GenSigSendType" SG_ 1002 VC_HVAC_Config 5;
BA_ "GenSigSNA" SG_ 1002 VC_HVAC_Config "Fh";
BA_ "GenSigStartValue" SG_ 1002 VC_HVAC_Config 15;
BA_ "GenSigTimeout_IC" SG_ 1002 VC_HVAC_Config 21000;
BA_ "FlexKomComment" SG_ 1002 VC_IntEC_MIRR "Vehicle Configuration 3 Packet";
BA_ "FlexKomIsMotorola" SG_ 1002 VC_IntEC_MIRR 1;
BA_ "FlexKomSID" SG_ 1002 VC_IntEC_MIRR 888;
BA_ "FlexKomSigLaenge" SG_ 1002 VC_IntEC_MIRR 64;
BA_ "FlexKomSigName" SG_ 1002 VC_IntEC_MIRR "VehCfg3_Pkt";
BA_ "FlexKomSigStartPos" SG_ 1002 VC_IntEC_MIRR 7;
BA_ "FlexKomSigStartValue" SG_ 1002 VC_IntEC_MIRR "0370FF037FFF0000h";
BA_ "GenSigCycleTime" SG_ 1002 VC_IntEC_MIRR 2000;
BA_ "GenSigSendType" SG_ 1002 VC_IntEC_MIRR 5;
BA_ "GenSigSNA" SG_ 1002 VC_IntEC_MIRR "0h";
BA_ "FlexKomComment" SG_ 1002 VC_KG_Prsnt "Vehicle Configuration 3 Packet";
BA_ "FlexKomIsMotorola" SG_ 1002 VC_KG_Prsnt 1;
BA_ "FlexKomSID" SG_ 1002 VC_KG_Prsnt 888;
BA_ "FlexKomSigLaenge" SG_ 1002 VC_KG_Prsnt 64;
BA_ "FlexKomSigName" SG_ 1002 VC_KG_Prsnt "VehCfg3_Pkt";
BA_ "FlexKomSigStartPos" SG_ 1002 VC_KG_Prsnt 7;
BA_ "FlexKomSigStartValue" SG_ 1002 VC_KG_Prsnt "0370FF037FFF0000h";
BA_ "GenSigCycleTime" SG_ 1002 VC_KG_Prsnt 2000;
BA_ "GenSigSendType" SG_ 1002 VC_KG_Prsnt 5;
BA_ "GenSigSNA" SG_ 1002 VC_KG_Prsnt "0h";
BA_ "GenSigTimeout_IC" SG_ 1002 VC_KG_Prsnt 21000;
BA_ "FlexKomComment" SG_ 1002 VC_Liftgate_Trunk "Vehicle Configuration 3 Packet";
BA_ "FlexKomIsMotorola" SG_ 1002 VC_Liftgate_Trunk 1;
BA_ "FlexKomSID" SG_ 1002 VC_Liftgate_Trunk 888;
BA_ "FlexKomSigLaenge" SG_ 1002 VC_Liftgate_Trunk 64;
BA_ "FlexKomSigName" SG_ 1002 VC_Liftgate_Trunk "VehCfg3_Pkt";
BA_ "FlexKomSigStartPos" SG_ 1002 VC_Liftgate_Trunk 7;
BA_ "FlexKomSigStartValue" SG_ 1002 VC_Liftgate_Trunk "0370FF037FFF0000h";
BA_ "GenSigCycleTime" SG_ 1002 VC_Liftgate_Trunk 2000;
BA_ "GenSigSendType" SG_ 1002 VC_Liftgate_Trunk 5;
BA_ "GenSigSNA" SG_ 1002 VC_Liftgate_Trunk "3h";
BA_ "GenSigTimeout_IC" SG_ 1002 VC_Liftgate_Trunk 21000;
BA_ "FlexKomComment" SG_ 1002 VC_PDDL_PRSNT "Vehicle Configuration 3 Packet";
BA_ "FlexKomIsMotorola" SG_ 1002 VC_PDDL_PRSNT 1;
BA_ "FlexKomSID" SG_ 1002 VC_PDDL_PRSNT 888;
BA_ "FlexKomSigLaenge" SG_ 1002 VC_PDDL_PRSNT 64;
BA_ "FlexKomSigName" SG_ 1002 VC_PDDL_PRSNT "VehCfg3_Pkt";
BA_ "FlexKomSigStartPos" SG_ 1002 VC_PDDL_PRSNT 7;
BA_ "FlexKomSigStartValue" SG_ 1002 VC_PDDL_PRSNT "0370FF037FFF0000h";
BA_ "GenSigCycleTime" SG_ 1002 VC_PDDL_PRSNT 2000;
BA_ "GenSigSendType" SG_ 1002 VC_PDDL_PRSNT 5;
BA_ "GenSigSNA" SG_ 1002 VC_PDDL_PRSNT "0h";
BA_ "GenSigTimeout_IC" SG_ 1002 VC_PDDL_PRSNT 21000;
BA_ "FlexKomComment" SG_ 1002 VC_PE_Prsnt "Vehicle Configuration 3 Packet";
BA_ "FlexKomIsMotorola" SG_ 1002 VC_PE_Prsnt 1;
BA_ "FlexKomSID" SG_ 1002 VC_PE_Prsnt 888;
BA_ "FlexKomSigLaenge" SG_ 1002 VC_PE_Prsnt 64;
BA_ "FlexKomSigName" SG_ 1002 VC_PE_Prsnt "VehCfg3_Pkt";
BA_ "FlexKomSigStartPos" SG_ 1002 VC_PE_Prsnt 7;
BA_ "FlexKomSigStartValue" SG_ 1002 VC_PE_Prsnt "0370FF037FFF0000h";
BA_ "GenSigCycleTime" SG_ 1002 VC_PE_Prsnt 2000;
BA_ "GenSigSendType" SG_ 1002 VC_PE_Prsnt 5;
BA_ "GenSigSNA" SG_ 1002 VC_PE_Prsnt "0h";
BA_ "GenSigTimeout_IC" SG_ 1002 VC_PE_Prsnt 21000;
BA_ "FlexKomComment" SG_ 1002 VC_POLICE "Vehicle Configuration 3 Packet";
BA_ "FlexKomIsMotorola" SG_ 1002 VC_POLICE 1;
BA_ "FlexKomSID" SG_ 1002 VC_POLICE 888;
BA_ "FlexKomSigLaenge" SG_ 1002 VC_POLICE 64;
BA_ "FlexKomSigName" SG_ 1002 VC_POLICE "VehCfg3_Pkt";
BA_ "FlexKomSigStartPos" SG_ 1002 VC_POLICE 7;
BA_ "FlexKomSigStartValue" SG_ 1002 VC_POLICE "0370FF037FFF0000h";
BA_ "GenSigCycleTime" SG_ 1002 VC_POLICE 2000;
BA_ "GenSigSendType" SG_ 1002 VC_POLICE 5;
BA_ "GenSigSNA" SG_ 1002 VC_POLICE "0h";
BA_ "GenSigTimeout_IC" SG_ 1002 VC_POLICE 21000;
BA_ "GenSigTimeout_ORC" SG_ 1002 VC_POLICE 7000;
BA_ "FlexKomComment" SG_ 1002 VC_PWR_LFT_GT "Vehicle Configuration 3 Packet";
BA_ "FlexKomIsMotorola" SG_ 1002 VC_PWR_LFT_GT 1;
BA_ "FlexKomSID" SG_ 1002 VC_PWR_LFT_GT 888;
BA_ "FlexKomSigLaenge" SG_ 1002 VC_PWR_LFT_GT 64;
BA_ "FlexKomSigName" SG_ 1002 VC_PWR_LFT_GT "VehCfg3_Pkt";
BA_ "FlexKomSigStartPos" SG_ 1002 VC_PWR_LFT_GT 7;
BA_ "FlexKomSigStartValue" SG_ 1002 VC_PWR_LFT_GT "0370FF037FFF0000h";
BA_ "GenSigCycleTime" SG_ 1002 VC_PWR_LFT_GT 2000;
BA_ "GenSigSendType" SG_ 1002 VC_PWR_LFT_GT 5;
BA_ "GenSigSNA" SG_ 1002 VC_PWR_LFT_GT "0h";
BA_ "FlexKomComment" SG_ 1002 VC_PWR_LT_SLDR "Vehicle Configuration 3 Packet";
BA_ "FlexKomIsMotorola" SG_ 1002 VC_PWR_LT_SLDR 1;
BA_ "FlexKomSID" SG_ 1002 VC_PWR_LT_SLDR 888;
BA_ "FlexKomSigLaenge" SG_ 1002 VC_PWR_LT_SLDR 64;
BA_ "FlexKomSigName" SG_ 1002 VC_PWR_LT_SLDR "VehCfg3_Pkt";
BA_ "FlexKomSigStartPos" SG_ 1002 VC_PWR_LT_SLDR 7;
BA_ "FlexKomSigStartValue" SG_ 1002 VC_PWR_LT_SLDR "0370FF037FFF0000h";
BA_ "GenSigCycleTime" SG_ 1002 VC_PWR_LT_SLDR 2000;
BA_ "GenSigSendType" SG_ 1002 VC_PWR_LT_SLDR 5;
BA_ "GenSigSNA" SG_ 1002 VC_PWR_LT_SLDR "0h";
BA_ "FlexKomComment" SG_ 1002 VC_PWR_RT_SLDR "Vehicle Configuration 3 Packet";
BA_ "FlexKomIsMotorola" SG_ 1002 VC_PWR_RT_SLDR 1;
BA_ "FlexKomSID" SG_ 1002 VC_PWR_RT_SLDR 888;
BA_ "FlexKomSigLaenge" SG_ 1002 VC_PWR_RT_SLDR 64;
BA_ "FlexKomSigName" SG_ 1002 VC_PWR_RT_SLDR "VehCfg3_Pkt";
BA_ "FlexKomSigStartPos" SG_ 1002 VC_PWR_RT_SLDR 7;
BA_ "FlexKomSigStartValue" SG_ 1002 VC_PWR_RT_SLDR "0370FF037FFF0000h";
BA_ "GenSigCycleTime" SG_ 1002 VC_PWR_RT_SLDR 2000;
BA_ "GenSigSendType" SG_ 1002 VC_PWR_RT_SLDR 5;
BA_ "GenSigSNA" SG_ 1002 VC_PWR_RT_SLDR "0h";
BA_ "FlexKomComment" SG_ 1002 VC_Prem_TPM "Vehicle Configuration 3 Packet";
BA_ "FlexKomIsMotorola" SG_ 1002 VC_Prem_TPM 1;
BA_ "FlexKomSID" SG_ 1002 VC_Prem_TPM 888;
BA_ "FlexKomSigLaenge" SG_ 1002 VC_Prem_TPM 64;
BA_ "FlexKomSigName" SG_ 1002 VC_Prem_TPM "VehCfg3_Pkt";
BA_ "FlexKomSigStartPos" SG_ 1002 VC_Prem_TPM 7;
BA_ "FlexKomSigStartValue" SG_ 1002 VC_Prem_TPM "0370FF037FFF0000h";
BA_ "GenSigCycleTime" SG_ 1002 VC_Prem_TPM 2000;
BA_ "GenSigSendType" SG_ 1002 VC_Prem_TPM 5;
BA_ "GenSigSNA" SG_ 1002 VC_Prem_TPM "0h";
BA_ "GenSigTimeout_IC" SG_ 1002 VC_Prem_TPM 21000;
BA_ "GenSigTimeout_ORC" SG_ 1002 VC_Prem_TPM 7000;
BA_ "FlexKomComment" SG_ 1002 VC_RKE_PRSNT "Vehicle Configuration 3 Packet";
BA_ "FlexKomIsMotorola" SG_ 1002 VC_RKE_PRSNT 1;
BA_ "FlexKomSID" SG_ 1002 VC_RKE_PRSNT 888;
BA_ "FlexKomSigLaenge" SG_ 1002 VC_RKE_PRSNT 64;
BA_ "FlexKomSigName" SG_ 1002 VC_RKE_PRSNT "VehCfg3_Pkt";
BA_ "FlexKomSigStartPos" SG_ 1002 VC_RKE_PRSNT 7;
BA_ "FlexKomSigStartValue" SG_ 1002 VC_RKE_PRSNT "0370FF037FFF0000h";
BA_ "GenSigCycleTime" SG_ 1002 VC_RKE_PRSNT 2000;
BA_ "GenSigSendType" SG_ 1002 VC_RKE_PRSNT 5;
BA_ "GenSigSNA" SG_ 1002 VC_RKE_PRSNT "0h";
BA_ "GenSigTimeout_IC" SG_ 1002 VC_RKE_PRSNT 21000;
BA_ "FlexKomComment" SG_ 1002 VC_SPORT_PRSNT "Vehicle Configuration 3 Packet";
BA_ "FlexKomIsMotorola" SG_ 1002 VC_SPORT_PRSNT 1;
BA_ "FlexKomSID" SG_ 1002 VC_SPORT_PRSNT 888;
BA_ "FlexKomSigLaenge" SG_ 1002 VC_SPORT_PRSNT 64;
BA_ "FlexKomSigName" SG_ 1002 VC_SPORT_PRSNT "VehCfg3_Pkt";
BA_ "FlexKomSigStartPos" SG_ 1002 VC_SPORT_PRSNT 7;
BA_ "FlexKomSigStartValue" SG_ 1002 VC_SPORT_PRSNT "0370FF037FFF0000h";
BA_ "GenSigCycleTime" SG_ 1002 VC_SPORT_PRSNT 2000;
BA_ "GenSigSendType" SG_ 1002 VC_SPORT_PRSNT 5;
BA_ "GenSigSNA" SG_ 1002 VC_SPORT_PRSNT "0h";
BA_ "GenSigTimeout_IC" SG_ 1002 VC_SPORT_PRSNT 21000;
BA_ "FlexKomComment" SG_ 1002 VC_SRT_PRSNT "Vehicle Configuration 3 Packet";
BA_ "FlexKomIsMotorola" SG_ 1002 VC_SRT_PRSNT 1;
BA_ "FlexKomSID" SG_ 1002 VC_SRT_PRSNT 888;
BA_ "FlexKomSigLaenge" SG_ 1002 VC_SRT_PRSNT 64;
BA_ "FlexKomSigName" SG_ 1002 VC_SRT_PRSNT "VehCfg3_Pkt";
BA_ "FlexKomSigStartPos" SG_ 1002 VC_SRT_PRSNT 7;
BA_ "FlexKomSigStartValue" SG_ 1002 VC_SRT_PRSNT "0370FF037FFF0000h";
BA_ "GenSigCycleTime" SG_ 1002 VC_SRT_PRSNT 2000;
BA_ "GenSigSendType" SG_ 1002 VC_SRT_PRSNT 5;
BA_ "GenSigSNA" SG_ 1002 VC_SRT_PRSNT "0h";
BA_ "GenSigTimeout_IC" SG_ 1002 VC_SRT_PRSNT 21000;
BA_ "GenSigTimeout_ORC" SG_ 1002 VC_SRT_PRSNT 7000;
BA_ "FlexKomComment" SG_ 1002 VC_SecLkPrsnt "Vehicle Configuration 3 Packet";
BA_ "FlexKomIsMotorola" SG_ 1002 VC_SecLkPrsnt 1;
BA_ "FlexKomSID" SG_ 1002 VC_SecLkPrsnt 888;
BA_ "FlexKomSigLaenge" SG_ 1002 VC_SecLkPrsnt 64;
BA_ "FlexKomSigName" SG_ 1002 VC_SecLkPrsnt "VehCfg3_Pkt";
BA_ "FlexKomSigStartPos" SG_ 1002 VC_SecLkPrsnt 7;
BA_ "FlexKomSigStartValue" SG_ 1002 VC_SecLkPrsnt "0370FF037FFF0000h";
BA_ "GenSigCycleTime" SG_ 1002 VC_SecLkPrsnt 2000;
BA_ "GenSigSendType" SG_ 1002 VC_SecLkPrsnt 5;
BA_ "GenSigSNA" SG_ 1002 VC_SecLkPrsnt "0h";
BA_ "FlexKomComment" SG_ 1002 VC_SunShade_Present "Vehicle Configuration 3 Packet";
BA_ "FlexKomIsMotorola" SG_ 1002 VC_SunShade_Present 1;
BA_ "FlexKomSID" SG_ 1002 VC_SunShade_Present 888;
BA_ "FlexKomSigLaenge" SG_ 1002 VC_SunShade_Present 64;
BA_ "FlexKomSigName" SG_ 1002 VC_SunShade_Present "VehCfg3_Pkt";
BA_ "FlexKomSigStartPos" SG_ 1002 VC_SunShade_Present 7;
BA_ "FlexKomSigStartValue" SG_ 1002 VC_SunShade_Present "0370FF037FFF0000h";
BA_ "GenSigCycleTime" SG_ 1002 VC_SunShade_Present 2000;
BA_ "GenSigSendType" SG_ 1002 VC_SunShade_Present 5;
BA_ "GenSigSNA" SG_ 1002 VC_SunShade_Present "0h";
BA_ "FlexKomComment" SG_ 1002 VC_TEMP_DISP "Vehicle Configuration 3 Packet";
BA_ "FlexKomIsMotorola" SG_ 1002 VC_TEMP_DISP 1;
BA_ "FlexKomSID" SG_ 1002 VC_TEMP_DISP 888;
BA_ "FlexKomSigLaenge" SG_ 1002 VC_TEMP_DISP 64;
BA_ "FlexKomSigName" SG_ 1002 VC_TEMP_DISP "VehCfg3_Pkt";
BA_ "FlexKomSigStartPos" SG_ 1002 VC_TEMP_DISP 7;
BA_ "FlexKomSigStartValue" SG_ 1002 VC_TEMP_DISP "0370FF037FFF0000h";
BA_ "GenSigCycleTime" SG_ 1002 VC_TEMP_DISP 2000;
BA_ "GenSigSendType" SG_ 1002 VC_TEMP_DISP 5;
BA_ "GenSigSNA" SG_ 1002 VC_TEMP_DISP "0h";
BA_ "GenSigTimeout_IC" SG_ 1002 VC_TEMP_DISP 21000;
BA_ "FlexKomComment" SG_ 1002 VC_TcaseTyp "Vehicle Configuration 3 Packet";
BA_ "FlexKomIsMotorola" SG_ 1002 VC_TcaseTyp 1;
BA_ "FlexKomSID" SG_ 1002 VC_TcaseTyp 888;
BA_ "FlexKomSigLaenge" SG_ 1002 VC_TcaseTyp 64;
BA_ "FlexKomSigName" SG_ 1002 VC_TcaseTyp "VehCfg3_Pkt";
BA_ "FlexKomSigStartPos" SG_ 1002 VC_TcaseTyp 7;
BA_ "FlexKomSigStartValue" SG_ 1002 VC_TcaseTyp "0370FF037FFF0000h";
BA_ "GenSigCycleTime" SG_ 1002 VC_TcaseTyp 2000;
BA_ "GenSigSendType" SG_ 1002 VC_TcaseTyp 5;
BA_ "GenSigSNA" SG_ 1002 VC_TcaseTyp "0h";
BA_ "FlexKomComment" SG_ 1002 VC_VEH_BRAND "Vehicle Configuration 3 Packet";
BA_ "FlexKomIsMotorola" SG_ 1002 VC_VEH_BRAND 1;
BA_ "FlexKomSID" SG_ 1002 VC_VEH_BRAND 888;
BA_ "FlexKomSigLaenge" SG_ 1002 VC_VEH_BRAND 64;
BA_ "FlexKomSigName" SG_ 1002 VC_VEH_BRAND "VehCfg3_Pkt";
BA_ "FlexKomSigStartPos" SG_ 1002 VC_VEH_BRAND 7;
BA_ "FlexKomSigStartValue" SG_ 1002 VC_VEH_BRAND "0370FF037FFF0000h";
BA_ "GenSigCycleTime" SG_ 1002 VC_VEH_BRAND 2000;
BA_ "GenSigSendType" SG_ 1002 VC_VEH_BRAND 5;
BA_ "GenSigSNA" SG_ 1002 VC_VEH_BRAND "Fh";
BA_ "GenSigStartValue" SG_ 1002 VC_VEH_BRAND 15;
BA_ "GenSigTimeout_IC" SG_ 1002 VC_VEH_BRAND 21000;
BA_ "FlexKomComment" SG_ 1002 VC_VehCfg3_Stat "Vehicle Configuration 3 Packet";
BA_ "FlexKomIsMotorola" SG_ 1002 VC_VehCfg3_Stat 1;
BA_ "FlexKomSID" SG_ 1002 VC_VehCfg3_Stat 888;
BA_ "FlexKomSigLaenge" SG_ 1002 VC_VehCfg3_Stat 64;
BA_ "FlexKomSigName" SG_ 1002 VC_VehCfg3_Stat "VehCfg3_Pkt";
BA_ "FlexKomSigStartPos" SG_ 1002 VC_VehCfg3_Stat 7;
BA_ "FlexKomSigStartValue" SG_ 1002 VC_VehCfg3_Stat "0370FF037FFF0000h";
BA_ "GenSigCycleTime" SG_ 1002 VC_VehCfg3_Stat 2000;
BA_ "GenSigSendType" SG_ 1002 VC_VehCfg3_Stat 5;
BA_ "GenSigSNA" SG_ 1002 VC_VehCfg3_Stat "3h";
BA_ "GenSigStartValue" SG_ 1002 VC_VehCfg3_Stat 3;
BA_ "GenSigTimeout_EPS" SG_ 1002 VC_VehCfg3_Stat 21000;
BA_ "GenSigTimeout_IC" SG_ 1002 VC_VehCfg3_Stat 21000;
BA_ "GenSigTimeout_ORC" SG_ 1002 VC_VehCfg3_Stat 7000;
BA_ "FlexKomComment" SG_ 1002 VC_WHL_BASE "Vehicle Configuration 3 Packet";
BA_ "FlexKomIsMotorola" SG_ 1002 VC_WHL_BASE 1;
BA_ "FlexKomSID" SG_ 1002 VC_WHL_BASE 888;
BA_ "FlexKomSigLaenge" SG_ 1002 VC_WHL_BASE 64;
BA_ "FlexKomSigName" SG_ 1002 VC_WHL_BASE "VehCfg3_Pkt";
BA_ "FlexKomSigStartPos" SG_ 1002 VC_WHL_BASE 7;
BA_ "FlexKomSigStartValue" SG_ 1002 VC_WHL_BASE "0370FF037FFF0000h";
BA_ "GenSigCycleTime" SG_ 1002 VC_WHL_BASE 2000;
BA_ "GenSigSendType" SG_ 1002 VC_WHL_BASE 5;
BA_ "GenSigSNA" SG_ 1002 VC_WHL_BASE "3h";
BA_ "GenSigStartValue" SG_ 1002 VC_WHL_BASE 3;
BA_ "GenSigTimeout_ORC" SG_ 1002 VC_WHL_BASE 7000;
BA_ "FlexKomComment" SG_ 1002 VC_WIN_EXPR_FEAT "Vehicle Configuration 3 Packet";
BA_ "FlexKomIsMotorola" SG_ 1002 VC_WIN_EXPR_FEAT 1;
BA_ "FlexKomSID" SG_ 1002 VC_WIN_EXPR_FEAT 888;
BA_ "FlexKomSigLaenge" SG_ 1002 VC_WIN_EXPR_FEAT 64;
BA_ "FlexKomSigName" SG_ 1002 VC_WIN_EXPR_FEAT "VehCfg3_Pkt";
BA_ "FlexKomSigStartPos" SG_ 1002 VC_WIN_EXPR_FEAT 7;
BA_ "FlexKomSigStartValue" SG_ 1002 VC_WIN_EXPR_FEAT "0370FF037FFF0000h";
BA_ "GenSigCycleTime" SG_ 1002 VC_WIN_EXPR_FEAT 2000;
BA_ "GenSigSendType" SG_ 1002 VC_WIN_EXPR_FEAT 5;
BA_ "GenSigSNA" SG_ 1002 VC_WIN_EXPR_FEAT "3h";
BA_ "GenSigStartValue" SG_ 1002 VC_WIN_EXPR_FEAT 3;
BA_ "FlexKomComment" SG_ 1003 VC_AXLE_RATIO "Vehicle Configuration 4 Packet";
BA_ "FlexKomIsMotorola" SG_ 1003 VC_AXLE_RATIO 1;
BA_ "FlexKomSID" SG_ 1003 VC_AXLE_RATIO 1035;
BA_ "FlexKomSigLaenge" SG_ 1003 VC_AXLE_RATIO 64;
BA_ "FlexKomSigName" SG_ 1003 VC_AXLE_RATIO "VehCfg4_Pkt";
BA_ "FlexKomSigStartPos" SG_ 1003 VC_AXLE_RATIO 7;
BA_ "FlexKomSigStartValue" SG_ 1003 VC_AXLE_RATIO "FFFFFFFFFFFFFFFFh";
BA_ "GenSigCycleTime" SG_ 1003 VC_AXLE_RATIO 1000;
BA_ "GenSigSendType" SG_ 1003 VC_AXLE_RATIO 5;
BA_ "GenSigSNA" SG_ 1003 VC_AXLE_RATIO "FFFFh";
BA_ "GenSigStartValue" SG_ 1003 VC_AXLE_RATIO 65535;
BA_ "FlexKomComment" SG_ 1003 VC_TCASE_HI_RATIO "Vehicle Configuration 4 Packet";
BA_ "FlexKomIsMotorola" SG_ 1003 VC_TCASE_HI_RATIO 1;
BA_ "FlexKomSID" SG_ 1003 VC_TCASE_HI_RATIO 1035;
BA_ "FlexKomSigLaenge" SG_ 1003 VC_TCASE_HI_RATIO 64;
BA_ "FlexKomSigName" SG_ 1003 VC_TCASE_HI_RATIO "VehCfg4_Pkt";
BA_ "FlexKomSigStartPos" SG_ 1003 VC_TCASE_HI_RATIO 7;
BA_ "FlexKomSigStartValue" SG_ 1003 VC_TCASE_HI_RATIO "FFFFFFFFFFFFFFFFh";
BA_ "GenSigCycleTime" SG_ 1003 VC_TCASE_HI_RATIO 1000;
BA_ "GenSigSendType" SG_ 1003 VC_TCASE_HI_RATIO 5;
BA_ "GenSigSNA" SG_ 1003 VC_TCASE_HI_RATIO "3FFFh";
BA_ "GenSigStartValue" SG_ 1003 VC_TCASE_HI_RATIO 16383;
BA_ "FlexKomComment" SG_ 1003 VC_TCASE_LO_RATIO "Vehicle Configuration 4 Packet";
BA_ "FlexKomIsMotorola" SG_ 1003 VC_TCASE_LO_RATIO 1;
BA_ "FlexKomSID" SG_ 1003 VC_TCASE_LO_RATIO 1035;
BA_ "FlexKomSigLaenge" SG_ 1003 VC_TCASE_LO_RATIO 64;
BA_ "FlexKomSigName" SG_ 1003 VC_TCASE_LO_RATIO "VehCfg4_Pkt";
BA_ "FlexKomSigStartPos" SG_ 1003 VC_TCASE_LO_RATIO 7;
BA_ "FlexKomSigStartValue" SG_ 1003 VC_TCASE_LO_RATIO "FFFFFFFFFFFFFFFFh";
BA_ "GenSigCycleTime" SG_ 1003 VC_TCASE_LO_RATIO 1000;
BA_ "GenSigSendType" SG_ 1003 VC_TCASE_LO_RATIO 5;
BA_ "GenSigSNA" SG_ 1003 VC_TCASE_LO_RATIO "FFFFh";
BA_ "GenSigStartValue" SG_ 1003 VC_TCASE_LO_RATIO 65535;
BA_ "FlexKomComment" SG_ 1003 VC_TIRE_CIRCUMF "Vehicle Configuration 4 Packet";
BA_ "FlexKomIsMotorola" SG_ 1003 VC_TIRE_CIRCUMF 1;
BA_ "FlexKomSID" SG_ 1003 VC_TIRE_CIRCUMF 1035;
BA_ "FlexKomSigLaenge" SG_ 1003 VC_TIRE_CIRCUMF 64;
BA_ "FlexKomSigName" SG_ 1003 VC_TIRE_CIRCUMF "VehCfg4_Pkt";
BA_ "FlexKomSigStartPos" SG_ 1003 VC_TIRE_CIRCUMF 7;
BA_ "FlexKomSigStartValue" SG_ 1003 VC_TIRE_CIRCUMF "FFFFFFFFFFFFFFFFh";
BA_ "GenSigCycleTime" SG_ 1003 VC_TIRE_CIRCUMF 1000;
BA_ "GenSigSendType" SG_ 1003 VC_TIRE_CIRCUMF 5;
BA_ "GenSigSNA" SG_ 1003 VC_TIRE_CIRCUMF "FFFFh";
BA_ "GenSigStartValue" SG_ 1003 VC_TIRE_CIRCUMF 65535;
BA_ "GenSigTimeout_ORC" SG_ 1003 VC_TIRE_CIRCUMF 3500;
BA_ "RID" SG_ 1003 VC_TIRE_CIRCUMF "9789";
BA_ "FlexKomComment" SG_ 1003 VC_VehCfg4_Stat "Vehicle Configuration 4 Packet";
BA_ "FlexKomIsMotorola" SG_ 1003 VC_VehCfg4_Stat 1;
BA_ "FlexKomSID" SG_ 1003 VC_VehCfg4_Stat 1035;
BA_ "FlexKomSigLaenge" SG_ 1003 VC_VehCfg4_Stat 64;
BA_ "FlexKomSigName" SG_ 1003 VC_VehCfg4_Stat "VehCfg4_Pkt";
BA_ "FlexKomSigStartPos" SG_ 1003 VC_VehCfg4_Stat 7;
BA_ "FlexKomSigStartValue" SG_ 1003 VC_VehCfg4_Stat "FFFFFFFFFFFFFFFFh";
BA_ "GenSigCycleTime" SG_ 1003 VC_VehCfg4_Stat 1000;
BA_ "GenSigSendType" SG_ 1003 VC_VehCfg4_Stat 5;
BA_ "GenSigSNA" SG_ 1003 VC_VehCfg4_Stat "3h";
BA_ "GenSigStartValue" SG_ 1003 VC_VehCfg4_Stat 3;
BA_ "GenSigTimeout_ORC" SG_ 1003 VC_VehCfg4_Stat 3500;
BA_ "GenSigTimeout_RF_HUB" SG_ 1003 VC_VehCfg4_Stat 10500;
BA_ "FlexKomComment" SG_ 1098 VC_AmbLtgPrsnt "Vehicle Configuration 5 Packet";
BA_ "FlexKomIsMotorola" SG_ 1098 VC_AmbLtgPrsnt 1;
BA_ "FlexKomSID" SG_ 1098 VC_AmbLtgPrsnt 1198;
BA_ "FlexKomSigLaenge" SG_ 1098 VC_AmbLtgPrsnt 64;
BA_ "FlexKomSigName" SG_ 1098 VC_AmbLtgPrsnt "VehCfg5_Pkt";
BA_ "FlexKomSigStartPos" SG_ 1098 VC_AmbLtgPrsnt 7;
BA_ "FlexKomSigStartValue" SG_ 1098 VC_AmbLtgPrsnt "C3FFFFFFFFFFFF00h";
BA_ "GenSigCycleTime" SG_ 1098 VC_AmbLtgPrsnt 2000;
BA_ "GenSigSendType" SG_ 1098 VC_AmbLtgPrsnt 5;
BA_ "GenSigSNA" SG_ 1098 VC_AmbLtgPrsnt "0h";
BA_ "GenSigTimeout_IC" SG_ 1098 VC_AmbLtgPrsnt 21000;
BA_ "FlexKomComment" SG_ 1098 VC_AmbTempLct "Vehicle Configuration 5 Packet";
BA_ "FlexKomIsMotorola" SG_ 1098 VC_AmbTempLct 1;
BA_ "FlexKomSID" SG_ 1098 VC_AmbTempLct 1198;
BA_ "FlexKomSigLaenge" SG_ 1098 VC_AmbTempLct 64;
BA_ "FlexKomSigName" SG_ 1098 VC_AmbTempLct "VehCfg5_Pkt";
BA_ "FlexKomSigStartPos" SG_ 1098 VC_AmbTempLct 7;
BA_ "FlexKomSigStartValue" SG_ 1098 VC_AmbTempLct "C3FFFFFFFFFFFF00h";
BA_ "GenSigCycleTime" SG_ 1098 VC_AmbTempLct 2000;
BA_ "GenSigSendType" SG_ 1098 VC_AmbTempLct 5;
BA_ "GenSigSNA" SG_ 1098 VC_AmbTempLct "3h";
BA_ "GenSigStartValue" SG_ 1098 VC_AmbTempLct 3;
BA_ "FlexKomComment" SG_ 1098 VC_ChildDisp_Prsnt "Vehicle Configuration 5 Packet";
BA_ "FlexKomIsMotorola" SG_ 1098 VC_ChildDisp_Prsnt 1;
BA_ "FlexKomSID" SG_ 1098 VC_ChildDisp_Prsnt 1198;
BA_ "FlexKomSigLaenge" SG_ 1098 VC_ChildDisp_Prsnt 64;
BA_ "FlexKomSigName" SG_ 1098 VC_ChildDisp_Prsnt "VehCfg5_Pkt";
BA_ "FlexKomSigStartPos" SG_ 1098 VC_ChildDisp_Prsnt 7;
BA_ "FlexKomSigStartValue" SG_ 1098 VC_ChildDisp_Prsnt "C3FFFFFFFFFFFF00h";
BA_ "GenSigCycleTime" SG_ 1098 VC_ChildDisp_Prsnt 2000;
BA_ "GenSigSendType" SG_ 1098 VC_ChildDisp_Prsnt 5;
BA_ "GenSigSNA" SG_ 1098 VC_ChildDisp_Prsnt "0h";
BA_ "GenSigTimeout_IC" SG_ 1098 VC_ChildDisp_Prsnt 21000;
BA_ "GenSigTimeout_ORC" SG_ 1098 VC_ChildDisp_Prsnt 7000;
BA_ "FlexKomComment" SG_ 1098 VC_LUCI_PRSNT "Vehicle Configuration 5 Packet";
BA_ "FlexKomIsMotorola" SG_ 1098 VC_LUCI_PRSNT 1;
BA_ "FlexKomSID" SG_ 1098 VC_LUCI_PRSNT 1198;
BA_ "FlexKomSigLaenge" SG_ 1098 VC_LUCI_PRSNT 64;
BA_ "FlexKomSigName" SG_ 1098 VC_LUCI_PRSNT "VehCfg5_Pkt";
BA_ "FlexKomSigStartPos" SG_ 1098 VC_LUCI_PRSNT 7;
BA_ "FlexKomSigStartValue" SG_ 1098 VC_LUCI_PRSNT "C3FFFFFFFFFFFF00h";
BA_ "GenSigCycleTime" SG_ 1098 VC_LUCI_PRSNT 2000;
BA_ "GenSigSendType" SG_ 1098 VC_LUCI_PRSNT 5;
BA_ "GenSigSNA" SG_ 1098 VC_LUCI_PRSNT "0h";
BA_ "FlexKomComment" SG_ 1098 VC_NonReg_TPIS "Vehicle Configuration 5 Packet";
BA_ "FlexKomIsMotorola" SG_ 1098 VC_NonReg_TPIS 1;
BA_ "FlexKomSID" SG_ 1098 VC_NonReg_TPIS 1198;
BA_ "FlexKomSigLaenge" SG_ 1098 VC_NonReg_TPIS 64;
BA_ "FlexKomSigName" SG_ 1098 VC_NonReg_TPIS "VehCfg5_Pkt";
BA_ "FlexKomSigStartPos" SG_ 1098 VC_NonReg_TPIS 7;
BA_ "FlexKomSigStartValue" SG_ 1098 VC_NonReg_TPIS "C3FFFFFFFFFFFF00h";
BA_ "GenSigCycleTime" SG_ 1098 VC_NonReg_TPIS 2000;
BA_ "GenSigSendType" SG_ 1098 VC_NonReg_TPIS 5;
BA_ "GenSigSNA" SG_ 1098 VC_NonReg_TPIS "0h";
BA_ "GenSigTimeout_IC" SG_ 1098 VC_NonReg_TPIS 21000;
BA_ "FlexKomComment" SG_ 1098 VC_OffRoadPg "Vehicle Configuration 5 Packet";
BA_ "FlexKomIsMotorola" SG_ 1098 VC_OffRoadPg 1;
BA_ "FlexKomSID" SG_ 1098 VC_OffRoadPg 1198;
BA_ "FlexKomSigLaenge" SG_ 1098 VC_OffRoadPg 64;
BA_ "FlexKomSigName" SG_ 1098 VC_OffRoadPg "VehCfg5_Pkt";
BA_ "FlexKomSigStartPos" SG_ 1098 VC_OffRoadPg 7;
BA_ "FlexKomSigStartValue" SG_ 1098 VC_OffRoadPg "C3FFFFFFFFFFFF00h";
BA_ "GenSigCycleTime" SG_ 1098 VC_OffRoadPg 2000;
BA_ "GenSigSendType" SG_ 1098 VC_OffRoadPg 5;
BA_ "GenSigSNA" SG_ 1098 VC_OffRoadPg "0h";
BA_ "GenSigTimeout_IC" SG_ 1098 VC_OffRoadPg 21000;
BA_ "FlexKomComment" SG_ 1098 VC_PPPA_Prsnt "Vehicle Configuration 5 Packet";
BA_ "FlexKomIsMotorola" SG_ 1098 VC_PPPA_Prsnt 1;
BA_ "FlexKomSID" SG_ 1098 VC_PPPA_Prsnt 1198;
BA_ "FlexKomSigLaenge" SG_ 1098 VC_PPPA_Prsnt 64;
BA_ "FlexKomSigName" SG_ 1098 VC_PPPA_Prsnt "VehCfg5_Pkt";
BA_ "FlexKomSigStartPos" SG_ 1098 VC_PPPA_Prsnt 7;
BA_ "FlexKomSigStartValue" SG_ 1098 VC_PPPA_Prsnt "C3FFFFFFFFFFFF00h";
BA_ "GenSigCycleTime" SG_ 1098 VC_PPPA_Prsnt 2000;
BA_ "GenSigSendType" SG_ 1098 VC_PPPA_Prsnt 5;
BA_ "GenSigSNA" SG_ 1098 VC_PPPA_Prsnt "0h";
BA_ "GenSigTimeout_EPS" SG_ 1098 VC_PPPA_Prsnt 21000;
BA_ "GenSigTimeout_IC" SG_ 1098 VC_PPPA_Prsnt 21000;
BA_ "GenSigTimeout_PTS" SG_ 1098 VC_PPPA_Prsnt 21000;
BA_ "RID" SG_ 1098 VC_PPPA_Prsnt "9790";
BA_ "FlexKomComment" SG_ 1098 VC_ParkStopPrsnt "Vehicle Configuration 5 Packet";
BA_ "FlexKomIsMotorola" SG_ 1098 VC_ParkStopPrsnt 1;
BA_ "FlexKomSID" SG_ 1098 VC_ParkStopPrsnt 1198;
BA_ "FlexKomSigLaenge" SG_ 1098 VC_ParkStopPrsnt 64;
BA_ "FlexKomSigName" SG_ 1098 VC_ParkStopPrsnt "VehCfg5_Pkt";
BA_ "FlexKomSigStartPos" SG_ 1098 VC_ParkStopPrsnt 7;
BA_ "FlexKomSigStartValue" SG_ 1098 VC_ParkStopPrsnt "C3FFFFFFFFFFFF00h";
BA_ "GenSigCycleTime" SG_ 1098 VC_ParkStopPrsnt 2000;
BA_ "GenSigSendType" SG_ 1098 VC_ParkStopPrsnt 5;
BA_ "GenSigSNA" SG_ 1098 VC_ParkStopPrsnt "0h";
BA_ "GenSigTimeout_PTS" SG_ 1098 VC_ParkStopPrsnt 21000;
BA_ "FlexKomComment" SG_ 1098 VC_RR_DuallyPrsnt "Vehicle Configuration 5 Packet";
BA_ "FlexKomIsMotorola" SG_ 1098 VC_RR_DuallyPrsnt 1;
BA_ "FlexKomSID" SG_ 1098 VC_RR_DuallyPrsnt 1198;
BA_ "FlexKomSigLaenge" SG_ 1098 VC_RR_DuallyPrsnt 64;
BA_ "FlexKomSigName" SG_ 1098 VC_RR_DuallyPrsnt "VehCfg5_Pkt";
BA_ "FlexKomSigStartPos" SG_ 1098 VC_RR_DuallyPrsnt 7;
BA_ "FlexKomSigStartValue" SG_ 1098 VC_RR_DuallyPrsnt "C3FFFFFFFFFFFF00h";
BA_ "GenSigCycleTime" SG_ 1098 VC_RR_DuallyPrsnt 2000;
BA_ "GenSigSendType" SG_ 1098 VC_RR_DuallyPrsnt 5;
BA_ "GenSigSNA" SG_ 1098 VC_RR_DuallyPrsnt "0h";
BA_ "GenSigTimeout_IC" SG_ 1098 VC_RR_DuallyPrsnt 21000;
BA_ "FlexKomComment" SG_ 1098 VC_RearDoorLocks2DCM "Vehicle Configuration 5 Packet";
BA_ "FlexKomIsMotorola" SG_ 1098 VC_RearDoorLocks2DCM 1;
BA_ "FlexKomSID" SG_ 1098 VC_RearDoorLocks2DCM 1198;
BA_ "FlexKomSigLaenge" SG_ 1098 VC_RearDoorLocks2DCM 64;
BA_ "FlexKomSigName" SG_ 1098 VC_RearDoorLocks2DCM "VehCfg5_Pkt";
BA_ "FlexKomSigStartPos" SG_ 1098 VC_RearDoorLocks2DCM 7;
BA_ "FlexKomSigStartValue" SG_ 1098 VC_RearDoorLocks2DCM "C3FFFFFFFFFFFF00h";
BA_ "GenSigCycleTime" SG_ 1098 VC_RearDoorLocks2DCM 2000;
BA_ "GenSigSendType" SG_ 1098 VC_RearDoorLocks2DCM 5;
BA_ "GenSigSNA" SG_ 1098 VC_RearDoorLocks2DCM "0h";
BA_ "FlexKomComment" SG_ 1098 VC_SBR_Prsnt "Vehicle Configuration 5 Packet";
BA_ "FlexKomIsMotorola" SG_ 1098 VC_SBR_Prsnt 1;
BA_ "FlexKomSID" SG_ 1098 VC_SBR_Prsnt 1198;
BA_ "FlexKomSigLaenge" SG_ 1098 VC_SBR_Prsnt 64;
BA_ "FlexKomSigName" SG_ 1098 VC_SBR_Prsnt "VehCfg5_Pkt";
BA_ "FlexKomSigStartPos" SG_ 1098 VC_SBR_Prsnt 7;
BA_ "FlexKomSigStartValue" SG_ 1098 VC_SBR_Prsnt "C3FFFFFFFFFFFF00h";
BA_ "GenSigCycleTime" SG_ 1098 VC_SBR_Prsnt 2000;
BA_ "GenSigSendType" SG_ 1098 VC_SBR_Prsnt 5;
BA_ "GenSigSNA" SG_ 1098 VC_SBR_Prsnt "0h";
BA_ "GenSigTimeout_IC" SG_ 1098 VC_SBR_Prsnt 21000;
BA_ "GenSigTimeout_ORC" SG_ 1098 VC_SBR_Prsnt 7000;
BA_ "FlexKomComment" SG_ 1098 VC_SpdLmt_PRSNT "Vehicle Configuration 5 Packet";
BA_ "FlexKomIsMotorola" SG_ 1098 VC_SpdLmt_PRSNT 1;
BA_ "FlexKomSID" SG_ 1098 VC_SpdLmt_PRSNT 1198;
BA_ "FlexKomSigLaenge" SG_ 1098 VC_SpdLmt_PRSNT 64;
BA_ "FlexKomSigName" SG_ 1098 VC_SpdLmt_PRSNT "VehCfg5_Pkt";
BA_ "FlexKomSigStartPos" SG_ 1098 VC_SpdLmt_PRSNT 7;
BA_ "FlexKomSigStartValue" SG_ 1098 VC_SpdLmt_PRSNT "C3FFFFFFFFFFFF00h";
BA_ "GenSigCycleTime" SG_ 1098 VC_SpdLmt_PRSNT 2000;
BA_ "GenSigSendType" SG_ 1098 VC_SpdLmt_PRSNT 5;
BA_ "GenSigSNA" SG_ 1098 VC_SpdLmt_PRSNT "0h";
BA_ "GenSigTimeout_IC" SG_ 1098 VC_SpdLmt_PRSNT 21000;
BA_ "GenSigTimeout_ORC" SG_ 1098 VC_SpdLmt_PRSNT 7000;
BA_ "FlexKomComment" SG_ 1098 VC_Strng_Rt_0 "Vehicle Configuration 5 Packet";
BA_ "FlexKomIsMotorola" SG_ 1098 VC_Strng_Rt_0 1;
BA_ "FlexKomSID" SG_ 1098 VC_Strng_Rt_0 1198;
BA_ "FlexKomSigLaenge" SG_ 1098 VC_Strng_Rt_0 64;
BA_ "FlexKomSigName" SG_ 1098 VC_Strng_Rt_0 "VehCfg5_Pkt";
BA_ "FlexKomSigStartPos" SG_ 1098 VC_Strng_Rt_0 7;
BA_ "FlexKomSigStartValue" SG_ 1098 VC_Strng_Rt_0 "C3FFFFFFFFFFFF00h";
BA_ "GenSigCycleTime" SG_ 1098 VC_Strng_Rt_0 2000;
BA_ "GenSigSendType" SG_ 1098 VC_Strng_Rt_0 5;
BA_ "GenSigSNA" SG_ 1098 VC_Strng_Rt_0 "FFh";
BA_ "GenSigStartValue" SG_ 1098 VC_Strng_Rt_0 255;
BA_ "FlexKomComment" SG_ 1098 VC_Strng_Rt_pls1 "Vehicle Configuration 5 Packet";
BA_ "FlexKomIsMotorola" SG_ 1098 VC_Strng_Rt_pls1 1;
BA_ "FlexKomSID" SG_ 1098 VC_Strng_Rt_pls1 1198;
BA_ "FlexKomSigLaenge" SG_ 1098 VC_Strng_Rt_pls1 64;
BA_ "FlexKomSigName" SG_ 1098 VC_Strng_Rt_pls1 "VehCfg5_Pkt";
BA_ "FlexKomSigStartPos" SG_ 1098 VC_Strng_Rt_pls1 7;
BA_ "FlexKomSigStartValue" SG_ 1098 VC_Strng_Rt_pls1 "C3FFFFFFFFFFFF00h";
BA_ "GenSigCycleTime" SG_ 1098 VC_Strng_Rt_pls1 2000;
BA_ "GenSigSendType" SG_ 1098 VC_Strng_Rt_pls1 5;
BA_ "GenSigSNA" SG_ 1098 VC_Strng_Rt_pls1 "FFh";
BA_ "GenSigStartValue" SG_ 1098 VC_Strng_Rt_pls1 255;
BA_ "FlexKomComment" SG_ 1098 VC_Strng_Rt_pls2 "Vehicle Configuration 5 Packet";
BA_ "FlexKomIsMotorola" SG_ 1098 VC_Strng_Rt_pls2 1;
BA_ "FlexKomSID" SG_ 1098 VC_Strng_Rt_pls2 1198;
BA_ "FlexKomSigLaenge" SG_ 1098 VC_Strng_Rt_pls2 64;
BA_ "FlexKomSigName" SG_ 1098 VC_Strng_Rt_pls2 "VehCfg5_Pkt";
BA_ "FlexKomSigStartPos" SG_ 1098 VC_Strng_Rt_pls2 7;
BA_ "FlexKomSigStartValue" SG_ 1098 VC_Strng_Rt_pls2 "C3FFFFFFFFFFFF00h";
BA_ "GenSigCycleTime" SG_ 1098 VC_Strng_Rt_pls2 2000;
BA_ "GenSigSendType" SG_ 1098 VC_Strng_Rt_pls2 5;
BA_ "GenSigSNA" SG_ 1098 VC_Strng_Rt_pls2 "FFh";
BA_ "GenSigStartValue" SG_ 1098 VC_Strng_Rt_pls2 255;
BA_ "FlexKomComment" SG_ 1098 VC_Strng_Rt_pls3 "Vehicle Configuration 5 Packet";
BA_ "FlexKomIsMotorola" SG_ 1098 VC_Strng_Rt_pls3 1;
BA_ "FlexKomSID" SG_ 1098 VC_Strng_Rt_pls3 1198;
BA_ "FlexKomSigLaenge" SG_ 1098 VC_Strng_Rt_pls3 64;
BA_ "FlexKomSigName" SG_ 1098 VC_Strng_Rt_pls3 "VehCfg5_Pkt";
BA_ "FlexKomSigStartPos" SG_ 1098 VC_Strng_Rt_pls3 7;
BA_ "FlexKomSigStartValue" SG_ 1098 VC_Strng_Rt_pls3 "C3FFFFFFFFFFFF00h";
BA_ "GenSigCycleTime" SG_ 1098 VC_Strng_Rt_pls3 2000;
BA_ "GenSigSendType" SG_ 1098 VC_Strng_Rt_pls3 5;
BA_ "GenSigSNA" SG_ 1098 VC_Strng_Rt_pls3 "FFh";
BA_ "GenSigStartValue" SG_ 1098 VC_Strng_Rt_pls3 255;
BA_ "FlexKomComment" SG_ 1098 VC_Strng_Rt_pls4 "Vehicle Configuration 5 Packet";
BA_ "FlexKomIsMotorola" SG_ 1098 VC_Strng_Rt_pls4 1;
BA_ "FlexKomSID" SG_ 1098 VC_Strng_Rt_pls4 1198;
BA_ "FlexKomSigLaenge" SG_ 1098 VC_Strng_Rt_pls4 64;
BA_ "FlexKomSigName" SG_ 1098 VC_Strng_Rt_pls4 "VehCfg5_Pkt";
BA_ "FlexKomSigStartPos" SG_ 1098 VC_Strng_Rt_pls4 7;
BA_ "FlexKomSigStartValue" SG_ 1098 VC_Strng_Rt_pls4 "C3FFFFFFFFFFFF00h";
BA_ "GenSigCycleTime" SG_ 1098 VC_Strng_Rt_pls4 2000;
BA_ "GenSigSendType" SG_ 1098 VC_Strng_Rt_pls4 5;
BA_ "GenSigSNA" SG_ 1098 VC_Strng_Rt_pls4 "FFh";
BA_ "GenSigStartValue" SG_ 1098 VC_Strng_Rt_pls4 255;
BA_ "FlexKomComment" SG_ 1098 VC_Strng_Rt_pls5 "Vehicle Configuration 5 Packet";
BA_ "FlexKomIsMotorola" SG_ 1098 VC_Strng_Rt_pls5 1;
BA_ "FlexKomSID" SG_ 1098 VC_Strng_Rt_pls5 1198;
BA_ "FlexKomSigLaenge" SG_ 1098 VC_Strng_Rt_pls5 64;
BA_ "FlexKomSigName" SG_ 1098 VC_Strng_Rt_pls5 "VehCfg5_Pkt";
BA_ "FlexKomSigStartPos" SG_ 1098 VC_Strng_Rt_pls5 7;
BA_ "FlexKomSigStartValue" SG_ 1098 VC_Strng_Rt_pls5 "C3FFFFFFFFFFFF00h";
BA_ "GenSigCycleTime" SG_ 1098 VC_Strng_Rt_pls5 2000;
BA_ "GenSigSendType" SG_ 1098 VC_Strng_Rt_pls5 5;
BA_ "GenSigSNA" SG_ 1098 VC_Strng_Rt_pls5 "FFh";
BA_ "GenSigStartValue" SG_ 1098 VC_Strng_Rt_pls5 255;
BA_ "FlexKomComment" SG_ 1098 VC_VehCfg5_Stat "Vehicle Configuration 5 Packet";
BA_ "FlexKomIsMotorola" SG_ 1098 VC_VehCfg5_Stat 1;
BA_ "FlexKomSID" SG_ 1098 VC_VehCfg5_Stat 1198;
BA_ "FlexKomSigLaenge" SG_ 1098 VC_VehCfg5_Stat 64;
BA_ "FlexKomSigName" SG_ 1098 VC_VehCfg5_Stat "VehCfg5_Pkt";
BA_ "FlexKomSigStartPos" SG_ 1098 VC_VehCfg5_Stat 7;
BA_ "FlexKomSigStartValue" SG_ 1098 VC_VehCfg5_Stat "C3FFFFFFFFFFFF00h";
BA_ "GenSigCycleTime" SG_ 1098 VC_VehCfg5_Stat 2000;
BA_ "GenSigSendType" SG_ 1098 VC_VehCfg5_Stat 5;
BA_ "GenSigSNA" SG_ 1098 VC_VehCfg5_Stat "3h";
BA_ "GenSigStartValue" SG_ 1098 VC_VehCfg5_Stat 3;
BA_ "GenSigTimeout_EPS" SG_ 1098 VC_VehCfg5_Stat 21000;
BA_ "GenSigTimeout_IC" SG_ 1098 VC_VehCfg5_Stat 21000;
BA_ "GenSigTimeout_ORC" SG_ 1098 VC_VehCfg5_Stat 7000;
BA_ "GenSigTimeout_PTS" SG_ 1098 VC_VehCfg5_Stat 21000;
BA_ "FlexKomComment" SG_ 1098 VC_WTS_Prsnt "Vehicle Configuration 5 Packet";
BA_ "FlexKomIsMotorola" SG_ 1098 VC_WTS_Prsnt 1;
BA_ "FlexKomSID" SG_ 1098 VC_WTS_Prsnt 1198;
BA_ "FlexKomSigLaenge" SG_ 1098 VC_WTS_Prsnt 64;
BA_ "FlexKomSigName" SG_ 1098 VC_WTS_Prsnt "VehCfg5_Pkt";
BA_ "FlexKomSigStartPos" SG_ 1098 VC_WTS_Prsnt 7;
BA_ "FlexKomSigStartValue" SG_ 1098 VC_WTS_Prsnt "C3FFFFFFFFFFFF00h";
BA_ "GenSigCycleTime" SG_ 1098 VC_WTS_Prsnt 2000;
BA_ "GenSigSendType" SG_ 1098 VC_WTS_Prsnt 5;
BA_ "GenSigSNA" SG_ 1098 VC_WTS_Prsnt "0h";
BA_ "FlexKomComment" SG_ 897 VC_ABSM "Vehicle Configuration 7 Packet";
BA_ "FlexKomIsMotorola" SG_ 897 VC_ABSM 1;
BA_ "FlexKomSID" SG_ 897 VC_ABSM 2026;
BA_ "FlexKomSigLaenge" SG_ 897 VC_ABSM 64;
BA_ "FlexKomSigName" SG_ 897 VC_ABSM "VehCfg7_Pkt";
BA_ "FlexKomSigStartPos" SG_ 897 VC_ABSM 7;
BA_ "FlexKomSigStartValue" SG_ 897 VC_ABSM "033F000000000000h";
BA_ "GenSigCycleTime" SG_ 897 VC_ABSM 2000;
BA_ "GenSigSendType" SG_ 897 VC_ABSM 5;
BA_ "GenSigSNA" SG_ 897 VC_ABSM "0h";
BA_ "GenSigTimeout_HaLF" SG_ 897 VC_ABSM 21000;
BA_ "GenSigTimeout_IC" SG_ 897 VC_ABSM 21000;
BA_ "FlexKomComment" SG_ 897 VC_ACC_Type "Vehicle Configuration 7 Packet";
BA_ "FlexKomIsMotorola" SG_ 897 VC_ACC_Type 1;
BA_ "FlexKomSID" SG_ 897 VC_ACC_Type 2026;
BA_ "FlexKomSigLaenge" SG_ 897 VC_ACC_Type 64;
BA_ "FlexKomSigName" SG_ 897 VC_ACC_Type "VehCfg7_Pkt";
BA_ "FlexKomSigStartPos" SG_ 897 VC_ACC_Type 7;
BA_ "FlexKomSigStartValue" SG_ 897 VC_ACC_Type "033F000000000000h";
BA_ "GenSigCycleTime" SG_ 897 VC_ACC_Type 2000;
BA_ "GenSigSendType" SG_ 897 VC_ACC_Type 5;
BA_ "GenSigSNA" SG_ 897 VC_ACC_Type "0h";
BA_ "GenSigTimeout_ORC" SG_ 897 VC_ACC_Type 7000;
BA_ "FlexKomComment" SG_ 897 VC_AS_ERS "Vehicle Configuration 7 Packet";
BA_ "FlexKomIsMotorola" SG_ 897 VC_AS_ERS 1;
BA_ "FlexKomSID" SG_ 897 VC_AS_ERS 2026;
BA_ "FlexKomSigLaenge" SG_ 897 VC_AS_ERS 64;
BA_ "FlexKomSigName" SG_ 897 VC_AS_ERS "VehCfg7_Pkt";
BA_ "FlexKomSigStartPos" SG_ 897 VC_AS_ERS 7;
BA_ "FlexKomSigStartValue" SG_ 897 VC_AS_ERS "033F000000000000h";
BA_ "GenSigCycleTime" SG_ 897 VC_AS_ERS 2000;
BA_ "GenSigSendType" SG_ 897 VC_AS_ERS 5;
BA_ "GenSigSNA" SG_ 897 VC_AS_ERS "3h";
BA_ "GenSigTimeout_IC" SG_ 897 VC_AS_ERS 21000;
BA_ "FlexKomComment" SG_ 897 VC_AxleLockerPrsnt "Vehicle Configuration 7 Packet";
BA_ "FlexKomIsMotorola" SG_ 897 VC_AxleLockerPrsnt 1;
BA_ "FlexKomSID" SG_ 897 VC_AxleLockerPrsnt 2026;
BA_ "FlexKomSigLaenge" SG_ 897 VC_AxleLockerPrsnt 64;
BA_ "FlexKomSigName" SG_ 897 VC_AxleLockerPrsnt "VehCfg7_Pkt";
BA_ "FlexKomSigStartPos" SG_ 897 VC_AxleLockerPrsnt 7;
BA_ "FlexKomSigStartValue" SG_ 897 VC_AxleLockerPrsnt "033F000000000000h";
BA_ "GenSigCycleTime" SG_ 897 VC_AxleLockerPrsnt 2000;
BA_ "GenSigSendType" SG_ 897 VC_AxleLockerPrsnt 5;
BA_ "GenSigSNA" SG_ 897 VC_AxleLockerPrsnt "0h";
BA_ "FlexKomComment" SG_ 897 VC_DST_Present "Vehicle Configuration 7 Packet";
BA_ "FlexKomIsMotorola" SG_ 897 VC_DST_Present 1;
BA_ "FlexKomSID" SG_ 897 VC_DST_Present 2026;
BA_ "FlexKomSigLaenge" SG_ 897 VC_DST_Present 64;
BA_ "FlexKomSigName" SG_ 897 VC_DST_Present "VehCfg7_Pkt";
BA_ "FlexKomSigStartPos" SG_ 897 VC_DST_Present 7;
BA_ "FlexKomSigStartValue" SG_ 897 VC_DST_Present "033F000000000000h";
BA_ "GenSigCycleTime" SG_ 897 VC_DST_Present 2000;
BA_ "GenSigSendType" SG_ 897 VC_DST_Present 5;
BA_ "GenSigSNA" SG_ 897 VC_DST_Present "0h";
BA_ "GenSigTimeout_ORC" SG_ 897 VC_DST_Present 7000;
BA_ "RID" SG_ 897 VC_DST_Present "9791";
BA_ "FlexKomComment" SG_ 897 VC_DampingPrsnt "Vehicle Configuration 7 Packet";
BA_ "FlexKomIsMotorola" SG_ 897 VC_DampingPrsnt 1;
BA_ "FlexKomSID" SG_ 897 VC_DampingPrsnt 2026;
BA_ "FlexKomSigLaenge" SG_ 897 VC_DampingPrsnt 64;
BA_ "FlexKomSigName" SG_ 897 VC_DampingPrsnt "VehCfg7_Pkt";
BA_ "FlexKomSigStartPos" SG_ 897 VC_DampingPrsnt 7;
BA_ "FlexKomSigStartValue" SG_ 897 VC_DampingPrsnt "033F000000000000h";
BA_ "GenSigCycleTime" SG_ 897 VC_DampingPrsnt 2000;
BA_ "GenSigSendType" SG_ 897 VC_DampingPrsnt 5;
BA_ "GenSigSNA" SG_ 897 VC_DampingPrsnt "0h";
BA_ "GenSigTimeout_IC" SG_ 897 VC_DampingPrsnt 21000;
BA_ "FlexKomComment" SG_ 897 VC_FullSpeedRange_FCW "Vehicle Configuration 7 Packet";
BA_ "FlexKomIsMotorola" SG_ 897 VC_FullSpeedRange_FCW 1;
BA_ "FlexKomSID" SG_ 897 VC_FullSpeedRange_FCW 2026;
BA_ "FlexKomSigLaenge" SG_ 897 VC_FullSpeedRange_FCW 64;
BA_ "FlexKomSigName" SG_ 897 VC_FullSpeedRange_FCW "VehCfg7_Pkt";
BA_ "FlexKomSigStartPos" SG_ 897 VC_FullSpeedRange_FCW 7;
BA_ "FlexKomSigStartValue" SG_ 897 VC_FullSpeedRange_FCW "033F000000000000h";
BA_ "GenSigCycleTime" SG_ 897 VC_FullSpeedRange_FCW 2000;
BA_ "GenSigSendType" SG_ 897 VC_FullSpeedRange_FCW 5;
BA_ "GenSigSNA" SG_ 897 VC_FullSpeedRange_FCW "0h";
BA_ "GenSigTimeout_ORC" SG_ 897 VC_FullSpeedRange_FCW 7000;
BA_ "FlexKomComment" SG_ 897 VC_HybridType "Vehicle Configuration 7 Packet";
BA_ "FlexKomIsMotorola" SG_ 897 VC_HybridType 1;
BA_ "FlexKomSID" SG_ 897 VC_HybridType 2026;
BA_ "FlexKomSigLaenge" SG_ 897 VC_HybridType 64;
BA_ "FlexKomSigName" SG_ 897 VC_HybridType "VehCfg7_Pkt";
BA_ "FlexKomSigStartPos" SG_ 897 VC_HybridType 7;
BA_ "FlexKomSigStartValue" SG_ 897 VC_HybridType "033F000000000000h";
BA_ "GenSigCycleTime" SG_ 897 VC_HybridType 2000;
BA_ "GenSigSendType" SG_ 897 VC_HybridType 5;
BA_ "GenSigSNA" SG_ 897 VC_HybridType "0h";
BA_ "GenSigTimeout_ORC" SG_ 897 VC_HybridType 7000;
BA_ "RID" SG_ 897 VC_HybridType "9792";
BA_ "FlexKomComment" SG_ 897 VC_LDW "Vehicle Configuration 7 Packet";
BA_ "FlexKomIsMotorola" SG_ 897 VC_LDW 1;
BA_ "FlexKomSID" SG_ 897 VC_LDW 2026;
BA_ "FlexKomSigLaenge" SG_ 897 VC_LDW 64;
BA_ "FlexKomSigName" SG_ 897 VC_LDW "VehCfg7_Pkt";
BA_ "FlexKomSigStartPos" SG_ 897 VC_LDW 7;
BA_ "FlexKomSigStartValue" SG_ 897 VC_LDW "033F000000000000h";
BA_ "GenSigCycleTime" SG_ 897 VC_LDW 2000;
BA_ "GenSigSendType" SG_ 897 VC_LDW 5;
BA_ "GenSigSNA" SG_ 897 VC_LDW "0h";
BA_ "GenSigTimeout_ORC" SG_ 897 VC_LDW 7000;
BA_ "FlexKomComment" SG_ 897 VC_PBTyp "Vehicle Configuration 7 Packet";
BA_ "FlexKomIsMotorola" SG_ 897 VC_PBTyp 1;
BA_ "FlexKomSID" SG_ 897 VC_PBTyp 2026;
BA_ "FlexKomSigLaenge" SG_ 897 VC_PBTyp 64;
BA_ "FlexKomSigName" SG_ 897 VC_PBTyp "VehCfg7_Pkt";
BA_ "FlexKomSigStartPos" SG_ 897 VC_PBTyp 7;
BA_ "FlexKomSigStartValue" SG_ 897 VC_PBTyp "033F000000000000h";
BA_ "GenSigCycleTime" SG_ 897 VC_PBTyp 2000;
BA_ "GenSigSendType" SG_ 897 VC_PBTyp 5;
BA_ "GenSigSNA" SG_ 897 VC_PBTyp "7h";
BA_ "GenSigTimeout_ORC" SG_ 897 VC_PBTyp 7000;
BA_ "FlexKomComment" SG_ 897 VC_PdlsMdPrsnt "Vehicle Configuration 7 Packet";
BA_ "FlexKomIsMotorola" SG_ 897 VC_PdlsMdPrsnt 1;
BA_ "FlexKomSID" SG_ 897 VC_PdlsMdPrsnt 2026;
BA_ "FlexKomSigLaenge" SG_ 897 VC_PdlsMdPrsnt 64;
BA_ "FlexKomSigName" SG_ 897 VC_PdlsMdPrsnt "VehCfg7_Pkt";
BA_ "FlexKomSigStartPos" SG_ 897 VC_PdlsMdPrsnt 7;
BA_ "FlexKomSigStartValue" SG_ 897 VC_PdlsMdPrsnt "033F000000000000h";
BA_ "GenSigCycleTime" SG_ 897 VC_PdlsMdPrsnt 2000;
BA_ "GenSigSendType" SG_ 897 VC_PdlsMdPrsnt 5;
BA_ "GenSigSNA" SG_ 897 VC_PdlsMdPrsnt "0h";
BA_ "GenSigTimeout_IC" SG_ 897 VC_PdlsMdPrsnt 21000;
BA_ "FlexKomComment" SG_ 897 VC_RedKey "Vehicle Configuration 7 Packet";
BA_ "FlexKomIsMotorola" SG_ 897 VC_RedKey 1;
BA_ "FlexKomSID" SG_ 897 VC_RedKey 2026;
BA_ "FlexKomSigLaenge" SG_ 897 VC_RedKey 64;
BA_ "FlexKomSigName" SG_ 897 VC_RedKey "VehCfg7_Pkt";
BA_ "FlexKomSigStartPos" SG_ 897 VC_RedKey 7;
BA_ "FlexKomSigStartValue" SG_ 897 VC_RedKey "033F000000000000h";
BA_ "GenSigCycleTime" SG_ 897 VC_RedKey 2000;
BA_ "GenSigSendType" SG_ 897 VC_RedKey 5;
BA_ "GenSigSNA" SG_ 897 VC_RedKey "0h";
BA_ "GenSigTimeout_RF_HUB" SG_ 897 VC_RedKey 21000;
BA_ "FlexKomComment" SG_ 897 VC_STP_PRSNT "Vehicle Configuration 7 Packet";
BA_ "FlexKomIsMotorola" SG_ 897 VC_STP_PRSNT 1;
BA_ "FlexKomSID" SG_ 897 VC_STP_PRSNT 2026;
BA_ "FlexKomSigLaenge" SG_ 897 VC_STP_PRSNT 64;
BA_ "FlexKomSigName" SG_ 897 VC_STP_PRSNT "VehCfg7_Pkt";
BA_ "FlexKomSigStartPos" SG_ 897 VC_STP_PRSNT 7;
BA_ "FlexKomSigStartValue" SG_ 897 VC_STP_PRSNT "033F000000000000h";
BA_ "GenSigCycleTime" SG_ 897 VC_STP_PRSNT 2000;
BA_ "GenSigSendType" SG_ 897 VC_STP_PRSNT 5;
BA_ "GenSigSNA" SG_ 897 VC_STP_PRSNT "0h";
BA_ "GenSigTimeout_IC" SG_ 897 VC_STP_PRSNT 21000;
BA_ "FlexKomComment" SG_ 897 VC_SUNR_Prsnt "Vehicle Configuration 7 Packet";
BA_ "FlexKomIsMotorola" SG_ 897 VC_SUNR_Prsnt 1;
BA_ "FlexKomSID" SG_ 897 VC_SUNR_Prsnt 2026;
BA_ "FlexKomSigLaenge" SG_ 897 VC_SUNR_Prsnt 64;
BA_ "FlexKomSigName" SG_ 897 VC_SUNR_Prsnt "VehCfg7_Pkt";
BA_ "FlexKomSigStartPos" SG_ 897 VC_SUNR_Prsnt 7;
BA_ "FlexKomSigStartValue" SG_ 897 VC_SUNR_Prsnt "033F000000000000h";
BA_ "GenSigCycleTime" SG_ 897 VC_SUNR_Prsnt 2000;
BA_ "GenSigSendType" SG_ 897 VC_SUNR_Prsnt 5;
BA_ "GenSigSNA" SG_ 897 VC_SUNR_Prsnt "0h";
BA_ "FlexKomComment" SG_ 897 VC_SVC_Prsnt "Vehicle Configuration 7 Packet";
BA_ "FlexKomIsMotorola" SG_ 897 VC_SVC_Prsnt 1;
BA_ "FlexKomSID" SG_ 897 VC_SVC_Prsnt 2026;
BA_ "FlexKomSigLaenge" SG_ 897 VC_SVC_Prsnt 64;
BA_ "FlexKomSigName" SG_ 897 VC_SVC_Prsnt "VehCfg7_Pkt";
BA_ "FlexKomSigStartPos" SG_ 897 VC_SVC_Prsnt 7;
BA_ "FlexKomSigStartValue" SG_ 897 VC_SVC_Prsnt "033F000000000000h";
BA_ "GenSigCycleTime" SG_ 897 VC_SVC_Prsnt 2000;
BA_ "GenSigSendType" SG_ 897 VC_SVC_Prsnt 5;
BA_ "GenSigSNA" SG_ 897 VC_SVC_Prsnt "0h";
BA_ "FlexKomComment" SG_ 897 VC_SuspPrsnt "Vehicle Configuration 7 Packet";
BA_ "FlexKomIsMotorola" SG_ 897 VC_SuspPrsnt 1;
BA_ "FlexKomSID" SG_ 897 VC_SuspPrsnt 2026;
BA_ "FlexKomSigLaenge" SG_ 897 VC_SuspPrsnt 64;
BA_ "FlexKomSigName" SG_ 897 VC_SuspPrsnt "VehCfg7_Pkt";
BA_ "FlexKomSigStartPos" SG_ 897 VC_SuspPrsnt 7;
BA_ "FlexKomSigStartValue" SG_ 897 VC_SuspPrsnt "033F000000000000h";
BA_ "GenSigCycleTime" SG_ 897 VC_SuspPrsnt 2000;
BA_ "GenSigSendType" SG_ 897 VC_SuspPrsnt 5;
BA_ "GenSigSNA" SG_ 897 VC_SuspPrsnt "0h";
BA_ "GenSigTimeout_IC" SG_ 897 VC_SuspPrsnt 21000;
BA_ "FlexKomComment" SG_ 897 VC_TPMS_Configuration "Vehicle Configuration 7 Packet";
BA_ "FlexKomIsMotorola" SG_ 897 VC_TPMS_Configuration 1;
BA_ "FlexKomSID" SG_ 897 VC_TPMS_Configuration 2026;
BA_ "FlexKomSigLaenge" SG_ 897 VC_TPMS_Configuration 64;
BA_ "FlexKomSigName" SG_ 897 VC_TPMS_Configuration "VehCfg7_Pkt";
BA_ "FlexKomSigStartPos" SG_ 897 VC_TPMS_Configuration 7;
BA_ "FlexKomSigStartValue" SG_ 897 VC_TPMS_Configuration "033F000000000000h";
BA_ "GenSigCycleTime" SG_ 897 VC_TPMS_Configuration 2000;
BA_ "GenSigSendType" SG_ 897 VC_TPMS_Configuration 5;
BA_ "GenSigSNA" SG_ 897 VC_TPMS_Configuration "7h";
BA_ "GenSigTimeout_IC" SG_ 897 VC_TPMS_Configuration 21000;
BA_ "FlexKomComment" SG_ 897 VC_TSBM_Prsnt "Vehicle Configuration 7 Packet";
BA_ "FlexKomIsMotorola" SG_ 897 VC_TSBM_Prsnt 1;
BA_ "FlexKomSID" SG_ 897 VC_TSBM_Prsnt 2026;
BA_ "FlexKomSigLaenge" SG_ 897 VC_TSBM_Prsnt 64;
BA_ "FlexKomSigName" SG_ 897 VC_TSBM_Prsnt "VehCfg7_Pkt";
BA_ "FlexKomSigStartPos" SG_ 897 VC_TSBM_Prsnt 7;
BA_ "FlexKomSigStartValue" SG_ 897 VC_TSBM_Prsnt "033F000000000000h";
BA_ "GenSigCycleTime" SG_ 897 VC_TSBM_Prsnt 2000;
BA_ "GenSigSendType" SG_ 897 VC_TSBM_Prsnt 5;
BA_ "GenSigSNA" SG_ 897 VC_TSBM_Prsnt "0h";
BA_ "FlexKomComment" SG_ 897 VC_TeenKey "Vehicle Configuration 7 Packet";
BA_ "FlexKomIsMotorola" SG_ 897 VC_TeenKey 1;
BA_ "FlexKomSID" SG_ 897 VC_TeenKey 2026;
BA_ "FlexKomSigLaenge" SG_ 897 VC_TeenKey 64;
BA_ "FlexKomSigName" SG_ 897 VC_TeenKey "VehCfg7_Pkt";
BA_ "FlexKomSigStartPos" SG_ 897 VC_TeenKey 7;
BA_ "FlexKomSigStartValue" SG_ 897 VC_TeenKey "033F000000000000h";
BA_ "GenSigCycleTime" SG_ 897 VC_TeenKey 2000;
BA_ "GenSigSendType" SG_ 897 VC_TeenKey 5;
BA_ "GenSigSNA" SG_ 897 VC_TeenKey "0h";
BA_ "GenSigTimeout_RF_HUB" SG_ 897 VC_TeenKey 21000;
BA_ "FlexKomComment" SG_ 897 VC_Temp_Display_Resolution "Vehicle Configuration 7 Packet";
BA_ "FlexKomIsMotorola" SG_ 897 VC_Temp_Display_Resolution 1;
BA_ "FlexKomSID" SG_ 897 VC_Temp_Display_Resolution 2026;
BA_ "FlexKomSigLaenge" SG_ 897 VC_Temp_Display_Resolution 64;
BA_ "FlexKomSigName" SG_ 897 VC_Temp_Display_Resolution "VehCfg7_Pkt";
BA_ "FlexKomSigStartPos" SG_ 897 VC_Temp_Display_Resolution 7;
BA_ "FlexKomSigStartValue" SG_ 897 VC_Temp_Display_Resolution "033F000000000000h";
BA_ "GenSigCycleTime" SG_ 897 VC_Temp_Display_Resolution 2000;
BA_ "GenSigSendType" SG_ 897 VC_Temp_Display_Resolution 5;
BA_ "GenSigSNA" SG_ 897 VC_Temp_Display_Resolution "0h";
BA_ "FlexKomComment" SG_ 897 VC_TransType "Vehicle Configuration 7 Packet";
BA_ "FlexKomIsMotorola" SG_ 897 VC_TransType 1;
BA_ "FlexKomSID" SG_ 897 VC_TransType 2026;
BA_ "FlexKomSigLaenge" SG_ 897 VC_TransType 64;
BA_ "FlexKomSigName" SG_ 897 VC_TransType "VehCfg7_Pkt";
BA_ "FlexKomSigStartPos" SG_ 897 VC_TransType 7;
BA_ "FlexKomSigStartValue" SG_ 897 VC_TransType "033F000000000000h";
BA_ "GenSigCycleTime" SG_ 897 VC_TransType 2000;
BA_ "GenSigSendType" SG_ 897 VC_TransType 5;
BA_ "GenSigSNA" SG_ 897 VC_TransType "3Fh";
BA_ "GenSigStartValue" SG_ 897 VC_TransType 63;
BA_ "GenSigTimeout_IC" SG_ 897 VC_TransType 21000;
BA_ "FlexKomComment" SG_ 897 VC_Trans_Equipped "Vehicle Configuration 7 Packet";
BA_ "FlexKomIsMotorola" SG_ 897 VC_Trans_Equipped 1;
BA_ "FlexKomSID" SG_ 897 VC_Trans_Equipped 2026;
BA_ "FlexKomSigLaenge" SG_ 897 VC_Trans_Equipped 64;
BA_ "FlexKomSigName" SG_ 897 VC_Trans_Equipped "VehCfg7_Pkt";
BA_ "FlexKomSigStartPos" SG_ 897 VC_Trans_Equipped 7;
BA_ "FlexKomSigStartValue" SG_ 897 VC_Trans_Equipped "033F000000000000h";
BA_ "GenSigCycleTime" SG_ 897 VC_Trans_Equipped 2000;
BA_ "GenSigSendType" SG_ 897 VC_Trans_Equipped 5;
BA_ "GenSigSNA" SG_ 897 VC_Trans_Equipped "0h";
BA_ "GenSigTimeout_ORC" SG_ 897 VC_Trans_Equipped 7000;
BA_ "RID" SG_ 897 VC_Trans_Equipped "9793";
BA_ "FlexKomComment" SG_ 897 VC_Trans_N_Hold_Prsnt "Vehicle Configuration 7 Packet";
BA_ "FlexKomIsMotorola" SG_ 897 VC_Trans_N_Hold_Prsnt 1;
BA_ "FlexKomSID" SG_ 897 VC_Trans_N_Hold_Prsnt 2026;
BA_ "FlexKomSigLaenge" SG_ 897 VC_Trans_N_Hold_Prsnt 64;
BA_ "FlexKomSigName" SG_ 897 VC_Trans_N_Hold_Prsnt "VehCfg7_Pkt";
BA_ "FlexKomSigStartPos" SG_ 897 VC_Trans_N_Hold_Prsnt 7;
BA_ "FlexKomSigStartValue" SG_ 897 VC_Trans_N_Hold_Prsnt "033F000000000000h";
BA_ "GenSigCycleTime" SG_ 897 VC_Trans_N_Hold_Prsnt 2000;
BA_ "GenSigSendType" SG_ 897 VC_Trans_N_Hold_Prsnt 5;
BA_ "GenSigSNA" SG_ 897 VC_Trans_N_Hold_Prsnt "0h";
BA_ "FlexKomComment" SG_ 897 VC_TrnsDrvMdPrsnt "Vehicle Configuration 7 Packet";
BA_ "FlexKomIsMotorola" SG_ 897 VC_TrnsDrvMdPrsnt 1;
BA_ "FlexKomSID" SG_ 897 VC_TrnsDrvMdPrsnt 2026;
BA_ "FlexKomSigLaenge" SG_ 897 VC_TrnsDrvMdPrsnt 64;
BA_ "FlexKomSigName" SG_ 897 VC_TrnsDrvMdPrsnt "VehCfg7_Pkt";
BA_ "FlexKomSigStartPos" SG_ 897 VC_TrnsDrvMdPrsnt 7;
BA_ "FlexKomSigStartValue" SG_ 897 VC_TrnsDrvMdPrsnt "033F000000000000h";
BA_ "GenSigCycleTime" SG_ 897 VC_TrnsDrvMdPrsnt 2000;
BA_ "GenSigSendType" SG_ 897 VC_TrnsDrvMdPrsnt 5;
BA_ "GenSigSNA" SG_ 897 VC_TrnsDrvMdPrsnt "0h";
BA_ "GenSigTimeout_IC" SG_ 897 VC_TrnsDrvMdPrsnt 21000;
BA_ "FlexKomComment" SG_ 897 VC_VehCfg7_Stat "Vehicle Configuration 7 Packet";
BA_ "FlexKomIsMotorola" SG_ 897 VC_VehCfg7_Stat 1;
BA_ "FlexKomSID" SG_ 897 VC_VehCfg7_Stat 2026;
BA_ "FlexKomSigLaenge" SG_ 897 VC_VehCfg7_Stat 64;
BA_ "FlexKomSigName" SG_ 897 VC_VehCfg7_Stat "VehCfg7_Pkt";
BA_ "FlexKomSigStartPos" SG_ 897 VC_VehCfg7_Stat 7;
BA_ "FlexKomSigStartValue" SG_ 897 VC_VehCfg7_Stat "033F000000000000h";
BA_ "GenSigCycleTime" SG_ 897 VC_VehCfg7_Stat 2000;
BA_ "GenSigSendType" SG_ 897 VC_VehCfg7_Stat 5;
BA_ "GenSigSNA" SG_ 897 VC_VehCfg7_Stat "3h";
BA_ "GenSigStartValue" SG_ 897 VC_VehCfg7_Stat 3;
BA_ "GenSigTimeout_IC" SG_ 897 VC_VehCfg7_Stat 21000;
BA_ "GenSigTimeout_ORC" SG_ 897 VC_VehCfg7_Stat 7000;
BA_ "RID" SG_ 897 VC_VehCfg7_Stat "9991";
BA_ "FlexKomComment" SG_ 897 VC_eShifter_Prsnt "Vehicle Configuration 7 Packet";
BA_ "FlexKomIsMotorola" SG_ 897 VC_eShifter_Prsnt 1;
BA_ "FlexKomSID" SG_ 897 VC_eShifter_Prsnt 2026;
BA_ "FlexKomSigLaenge" SG_ 897 VC_eShifter_Prsnt 64;
BA_ "FlexKomSigName" SG_ 897 VC_eShifter_Prsnt "VehCfg7_Pkt";
BA_ "FlexKomSigStartPos" SG_ 897 VC_eShifter_Prsnt 7;
BA_ "FlexKomSigStartValue" SG_ 897 VC_eShifter_Prsnt "033F000000000000h";
BA_ "GenSigCycleTime" SG_ 897 VC_eShifter_Prsnt 2000;
BA_ "GenSigSendType" SG_ 897 VC_eShifter_Prsnt 5;
BA_ "GenSigSNA" SG_ 897 VC_eShifter_Prsnt "0h";
BA_ "GenSigTimeout_RF_HUB" SG_ 897 VC_eShifter_Prsnt 21000;
VAL_ 258 LRW 16383 "SNA" ;
VAL_ 258 LRWS_ST 0 "OK" 1 "INI" 2 "ERR" 3 "ERR_INI" ;
VAL_ 258 VLRW 16383 "SNA" ;
VAL_ 719 PPPA_STAT 0 "OFF" 1 "CONT" 2 "BLINK" 3 "SNA" ;
VAL_ 792 HiBmLvr_Stat 0 "IDLE" 1 "HIBM_ON_PSD" 2 "HIBM_FLSH_ON_PSD" ;
VAL_ 792 TurnIndLvr_Stat 0 "IDLE" 1 "LEFT" 2 "RIGHT" ;
VAL_ 792 WprSw6Posn 0 "OFF" 1 "INTERVAL1" 2 "INTERVAL2" 3 "INTERVAL3" 4 "INTERVAL4" 5 "INTERVAL5" 6 "INTERVAL6" 13 "WPR_LOW" 14 "WPR_HI" 15 "SNA" ;
VAL_ 792 WprWashSw_Psd 0 "NPSD" 1 "MIST" 2 "WASH" ;
VAL_ 792 WprWash_R_Sw_Posn_V3 0 "OFF" 1 "INTERMITTENT" 2 "WASH" 3 "CONSTANT" ;
VAL_ 680 CurrentGear 0 "N" 1 "D1" 2 "D2" 3 "D3" 4 "D4" 5 "D5" 6 "D6" 7 "D7" 8 "D8" 9 "D2P" 10 "D9" 11 "R" 12 "R2" 13 "P" 14 "KRAFTFREI" 15 "SNA" ;
VAL_ 680 HCPShutDwnCmd 0 "default" 1 "Initiate_Powerdown" 2 "Shutdown" 3 "Cancel_Powerdown" 7 "SNA" ;
VAL_ 680 HCP_IMMO_STAT_CANC 0 "HCPIS" 1 "HCPKILL" 2 "HCPRUN" 3 "SNA" ;
VAL_ 680 TCM_Vehicle_Hold_Rq 0 "NA" 1 "ACTIVE" 3 "SNA" ;
VAL_ 680 TX_WARN2 0 "None" 1 "WARN_1" 2 "WARN_2" 3 "WARN_3" 4 "WARN_4" 5 "WARN_5" 6 "WARN_6" 7 "WARN_7" 8 "WARN_8" 9 "WARN_9" 10 "WARN_10" 11 "WARN_11" 12 "WARN_12" 13 "WARN_13" 14 "WARN_14" 15 "WARN_15" 17 "WARN_17" 18 "WARN_18" 19 "WARN_19" 20 "WARN_20" 21 "WARN_21" 22 "WARN_22" 23 "WARN_23" 24 "WARN_24" 25 "WARN_25" 31 "WARN_31" 32 "WARN_32" 33 "WARN_33" 34 "WARN_34" 35 "WARN_35" 36 "WARN_36" 37 "WARN_37" 38 "WARN_38" 39 "WARN_39" 40 "WARN_40" 41 "WARN_41" 42 "WARN_42" 43 "WARN_43" 44 "WARN_44" 45 "WARN_45" 46 "WARN_46" 47 "WARN_47" 48 "WARN_48" 49 "WARN_49" 50 "WARN_50" 51 "WARN_51" 52 "WARN_52" 53 "WARN_53" 54 "WARN_54" 55 "WARN_55" 56 "WARN_56" 57 "WARN_57" 58 "WARN_58" 59 "WARN_59" 60 "WARN_60" 61 "WARN_61" 62 "WARN_62" 63 "WARN_63" 64 "WARN_64" 65 "WARN_65" 66 "WARN_66" 67 "WARN_67" 68 "WARN_68" 255 "SNA" ;
VAL_ 680 TargetGear 0 "N" 1 "D1" 2 "D2" 3 "D3" 4 "D4" 5 "D5" 6 "D6" 7 "D7" 8 "D8" 9 "D2P" 10 "D9" 11 "R" 12 "R2" 13 "P" 14 "ABBRUCH" 15 "SNA" ;
VAL_ 324 Gr 0 "N" 1 "D1" 2 "D2" 3 "D3" 4 "D4" 5 "D5" 6 "D6" 7 "D7" 8 "D8" 9 "D2P" 10 "D9" 11 "R" 12 "R2" 13 "P" 14 "KRAFTFREI" 15 "SNA" ;
VAL_ 324 Gr_Target 0 "N" 1 "D1" 2 "D2" 3 "D3" 4 "D4" 5 "D5" 6 "D6" 7 "D7" 8 "D8" 9 "D2P" 10 "D9" 11 "R" 12 "R2" 13 "P" 14 "ABBRUCH" 15 "SNA" ;
VAL_ 324 OUTPUT_SPEED 65535 "SNA" ;
VAL_ 368 APCM_Rq 0 "OFF" 1 "ON" 2 "PENDING" 3 "SNA" ;
VAL_ 368 PRNDL_Blink 0 "NONE" 1 "P" 2 "R" 3 "N" 4 "D" 5 "L" 6 "S" 7 "M_TIP" ;
VAL_ 368 PRNDL_DISP 32 "BLANK" 49 "ONE" 50 "TWO" 51 "THREE" 52 "FOUR" 53 "FIVE" 54 "SIX" 55 "SEVEN" 56 "EIGHT" 57 "NINE" 65 "A" 68 "D" 70 "F" 76 "L" 77 "M" 78 "N" 80 "P" 82 "R" 83 "S" 128 "DS" 130 "D2" 131 "D3" 132 "D4" 133 "D5" 135 "SNOW" 254 "NOT_N" 255 "SNA" ;
VAL_ 368 PRND_STAT 0 "LVR_P" 1 "LVR_R" 2 "LVR_N" 4 "LVR_D" 5 "NOT_R" 7 "SNA" ;
VAL_ 368 SHFT_PROG 1 "LOW" 2 "SSC" 3 "HDC" 4 "TRACK" 5 "VALET" 7 "SNOW" 11 "MUD" 12 "SAND" 16 "SKIP_SHFT" 24 "UPSHIFT_IND_RQ" 32 "BLANK" 64 "E_MODE" 65 "A" 77 "M" 83 "S" 87 "W" 250 "Sport_Plus" 251 "TX_SPORT" 252 "TX_NORM" 253 "OD_OFF" 254 "TX_TOW" 255 "SNA" ;
VAL_ 992 VIN_MSG 0 "VIN_LO" 1 "VIN_MID" 2 "VIN_HI" 3 "SNA" ;
VAL_ 1000 VC_BODY_STYLE 0 "BODY_NONE" 1 "BODY_4DS" 2 "BODY_2DS" 3 "BODY_CONV" 4 "BODY_WAGON" 5 "BODY_4DH" 6 "BODY_2DP" 7 "BODY_4DP" 8 "BODY_4DMP" 15 "BODY_SNA" ;
VAL_ 1000 VC_COUNTRY 0 "ROW" 2 "USA" 3 "EU" 4 "CND" 5 "GB" 6 "JPN" 7 "GER" 8 "SWISS" 9 "MLY" 10 "AUS" 11 "IND" 12 "GULF" 13 "VEN" 14 "MEX" 15 "BRZ" 16 "CHINA" 17 "EGYPT" 20 "S_KOR" 21 "ECE" 31 "COUNTRY_SNA" ;
VAL_ 1000 VC_LHD_RHD 0 "NA" 1 "LHD" 2 "RHD" 3 "SNA" ;
VAL_ 1000 VC_MAX_VEH_SPD 255 "SNA" ;
VAL_ 1000 VC_MODEL_YEAR 63 "SNA" ;
VAL_ 1000 VC_PTS_Config 0 "REAR" 1 "FRT_REAR" 3 "SEMI" ;
VAL_ 1000 VC_PTS_DispTyp 0 "HEAD_DISP" 1 "CCN_DISP" 2 "AUDIO_DISP" 7 "SNA" ;
VAL_ 1000 VC_ShftrTyp 0 "TYPE_NA" 1 "TYPE_ERS4" 2 "TYPE_AS4" 3 "TYPE_ERS5" 4 "TYPE_AS5" 5 "TYPE_RS5M" 6 "TYPE_RS5S" 7 "TYPE_RS5L" 8 "TYPE_ERS4ESW" 9 "TYPE_MS7D" 10 "TYPE_MS7M156" 11 "TYPE_RS4" 12 "TYPE_MS7S" 13 "TYPE_MS7" 14 "TYPE_PS5" 15 "SNA" ;
VAL_ 1000 VC_SpecialPKG 0 "NONE" 255 "SNA" ;
VAL_ 1000 VC_VEH_LINE 0 "VEH_NONE" 1 "VEH_WK" 2 "VEH_LX" 22 "VEH_JC" 29 "VEH_DS" 31 "VEH_D2" 32 "VEH_DD" 33 "VEH_DP" 34 "VEH_DJ" 35 "VEH_WD" 39 "VEH_DX" 41 "VEH_LD" 42 "VEH_M156" 43 "VEH_ZD" 44 "VEH_LA" 45 "VEH_RU" 46 "VEH_M161" 47 "VEH_WS" 48 "VEH_DF" 49 "VEH_JL" 50 "VEH_M157" 51 "VEH_RA" 52 "VEH_WL" 53 "VEH_DT" 54 "VEH_DU" 80 "VEH_PF" 81 "VEH_KL" 82 "VEH_UF" 83 "VEH_UT" 255 "SNA" ;
VAL_ 1000 VC_VehCfg1_Stat 0 "NA" 1 "PROGAMMED" 2 "REQUEST_DATA" 3 "SNA" ;
VAL_ 1000 VC_XWD 0 "2FT" 1 "2RR" 2 "ALLWD" 3 "4WD" ;
VAL_ 1001 VC_LgtLdPressFtTr 255 "SNA" ;
VAL_ 1001 VC_LgtLdPressRrTr 255 "SNA" ;
VAL_ 1001 VC_MaseratiMd 0 "NORMAL" 1 "GTS" 2 "RACE" 3 "SNA" ;
VAL_ 1001 VC_MaxLdPressFtTr 255 "SNA" ;
VAL_ 1001 VC_MaxLdPressRrTr 255 "SNA" ;
VAL_ 1001 VC_PwrIvtrTyp 0 "NoPwrIvtr" 1 "MtrySw" 2 "LchSw" ;
VAL_ 1001 VC_ShftInd_Prsnt 0 "NONE" 1 "GSI" 2 "PSI" 3 "PGSI" ;
VAL_ 1001 VC_SpecialPKG_IC 0 "NONE" 1 "PKG_70JP" 2 "PKG_300S" 3 "PKG_BEATS" 4 "PKG_SUPERBEE" 5 "MOPAR" 6 "Hellcat" 7 "Shaker" 8 "Scat" 16 "LARAMIE" 17 "BIGHORN" 18 "LONGHORN" 19 "LONESTAR" 20 "LIMITED" 21 "MOSSY_OAK" 22 "ORT" 23 "POWERWAGON" 24 "HD_DX" 25 "SPORT" 26 "PWGN_Laramie" 27 "RAM_1500" 28 "PWGN_GOODYEAR" 100 "WRANGLER_SPORT" 101 "WRANGLER_SAHARA" 102 "WRANGLER_RUBICON" 246 "DODGE_100" 247 "VARVATOS" 255 "SNA" ;
VAL_ 1001 VC_VehCfg2_Stat 0 "NA" 1 "PROGAMMED" 2 "REQUEST_DATA" 3 "SNA" ;
VAL_ 1002 VC_ChassisType 127 "SNA" ;
VAL_ 1002 VC_FUEL_CAP 255 "SNA" ;
VAL_ 1002 VC_HVAC_Config 0 "1_ZN_MTC" 1 "1_ZN_MTC_p_RR" 2 "1_ZN_ATC" 3 "2_ZN_MTC" 4 "2_ZN_ATC" 5 "2_ZN_ATC_p_RR" 6 "2_ZN_MTC_p_RR" 15 "SNA" ;
VAL_ 1002 VC_Liftgate_Trunk 0 "TRUNK" 1 "PLG" 2 "MANUAL_LG" 3 "SNA" ;
VAL_ 1002 VC_TcaseTyp 0 "NOT_PRSNT" 1 "TCASE_143_144" 2 "BW4445_46_48_WS" 3 "Tcase_253_1522" 4 "Tcase_BW4444" 5 "Tcase_BW4446" 6 "Tcase_MPT3025C" 7 "Tcase_241_MPT1222C" 8 "BW4447_WOS" 9 "Tcase_243" 10 "BW4447_49_WS" 11 "Tcase_273" 12 "Tcase_MAS_ATC" 13 "Tcase_BW4440" 14 "Tcase_156" 15 "Tcase_256_3022" ;
VAL_ 1002 VC_VEH_BRAND 1 "CHRYSLER" 2 "DODGE" 3 "JEEP" 4 "MERCEDES_BENZ" 5 "MITSUBISHI" 6 "VOLKSWAGEN" 7 "FREIGHTLINER" 8 "ALPHA" 9 "FIAT" 10 "LANCIA" 11 "MASERATI" 12 "RAM" 15 "SNA" ;
VAL_ 1002 VC_VehCfg3_Stat 0 "NA" 1 "PROGAMMED" 2 "REQUEST_DATA" 3 "SNA" ;
VAL_ 1002 VC_WHL_BASE 0 "SHORT" 1 "LONG" 2 "XLONG" 3 "SNA" ;
VAL_ 1002 VC_WIN_EXPR_FEAT 0 "WIN_EXPR_DRV" 1 "WIN_EXPR_FT" 2 "WIN_EXPR_ALL" 3 "WIN_EXPR_NN" ;
VAL_ 1003 VC_AXLE_RATIO 65535 "SNA" ;
VAL_ 1003 VC_TCASE_HI_RATIO 16383 "SNA" ;
VAL_ 1003 VC_TCASE_LO_RATIO 65535 "SNA" ;
VAL_ 1003 VC_TIRE_CIRCUMF 65535 "SNA" ;
VAL_ 1003 VC_VehCfg4_Stat 0 "NA" 1 "PROGAMMED" 2 "REQUEST_DATA" 3 "SNA" ;
VAL_ 1098 VC_AmbTempLct 0 "CBC" 1 "DCM" 3 "SNA" ;
VAL_ 1098 VC_Strng_Rt_0 255 "SNA" ;
VAL_ 1098 VC_Strng_Rt_pls1 255 "SNA" ;
VAL_ 1098 VC_Strng_Rt_pls2 255 "SNA" ;
VAL_ 1098 VC_Strng_Rt_pls3 255 "SNA" ;
VAL_ 1098 VC_Strng_Rt_pls4 255 "SNA" ;
VAL_ 1098 VC_Strng_Rt_pls5 255 "SNA" ;
VAL_ 1098 VC_VehCfg5_Stat 0 "NA" 1 "PROGAMMED" 2 "REQUEST_DATA" 3 "SNA" ;
VAL_ 897 VC_ACC_Type 0 "NONE" 1 "ACC" 2 "STOP" 3 "GO" ;
VAL_ 897 VC_AS_ERS 0 "NONE" 1 "ERS" 2 "AS" 3 "SNA" ;
VAL_ 897 VC_AxleLockerPrsnt 0 "NONE" 1 "REAR" 2 "FTRR" ;
VAL_ 897 VC_HybridType 0 "NONE" 1 "BEV" 2 "HEV" 3 "PHEV" 4 "BSG48" ;
VAL_ 897 VC_PBTyp 0 "MECH" 1 "EPB_MOC" 2 "EPB_CP" 3 "IMOC" 4 "ICP" 7 "SNA" ;
VAL_ 897 VC_TPMS_Configuration 0 "NHTSA" 1 "NAFTA" 2 "ECE" 3 "OTHER" 4 "CHINA" 7 "SNA" ;
VAL_ 897 VC_Temp_Display_Resolution 0 "One_Degree_C" 1 "Half_Degree_C" ;
VAL_ 897 VC_TransType 0 "NP" 1 "SI_EVT_Hybrid_Trans" 2 "MTA" 3 "c40TES" 4 "Aisin_LD" 5 "W5A580" 6 "c62TE" 7 "c65RFE" 8 "c66RFE" 9 "c68RFE" 10 "AISIN_HD" 11 "DDCT_C635" 12 "HPT_6F24" 13 "ZF_8Spd" 14 "ZF_9Spd" 63 "SNA" ;
VAL_ 897 VC_VehCfg7_Stat 0 "NA" 1 "PROGAMMED" 2 "REQUEST_DATA" 3 "SNA" ;
